VERSION ""

NS_ :

BS_:

BU_: VEH CH Receiver X odin VehicleBus ui

BO_ 965 DIS_alertMatrix3: 8 VEH
 SG_ DIS_a129_epbNotApplied : 0|1@1+ (1,0) [0|0] ""  X
 SG_ DIS_a131_highSpeedWearLimit : 2|1@1+ (1,0) [0|0] ""  X
 SG_ DIS_a133_capacitorOT : 4|1@1+ (1,0) [0|0] ""  X
 SG_ DIS_a134_wheelSpeedIrrational : 5|1@1+ (1,0) [0|0] ""  X
 SG_ DIS_a136_spiError : 7|1@1+ (1,0) [0|0] ""  X
 SG_ DIS_a142_highLashAngle : 13|1@1+ (1,0) [0|0] ""  X
 SG_ DIS_a143_mcuLimitActive : 14|1@1+ (1,0) [0|0] ""  X
 SG_ DIS_a144_configMismatch : 15|1@1+ (1,0) [0|0] ""  X
 SG_ DIS_a147_highTorqueWearLimit : 18|1@1+ (1,0) [0|0] ""  X
 SG_ DIS_a148_overtorqueUsed : 19|1@1+ (1,0) [0|0] ""  X
 SG_ DIS_a149_oilPumpFailure : 20|1@1+ (1,0) [0|0] ""  X
 SG_ DIS_a150_busVD : 21|1@1+ (1,0) [0|0] ""  X
 SG_ DIS_a151_shockTorqueLimiter : 22|1@1+ (1,0) [0|0] ""  X
 SG_ DIS_a152_linError : 23|1@1+ (1,0) [0|0] ""  X
 SG_ DIS_a153_oilPump : 24|1@1+ (1,0) [0|0] ""  X
 SG_ DIS_a154_resolver : 25|1@1+ (1,0) [0|0] ""  X
 SG_ DIS_a155_vcfrontMIA : 26|1@1+ (1,0) [0|0] ""  X
 SG_ DIS_a156_currentObserver : 27|1@1+ (1,0) [0|0] ""  X
 SG_ DIS_a157_rcmMIA : 28|1@1+ (1,0) [0|0] ""  X
 SG_ DIS_a158_ibstMIA : 29|1@1+ (1,0) [0|0] ""  X
 SG_ DIS_a160_busVoltageAnomaly : 31|1@1+ (1,0) [0|0] ""  X
 SG_ DIS_a161_epas3pMIA : 32|1@1+ (1,0) [0|0] ""  X

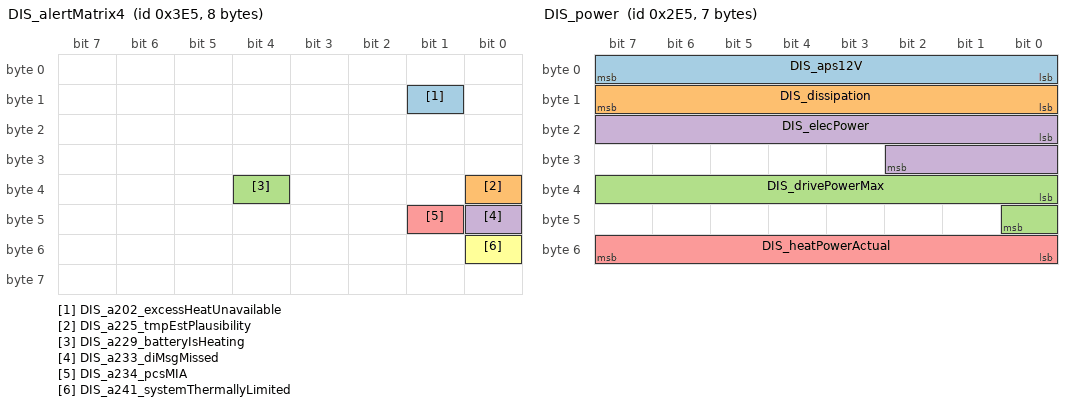
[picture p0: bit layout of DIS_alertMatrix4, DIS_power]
BO_ 997 DIS_alertMatrix4: 8 VEH
 SG_ DIS_a202_excessHeatUnavailable : 9|1@1+ (1,0) [0|0] ""  X
 SG_ DIS_a225_tmpEstPlausibility : 32|1@1+ (1,0) [0|0] ""  X
 SG_ DIS_a229_batteryIsHeating : 36|1@1+ (1,0) [0|0] ""  X
 SG_ DIS_a233_diMsgMissed : 40|1@1+ (1,0) [0|0] ""  X
 SG_ DIS_a234_pcsMIA : 41|1@1+ (1,0) [0|0] ""  X
 SG_ DIS_a241_systemThermallyLimited : 48|1@1+ (1,0) [0|0] ""  X

BO_ 392 DIS_capability2: 2 VEH
 SG_ DIS_heatPowerMax : 8|8@1+ (0.08,0) [0|0] "kW"  X
 SG_ DIS_heatPowerOptimal : 0|8@1+ (0.08,0) [0|0] "kW"  X

BO_ 821 DIS_info: 8 VEH
 SG_ DIS_infoIndex M : 0|8@1+ (1,0) [0|0] ""  X
 SG_ DIS_buildType m10 : 8|3@1+ (1,0) [0|0] ""  X
 SG_ DIS_buildConfigurationId m10 : 16|16@1+ (1,0) [0|0] ""  X
 SG_ DIS_hardwareId m10 : 32|8@1+ (1,0) [0|0] ""  X
 SG_ DIS_componentId m10 : 48|16@1+ (1,0) [0|0] ""  X
 SG_ DIS_pcbaId m11 : 16|8@1+ (1,0) [0|0] ""  X
 SG_ DIS_assemblyId m11 : 24|8@1+ (1,0) [0|0] ""  X
 SG_ DIS_usageId m11 : 32|16@1+ (1,0) [0|0] ""  X
 SG_ DIS_subUsageId m11 : 48|16@1+ (1,0) [0|0] ""  X
 SG_ DIS_applicationSvnRevision m12 : 8|24@1+ (1,0) [0|0] ""  X
 SG_ DIS_applicationSvnUrlHash m12 : 32|32@1+ (1,0) [0|0] ""  X
 SG_ DIS_applicationCrc m13 : 32|32@1+ (1,0) [0|0] ""  X
 SG_ DIS_bootloaderSvnRevision m14 : 8|24@1+ (1,0) [0|0] ""  X
 SG_ DIS_bootloaderSvnUrlHash m14 : 32|32@1+ (1,0) [0|0] ""  X
 SG_ DIS_oilPumpBuildType m16 : 8|3@1+ (1,0) [0|0] ""  X
 SG_ DIS_oilPumpAppCrc m16 : 16|32@1+ (1,0) [0|0] ""  X
 SG_ DIS_appGitHash m17 : 10|54@1+ (4,0) [0|0] ""  X
 SG_ DIS_bootGitHash m18 : 10|54@1+ (4,0) [0|0] ""  X
 SG_ DIS_platformTyp m19 : 8|8@1+ (1,0) [0|0] ""  X
 SG_ DIS_infoBootLdUdsProtocolVersion m20 : 8|8@1+ (1,0) [0|0] ""  X
 SG_ DIS_bootloaderCrc m20 : 32|32@1+ (1,0) [0|0] ""  X
 SG_ DIS_subcomponentGitHash m31 : 10|54@1+ (4,0) [0|0] ""  X

BO_ 741 DIS_power: 7 VEH
 SG_ DIS_aps12V : 0|8@1+ (0.1,0) [0|0] "V"  X
 SG_ DIS_dissipation : 8|8@1+ (125,0) [0|0] "W"  X
 SG_ DIS_drivePowerMax : 32|9@1+ (1,0) [0|0] "kW"  X
 SG_ DIS_elecPower : 16|11@1- (0.5,0) [0|0] "kW"  X
 SG_ DIS_heatPowerActual : 48|8@1+ (0.08,0) [0|0] "kW"  X

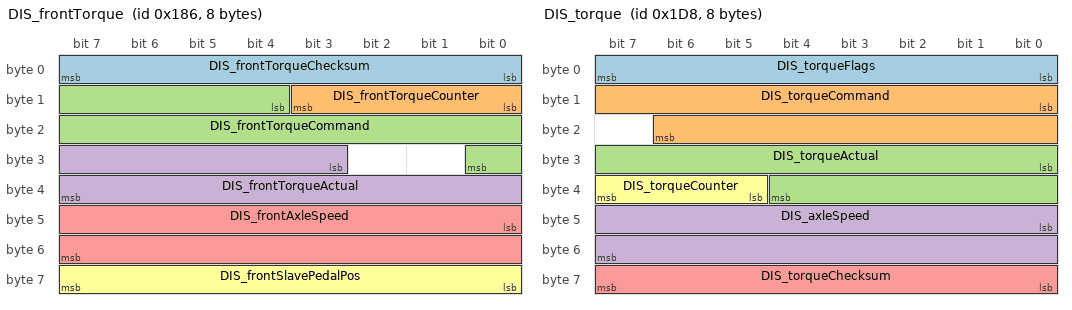
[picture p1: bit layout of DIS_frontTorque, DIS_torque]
BO_ 390 DIS_frontTorque: 8 VEH
 SG_ DIS_frontTorqueChecksum : 0|8@1+ (1,0) [0|0] ""  X
 SG_ DIS_frontTorqueCounter : 8|4@1+ (1,0) [0|0] ""  X
 SG_ DIS_frontTorqueCommand : 12|13@1- (2,0) [0|0] "Nm"  X
 SG_ DIS_frontTorqueActual : 27|13@1- (2,0) [0|0] "Nm"  X
 SG_ DIS_frontAxleSpeed : 40|16@1- (0.1,0) [0|0] "RPM"  X
 SG_ DIS_frontSlavePedalPos : 56|8@1+ (0.4,0) [0|100] "%"  X

BO_ 472 DIS_torque: 8 VEH
 SG_ DIS_torqueFlags : 0|8@1+ (1,0) [0|0] ""  X
 SG_ DIS_torqueCommand : 8|15@1- (0.1,0) [0|0] "Nm"  X
 SG_ DIS_torqueActual : 24|13@1- (2,0) [0|0] "Nm"  X
 SG_ DIS_axleSpeed : 40|16@1- (0.1,0) [0|0] "RPM"  X
 SG_ DIS_torqueChecksum : 56|8@1+ (1,0) [0|0] ""  X
 SG_ DIS_torqueCounter : 37|3@1+ (1,0) [0|0] ""  X

BO_ 854 DI_alertMatrix1: 8 VEH
 SG_ DI_a001_hwPhaseAgateDrive : 0|1@1+ (1,0) [0|0] ""  X
 SG_ DI_a002_hwPhaseBgateDrive : 1|1@1+ (1,0) [0|0] ""  X
 SG_ DI_a003_hwPhaseCgateDrive : 2|1@1+ (1,0) [0|0] ""  X
 SG_ DI_a004_hwPhaseApeak : 3|1@1+ (1,0) [0|0] ""  X
 SG_ DI_a005_hwPhaseBpeak : 4|1@1+ (1,0) [0|0] ""  X
 SG_ DI_a006_hwPhaseCpeak : 5|1@1+ (1,0) [0|0] ""  X
 SG_ DI_a007_hwHvilNotPresent : 6|1@1+ (1,0) [0|0] ""  X
 SG_ DI_a008_hwEncoderA : 7|1@1+ (1,0) [0|0] ""  X
 SG_ DI_a009_hwEncoderB : 8|1@1+ (1,0) [0|0] ""  X
 SG_ DI_a011_swPowerStageNotReady : 10|1@1+ (1,0) [0|0] ""  X
 SG_ DI_a012_accel5VSupply : 11|1@1+ (1,0) [0|0] ""  X
 SG_ DI_a014_activeDamping : 13|1@1+ (1,0) [0|0] ""  X
 SG_ DI_a015_immobilizer : 14|1@1+ (1,0) [0|0] ""  X
 SG_ DI_a016_safeStateApplied : 15|1@1+ (1,0) [0|0] ""  X
 SG_ DI_a017_hwPedalMonitor : 16|1@1+ (1,0) [0|0] ""  X
 SG_ DI_a018_hw12vSupplyUV : 17|1@1+ (1,0) [0|0] ""  X
 SG_ DI_a019_hwAccelPedalPower : 18|1@1+ (1,0) [0|0] ""  X
 SG_ DI_a020_hwMotorEncoder : 19|1@1+ (1,0) [0|0] ""  X
 SG_ DI_a021_hwBusOV : 20|1@1+ (1,0) [0|0] ""  X
 SG_ DI_a022_hw5vSupplyUV : 21|1@1+ (1,0) [0|0] ""  X
 SG_ DI_a023_carNotParked : 22|1@1+ (1,0) [0|0] ""  X
 SG_ DI_a024_selfTest : 23|1@1+ (1,0) [0|0] ""  X
 SG_ DI_a025_phaseApeak : 24|1@1+ (1,0) [0|0] ""  X
 SG_ DI_a026_phaseBpeak : 25|1@1+ (1,0) [0|0] ""  X
 SG_ DI_a027_phaseCpeak : 26|1@1+ (1,0) [0|0] ""  X
 SG_ DI_a028_phaseArms : 27|1@1+ (1,0) [0|0] ""  X
 SG_ DI_a029_phaseBrms : 28|1@1+ (1,0) [0|0] ""  X
 SG_ DI_a030_phaseCrms : 29|1@1+ (1,0) [0|0] ""  X
 SG_ DI_a031_phaseAcurrentOffset : 30|1@1+ (1,0) [0|0] ""  X
 SG_ DI_a032_phaseBcurrentOffset : 31|1@1+ (1,0) [0|0] ""  X
 SG_ DI_a033_phaseAcurrentSensor : 32|1@1+ (1,0) [0|0] ""  X
 SG_ DI_a034_phaseBcurrentSensor : 33|1@1+ (1,0) [0|0] ""  X
 SG_ DI_a035_phaseCurrentBalance : 34|1@1+ (1,0) [0|0] ""  X
 SG_ DI_a036_busOV : 35|1@1+ (1,0) [0|0] ""  X
 SG_ DI_a037_busUV : 36|1@1+ (1,0) [0|0] ""  X
 SG_ DI_a038_busVsensor : 37|1@1+ (1,0) [0|0] ""  X
 SG_ DI_a039_noRegen : 38|1@1+ (1,0) [0|0] ""  X
 SG_ DI_a040_disMIA : 39|1@1+ (1,0) [0|0] ""  X
 SG_ DI_a041_driverBrakeApplyCheck : 40|1@1+ (1,0) [0|0] ""  X
 SG_ DI_a042_inletSensor : 41|1@1+ (1,0) [0|0] ""  X
 SG_ DI_a043_outletOT : 42|1@1+ (1,0) [0|0] ""  X
 SG_ DI_a044_outletUT : 43|1@1+ (1,0) [0|0] ""  X
 SG_ DI_a045_outletSensor : 44|1@1+ (1,0) [0|0] ""  X
 SG_ DI_a046_statorOT : 45|1@1+ (1,0) [0|0] ""  X
 SG_ DI_a047_statorSensor1 : 46|1@1+ (1,0) [0|0] ""  X
 SG_ DI_a050_noStatorSensor : 49|1@1+ (1,0) [0|0] ""  X
 SG_ DI_a051_batteryOvercurrent : 50|1@1+ (1,0) [0|0] ""  X
 SG_ DI_a054_driveInverterOT : 53|1@1+ (1,0) [0|0] ""  X
 SG_ DI_a055_trqCrossCheck : 54|1@1+ (1,0) [0|0] ""  X
 SG_ DI_a056_ambientOT : 55|1@1+ (1,0) [0|0] ""  X
 SG_ DI_a057_ambientUT : 56|1@1+ (1,0) [0|0] ""  X
 SG_ DI_a058_ambientSensor : 57|1@1+ (1,0) [0|0] ""  X
 SG_ DI_a059_heatsinkOT : 58|1@1+ (1,0) [0|0] ""  X
 SG_ DI_a060_heatsinkUT : 59|1@1+ (1,0) [0|0] ""  X
 SG_ DI_a061_heatsinkSensor : 60|1@1+ (1,0) [0|0] ""  X
 SG_ DI_a062_systemLimpMode : 61|1@1+ (1,0) [0|0] ""  X
 SG_ DI_a063_systemGracefulPowerOff : 62|1@1+ (1,0) [0|0] ""  X
 SG_ DI_a064_torqueIntervention : 63|1@1+ (1,0) [0|0] ""  X

BO_ 855 DI_alertMatrix2: 8 VEH
 SG_ DI_a065_canHardwareBusB : 0|1@1+ (1,0) [0|0] ""  X
 SG_ DI_a066_canDataBusB : 1|1@1+ (1,0) [0|0] ""  X
 SG_ DI_a067_canOverrunBusB : 2|1@1+ (1,0) [0|0] ""  X
 SG_ DI_a070_12vSupplySensor : 5|1@1+ (1,0) [0|0] ""  X
 SG_ DI_a071_busDisconnected : 6|1@1+ (1,0) [0|0] ""  X
 SG_ DI_a072_gateDriveFaultCounter : 7|1@1+ (1,0) [0|0] ""  X
 SG_ DI_a073_motorSpeed : 8|1@1+ (1,0) [0|0] ""  X
 SG_ DI_a074_motorEncoder : 9|1@1+ (1,0) [0|0] ""  X
 SG_ DI_a075_motorSpeedMismatch : 10|1@1+ (1,0) [0|0] ""  X
 SG_ DI_a076_12vSupplyOV : 11|1@1+ (1,0) [0|0] ""  X
 SG_ DI_a077_12vSupplyUV : 12|1@1+ (1,0) [0|0] ""  X
 SG_ DI_a078_adcRefLow : 13|1@1+ (1,0) [0|0] ""  X
 SG_ DI_a079_adcRefHigh : 14|1@1+ (1,0) [0|0] ""  X
 SG_ DI_a080_accelSynch : 15|1@1+ (1,0) [0|0] ""  X
 SG_ DI_a081_accelTrack1 : 16|1@1+ (1,0) [0|0] ""  X
 SG_ DI_a082_accelTrack2 : 17|1@1+ (1,0) [0|0] ""  X
 SG_ DI_a083_brakePedalSensor : 18|1@1+ (1,0) [0|0] ""  X
 SG_ DI_a085_proximityInEnable : 20|1@1+ (1,0) [0|0] ""  X
 SG_ DI_a086_hvilNotPresent : 21|1@1+ (1,0) [0|0] ""  X
 SG_ DI_a087_gtwMIA : 22|1@1+ (1,0) [0|0] ""  X
 SG_ DI_a088_uiMIA : 23|1@1+ (1,0) [0|0] ""  X
 SG_ DI_a089_sccmMIA : 24|1@1+ (1,0) [0|0] ""  X
 SG_ DI_a090_pmMIA : 25|1@1+ (1,0) [0|0] ""  X
 SG_ DI_a091_espMIA : 26|1@1+ (1,0) [0|0] ""  X
 SG_ DI_a092_bmsMIA : 27|1@1+ (1,0) [0|0] ""  X
 SG_ DI_a093_canHardwareBusA : 28|1@1+ (1,0) [0|0] ""  X
 SG_ DI_a094_canDataBusA : 29|1@1+ (1,0) [0|0] ""  X
 SG_ DI_a095_canOverrunBusA : 30|1@1+ (1,0) [0|0] ""  X
 SG_ DI_a096_memoryError : 31|1@1+ (1,0) [0|0] ""  X
 SG_ DI_a097_eepromError : 32|1@1+ (1,0) [0|0] ""  X
 SG_ DI_a098_intTimeTooLong : 33|1@1+ (1,0) [0|0] ""  X
 SG_ DI_a099_threadOverrun : 34|1@1+ (1,0) [0|0] ""  X
 SG_ DI_a100_assertion : 35|1@1+ (1,0) [0|0] ""  X
 SG_ DI_a103_lowFlow : 38|1@1+ (1,0) [0|0] ""  X
 SG_ DI_a104_proximityIrrational : 39|1@1+ (1,0) [0|0] ""  X
 SG_ DI_a105_cpMIA : 40|1@1+ (1,0) [0|0] ""  X
 SG_ DI_a106_absMIA : 41|1@1+ (1,0) [0|0] ""  X
 SG_ DI_a108_stateTrans : 43|1@1+ (1,0) [0|0] ""  X
 SG_ DI_a109_cruiseMIA : 44|1@1+ (1,0) [0|0] ""  X
 SG_ DI_a110_brakeMIA : 45|1@1+ (1,0) [0|0] ""  X
 SG_ DI_a112_noPhaseCurrent : 47|1@1+ (1,0) [0|0] ""  X
 SG_ DI_a113_noFuncHeatsinkSensor : 48|1@1+ (1,0) [0|0] ""  X
 SG_ DI_a114_noMotorSpeed : 49|1@1+ (1,0) [0|0] ""  X
 SG_ DI_a115_heatsinkTempImbalance : 50|1@1+ (1,0) [0|0] ""  X
 SG_ DI_a116_powerConvIrrational : 51|1@1+ (1,0) [0|0] ""  X
 SG_ DI_a117_diMIA : 52|1@1+ (1,0) [0|0] ""  X
 SG_ DI_a121_motorControlRegulation : 56|1@1+ (1,0) [0|0] ""  X
 SG_ DI_a122_highStackUsage : 57|1@1+ (1,0) [0|0] ""  X
 SG_ DI_a123_lossMotorControl : 58|1@1+ (1,0) [0|0] ""  X
 SG_ DI_a124_cruiseFault : 59|1@1+ (1,0) [0|0] ""  X
 SG_ DI_a125_noBatteryPower : 60|1@1+ (1,0) [0|0] ""  X
 SG_ DI_a126_limpMode : 61|1@1+ (1,0) [0|0] ""  X
 SG_ DI_a127_gracefulPowerOff : 62|1@1+ (1,0) [0|0] ""  X

BO_ 858 DI_alertMatrix3: 8 VEH
 SG_ DI_a129_epbNotApplied : 0|1@1+ (1,0) [0|0] ""  X
 SG_ DI_a130_aebFault : 1|1@1+ (1,0) [0|0] ""  X
 SG_ DI_a131_highSpeedWearLimit : 2|1@1+ (1,0) [0|0] ""  X
 SG_ DI_a133_capacitorOT : 4|1@1+ (1,0) [0|0] ""  X
 SG_ DI_a134_wheelSpeedIrrational : 5|1@1+ (1,0) [0|0] ""  X
 SG_ DI_a135_vehicleHoldFault : 6|1@1+ (1,0) [0|0] ""  X
 SG_ DI_a136_spiError : 7|1@1+ (1,0) [0|0] ""  X
 SG_ DI_a137_noCapableDriveUnits : 8|1@1+ (1,0) [0|0] ""  X
 SG_ DI_a138_frontUnitDisabled : 9|1@1+ (1,0) [0|0] ""  X
 SG_ DI_a139_rearUnitDisabled : 10|1@1+ (1,0) [0|0] ""  X
 SG_ DI_a141_dasMIA : 12|1@1+ (1,0) [0|0] ""  X
 SG_ DI_a142_highLashAngle : 13|1@1+ (1,0) [0|0] ""  X
 SG_ DI_a143_mcuLimitActive : 14|1@1+ (1,0) [0|0] ""  X
 SG_ DI_a144_configMismatch : 15|1@1+ (1,0) [0|0] ""  X
 SG_ DI_a145_pbrkPanicSkid : 16|1@1+ (1,0) [0|0] ""  X
 SG_ DI_a146_pbrkPanicEpbFault : 17|1@1+ (1,0) [0|0] ""  X
 SG_ DI_a147_highTorqueWearLimit : 18|1@1+ (1,0) [0|0] ""  X
 SG_ DI_a148_overtorqueUsed : 19|1@1+ (1,0) [0|0] ""  X
 SG_ DI_a149_oilPumpFailure : 20|1@1+ (1,0) [0|0] ""  X
 SG_ DI_a150_busVD : 21|1@1+ (1,0) [0|0] ""  X
 SG_ DI_a151_shockTorqueLimiter : 22|1@1+ (1,0) [0|0] ""  X
 SG_ DI_a152_linError : 23|1@1+ (1,0) [0|0] ""  X
 SG_ DI_a153_oilPump : 24|1@1+ (1,0) [0|0] ""  X
 SG_ DI_a154_resolver : 25|1@1+ (1,0) [0|0] ""  X
 SG_ DI_a155_vcfrontMIA : 26|1@1+ (1,0) [0|0] ""  X
 SG_ DI_a156_currentObserver : 27|1@1+ (1,0) [0|0] ""  X
 SG_ DI_a157_rcmMIA : 28|1@1+ (1,0) [0|0] ""  X
 SG_ DI_a158_ibstMIA : 29|1@1+ (1,0) [0|0] ""  X
 SG_ DI_a159_cruiseSelfCheck : 30|1@1+ (1,0) [0|0] ""  X
 SG_ DI_a160_busVoltageAnomaly : 31|1@1+ (1,0) [0|0] ""  X
 SG_ DI_a161_epas3pMIA : 32|1@1+ (1,0) [0|0] ""  X
 SG_ DI_a162_shiftDenied : 33|1@1+ (1,0) [0|0] ""  X
 SG_ DI_a163_unparkReq : 34|1@1+ (1,0) [0|0] ""  X
 SG_ DI_a164_brakeOverride : 35|1@1+ (1,0) [0|0] ""  X
 SG_ DI_a165_cruiseCancelled : 36|1@1+ (1,0) [0|0] ""  X
 SG_ DI_a166_driverLeft : 37|1@1+ (1,0) [0|0] ""  X
 SG_ DI_a167_keyNotAuthenticated : 38|1@1+ (1,0) [0|0] ""  X
 SG_ DI_a168_proximityDriveDenial : 39|1@1+ (1,0) [0|0] ""  X
 SG_ DI_a169_regenOffOverride : 40|1@1+ (1,0) [0|0] ""  X
 SG_ DI_a170_pedalFoul : 41|1@1+ (1,0) [0|0] ""  X
 SG_ DI_a171_driveRailNotRequested : 42|1@1+ (1,0) [0|0] ""  X
 SG_ DI_a172_accelPressedInNP : 43|1@1+ (1,0) [0|0] ""  X
 SG_ DI_a173_bothPedalsPressed : 44|1@1+ (1,0) [0|0] ""  X
 SG_ DI_a174_notOkToStartDrive : 45|1@1+ (1,0) [0|0] ""  X
 SG_ DI_a175_crsNotAvailable : 46|1@1+ (1,0) [0|0] ""  X
 SG_ DI_a176_EBRreleased : 47|1@1+ (1,0) [0|0] ""  X
 SG_ DI_a177_tireFitmentChanged : 48|1@1+ (1,0) [0|0] ""  X
 SG_ DI_a180_crsSeatbeltUnbuckled : 51|1@1+ (1,0) [0|0] ""  X
 SG_ DI_a181_rearMotorMode : 52|1@1+ (1,0) [0|0] ""  X
 SG_ DI_a182_frontMotorMode : 53|1@1+ (1,0) [0|0] ""  X
 SG_ DI_a183_holdReleaseRqrd : 54|1@1+ (1,0) [0|0] ""  X
 SG_ DI_a184_autoparkCanceled : 55|1@1+ (1,0) [0|0] ""  X
 SG_ DI_a185_autoparkAborted : 56|1@1+ (1,0) [0|0] ""  X
 SG_ DI_a186_brakeStand : 57|1@1+ (1,0) [0|0] ""  X
 SG_ DI_a187_pedalMisapplication : 58|1@1+ (1,0) [0|0] ""  X
 SG_ DI_a189_garageShiftWithPedal : 60|1@1+ (1,0) [0|0] ""  X
 SG_ DI_a191_brakeShiftReq : 62|1@1+ (1,0) [0|0] ""  X
 SG_ DI_a192_invalidOdometer : 63|1@1+ (1,0) [0|0] ""  X

BO_ 859 DI_alertMatrix4: 8 VEH
 SG_ DI_a193_vdcEspBrakeTorqueFr : 0|1@1+ (1,0) [0|0] ""  X
 SG_ DI_a194_vdcEspBrakeTorqueRe : 1|1@1+ (1,0) [0|0] ""  X
 SG_ DI_a195_vdcEspSlipFr : 2|1@1+ (1,0) [0|0] ""  X
 SG_ DI_a196_vdcEspSlipRe : 3|1@1+ (1,0) [0|0] ""  X
 SG_ DI_a197_vdcEspWheelSaturations : 4|1@1+ (1,0) [0|0] ""  X
 SG_ DI_a198_vdcEspMCPressAndSteering : 5|1@1+ (1,0) [0|0] ""  X
 SG_ DI_a199_vdcFaulted : 6|1@1+ (1,0) [0|0] ""  X
 SG_ DI_a200_vdcModelBasedPlausibilit : 7|1@1+ (1,0) [0|0] ""  X
 SG_ DI_a201_regenLimited : 8|1@1+ (1,0) [0|0] ""  X
 SG_ DI_a202_excessHeatUnavailable : 9|1@1+ (1,0) [0|0] ""  X
 SG_ DI_a203_TCReducedByADD : 10|1@1+ (1,0) [0|0] ""  X
 SG_ DI_a204_vdcRcmLongitudinal : 11|1@1+ (1,0) [0|0] ""  X
 SG_ DI_a205_vdcRcmLateral : 12|1@1+ (1,0) [0|0] ""  X
 SG_ DI_a206_vdcRcmVertical : 13|1@1+ (1,0) [0|0] ""  X
 SG_ DI_a207_vdcPowertrainTorqueFr : 14|1@1+ (1,0) [0|0] ""  X
 SG_ DI_a208_vdcPowertrainTorqueRe : 15|1@1+ (1,0) [0|0] ""  X
 SG_ DI_a209_vdcVehicleSpeed : 16|1@1+ (1,0) [0|0] ""  X
 SG_ DI_a210_vdcOtherControllerStates : 17|1@1+ (1,0) [0|0] ""  X
 SG_ DI_a211_vdcMotorSpeeds : 18|1@1+ (1,0) [0|0] ""  X
 SG_ DI_a212_velEstWheelSpeedCGFr : 19|1@1+ (1,0) [0|0] ""  X
 SG_ DI_a213_velEstWheelSpeedCGRe : 20|1@1+ (1,0) [0|0] ""  X
 SG_ DI_a214_velEstWheelSpeedNonCGFr : 21|1@1+ (1,0) [0|0] ""  X
 SG_ DI_a215_velEstWheelSpeedNonCGRe : 22|1@1+ (1,0) [0|0] ""  X
 SG_ DI_a216_vdcMBPAlmostTripped : 23|1@1+ (1,0) [0|0] ""  X
 SG_ DI_a217_vdcOutputIrrational : 24|1@1+ (1,0) [0|0] ""  X
 SG_ DI_a218_vdcOSPreControlActive : 25|1@1+ (1,0) [0|0] ""  X
 SG_ DI_a219_vdcOversteerdMzActive : 26|1@1+ (1,0) [0|0] ""  X
 SG_ DI_a220_vdcUndersteerDecelActive : 27|1@1+ (1,0) [0|0] ""  X
 SG_ DI_a221_vdcUndersteerdMzActive : 28|1@1+ (1,0) [0|0] ""  X
 SG_ DI_a222_vdcDisabled : 29|1@1+ (1,0) [0|0] ""  X
 SG_ DI_a223_tractionControlDisabled : 30|1@1+ (1,0) [0|0] ""  X
 SG_ DI_a224_brakeOverTemp : 31|1@1+ (1,0) [0|0] ""  X
 SG_ DI_a225_tmpEstPlausibility : 32|1@1+ (1,0) [0|0] ""  X
 SG_ DI_a226_sysStartConditionNotMet : 33|1@1+ (1,0) [0|0] ""  X
 SG_ DI_a227_contactorsNotClosed : 34|1@1+ (1,0) [0|0] ""  X
 SG_ DI_a228_brakeTempEstUnavailable : 35|1@1+ (1,0) [0|0] ""  X
 SG_ DI_a229_batteryIsHeating : 36|1@1+ (1,0) [0|0] ""  X
 SG_ DI_a230_cmpMIA : 37|1@1+ (1,0) [0|0] ""  X
 SG_ DI_a231_ptcMIA : 38|1@1+ (1,0) [0|0] ""  X
 SG_ DI_a232_velocityEstimatorDegrade : 39|1@1+ (1,0) [0|0] ""  X
 SG_ DI_a233_diMsgMissed : 40|1@1+ (1,0) [0|0] ""  X
 SG_ DI_a234_pcsMIA : 41|1@1+ (1,0) [0|0] ""  X
 SG_ DI_a235_trackModeActive : 42|1@1+ (1,0) [0|0] ""  X
 SG_ DI_a238_brakeOverTempBrembo : 45|1@1+ (1,0) [0|0] ""  X
 SG_ DI_a239_neutralRequestByPM : 46|1@1+ (1,0) [0|0] ""  X
 SG_ DI_a241_systemThermallyLimited : 48|1@1+ (1,0) [0|0] ""  X

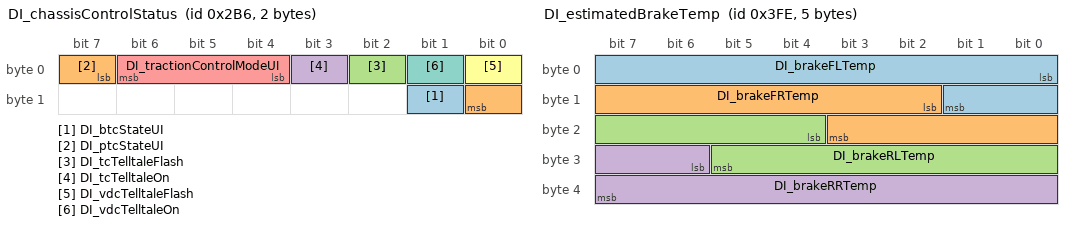
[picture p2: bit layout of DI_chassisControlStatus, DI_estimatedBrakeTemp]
BO_ 694 DI_chassisControlStatus: 2 VEH
 SG_ DI_btcStateUI : 9|1@1+ (1,0) [0|0] ""  X
 SG_ DI_ptcStateUI : 7|2@1+ (1,0) [0|0] ""  X
 SG_ DI_tcTelltaleFlash : 2|1@1+ (1,0) [0|0] ""  X
 SG_ DI_tcTelltaleOn : 3|1@1+ (1,0) [0|0] ""  X
 SG_ DI_tractionControlModeUI : 4|3@1+ (1,0) [0|0] ""  X
 SG_ DI_vdcTelltaleFlash : 0|1@1+ (1,0) [0|0] ""  X
 SG_ DI_vdcTelltaleOn : 1|1@1+ (1,0) [0|0] ""  X

BO_ 2005 DI_debug: 8 VEH
 SG_ DI_debugSelector M : 0|8@1+ (1,0) [0|0] ""  X
 SG_ DI_motorType m128 : 8|5@1+ (1,0) [0|0] ""  X
 SG_ DI_cpu1HzMin m128 : 16|8@1+ (0.4,0) [0|0] "%"  X
 SG_ DI_cpu1HzMax m128 : 24|8@1+ (0.4,0) [0|0] "%"  X
 SG_ DI_cpu1HzAvg m128 : 32|8@1+ (0.4,0) [0|0] "%"  X
 SG_ DI_muSurfHigh m2 : 8|8@1+ (0.005,0) [0|0] "N/N"  X
 SG_ DI_brakeCpScale m2 : 16|9@1- (0.01,0.5) [0|0] "N/N"  X
 SG_ DI_pedalPosFilt m2 : 32|8@1+ (0.4,0) [0|0] "%"  X
 SG_ DI_cpuIDWord0 m131 : 16|16@1+ (1,0) [0|0] ""  X
 SG_ DI_crc m131 : 32|32@1+ (1,0) [0|0] ""  X
 SG_ DI_cpuIDWord1 m132 : 16|16@1+ (1,0) [0|0] ""  X
 SG_ DI_cpuIDWord2 m132 : 32|16@1+ (1,0) [0|0] ""  X
 SG_ DI_cpuIDWord3 m132 : 48|16@1+ (1,0) [0|0] ""  X
 SG_ DI_offsetA m32 : 8|8@1- (0.1,0) [0|0] "A"  X
 SG_ DI_motorIA m32 : 16|16@1+ (0.1,0) [0|0] "A"  X
 SG_ DI_motorIB m32 : 32|16@1+ (0.1,0) [0|0] "A"  X
 SG_ DI_motorIC m32 : 48|16@1+ (0.1,0) [0|0] "A"  X
 SG_ DI_offsetB m33 : 8|8@1- (0.1,0) [0|0] "A"  X
 SG_ DI_statorIDref m33 : 16|16@1- (0.1,0) [0|0] "A"  X
 SG_ DI_statorIDfdb m33 : 32|16@1- (0.1,0) [0|0] "A"  X
 SG_ DI_torquePerAmp m33 : 48|16@1+ (0.0001,0) [0|0] "Nm/A"  X
 SG_ DI_rsScale m34 : 8|8@1+ (0.01,0) [0|0] "scale"  X
 SG_ DI_statorIQref m34 : 16|16@1- (0.1,0) [0|0] "A"  X
 SG_ DI_statorIQfdb m34 : 32|16@1- (0.1,0) [0|0] "A"  X
 SG_ DI_motorV m34 : 48|16@1+ (2E-005,0) [0|0] "mindex"  X
 SG_ DI_tqScaleDifferential m35 : 8|8@1+ (0.4,0) [0|0] "%"  X
 SG_ DI_statorFluxRef m35 : 16|16@1+ (0.0001,0) [0|0] "Wb"  X
 SG_ DI_statorFluxFdb m35 : 32|16@1+ (0.0001,0) [0|0] "Wb"  X
 SG_ DI_systemTorqueCommand m35 : 48|16@1- (0.035,0) [0|0] "Nm"  X
 SG_ DI_lmScale m36 : 8|8@1+ (0.004,0) [0|0] "scale"  X
 SG_ DI_statorVQ m36 : 16|16@1- (4E-005,0) [0|0] "mindex"  X
 SG_ DI_statorVD m36 : 32|16@1- (4E-005,0) [0|0] "mindex"  X
 SG_ DI_peakFlux m36 : 48|16@1+ (0.0001,0) [0|0] "Wb"  X
 SG_ DI_gainScale m37 : 8|8@1+ (0.01,0) [0|0] "scale"  X
 SG_ DI_dcCableCurrentEst m37 : 16|16@1- (0.1,0) [0|0] "A"  X
 SG_ DI_loadAngleMargin m37 : 32|16@1- (0.0003,0) [0|0] "rad"  X
 SG_ DI_internalAngleFilt m37 : 48|16@1+ (0.0003,0) [0|0] "rad"  X
 SG_ DI_ssmState m38 : 8|4@1+ (1,0) [0|0] ""  X
 SG_ DI_usmState m38 : 12|3@1+ (1,0) [0|0] ""  X
 SG_ DI_peakIQref m38 : 16|16@1+ (0.1,0) [0|0] "A"  X
 SG_ DI_motorIAavg m38 : 32|16@1- (0.1,0) [0|0] "A"  X
 SG_ DI_motorIBavg m38 : 48|16@1- (0.1,0) [0|0] "A"  X
 SG_ DI_tqSatThermal m39 : 8|8@1+ (0.4,0) [0|0] "%"  X
 SG_ DI_pwrSatMaxDischargePower m39 : 16|8@1+ (0.4,0) [0|0] "%"  X
 SG_ DI_pwrSatMaxRegenPower m39 : 24|8@1+ (0.4,0) [0|0] "%"  X
 SG_ DI_tqSatMotorVoltage m39 : 32|8@1+ (0.4,0) [0|0] "%"  X
 SG_ DI_tqSatMotorCurrent m39 : 40|8@1+ (0.4,0) [0|0] "%"  X
 SG_ DI_pwrSatMaxBusVoltage m39 : 48|8@1+ (0.4,0) [0|0] "%"  X
 SG_ DI_pwrSatMinBusVoltage m39 : 56|8@1+ (0.4,0) [0|0] "%"  X
 SG_ DI_pwrSatDischargeCurrent m40 : 8|8@1+ (0.4,0) [0|0] "%"  X
 SG_ DI_tcMaxRequest m40 : 16|8@1+ (5,0) [0|0] "Nm"  X
 SG_ DI_tcMinRequest m40 : 24|8@1+ (5,0) [0|0] "Nm"  X
 SG_ DI_tqSatUiDriveTorque m40 : 32|8@1+ (0.4,0) [0|0] "%"  X
 SG_ DI_tqSatUiRegenTorque m40 : 40|8@1+ (0.4,0) [0|0] "%"  X
 SG_ DI_tqScaleMaxMotorSpeed m40 : 48|8@1+ (0.4,0) [0|0] "%"  X
 SG_ DI_tqScaleShift m40 : 56|8@1+ (0.4,0) [0|0] "%"  X
 SG_ DI_veMassInvRaw m41 : 8|12@1+ (1E-007,0.0001) [0|0] "1/kg"  X
 SG_ DI_veResForce m41 : 20|12@1- (0.0005,0) [0|0] "G"  X
 SG_ DI_currentLimit m41 : 32|16@1+ (0.1,0) [0|0] "A"  X
 SG_ DI_wasteCurrentLimit m41 : 48|16@1+ (0.1,0) [0|0] "A"  X
 SG_ DI_pwrSatChargeCurrent m42 : 8|8@1+ (0.4,0) [0|0] "%"  X
 SG_ DI_fluxState m42 : 16|4@1+ (1,0) [0|0] ""  X
 SG_ DI_llsScale m42 : 24|8@1+ (0.004,0) [0|0] "scale"  X
 SG_ DI_llrScale m42 : 32|8@1+ (0.015,0) [0|0] "scale"  X
 SG_ DI_loadAngle m42 : 40|16@1- (0.0003,0) [0|0] "rad"  X
 SG_ DI_brakeSwitchNO m42 : 62|1@1+ (1,0) [0|0] ""  X
 SG_ DI_brakeSwitchNC m42 : 63|1@1+ (1,0) [0|0] ""  X
 SG_ DI_sysPedalMinTorque m44 : 8|14@1+ (0.1,-1638.3) [0|0] "Nm"  X
 SG_ DI_sysPedalMaxTorque m44 : 22|14@1+ (0.1,0) [0|0] "Nm"  X
 SG_ DI_sysPostPedalMinTorque m44 : 36|14@1+ (0.1,-1638.3) [0|0] "Nm"  X
 SG_ DI_sysPostPedalMaxTorque m44 : 50|14@1+ (0.1,0) [0|0] "Nm"  X
 SG_ DI_aebFaultReason m45 : 16|4@1+ (1,0) [0|0] ""  X
 SG_ DI_aebUnavailableReason m45 : 24|4@1+ (1,0) [0|0] ""  X
 SG_ DI_aebCancelReason m45 : 32|8@1+ (1,0) [0|0] ""  X
 SG_ DI_oilPumpPhaseCurrent m46 : 8|8@1+ (0.1,0) [0|0] "A"  X
 SG_ DI_oilPumpPhaseVoltage m46 : 16|8@1+ (0.1,0) [0|0] "V"  X
 SG_ DI_oilPumpPhaseAdvance m46 : 24|8@1+ (0.4,0) [0|0] "%"  X
 SG_ DI_oilPumpPressureEstimate m46 : 32|8@1+ (2,0) [0|0] "kPa"  X
 SG_ DI_rotorFlux m47 : 16|16@1+ (0.0001,0) [0|0] "Wb"  X
 SG_ DI_dcCableHeat m47 : 32|16@1+ (0.001,0) [0|0] "kA2s"  X
 SG_ DI_magnetTempEst m47 : 48|8@1+ (1,-40) [0|0] "DegC"  X
 SG_ DI_magnetTempEst_SFO m47 : 56|8@1+ (1,-40) [0|0] "DegC"  X
 SG_ DI_resolverOffsetCos m48 : 8|8@1+ (0.015,0) [0|0] "V"  X
 SG_ DI_resolverOffsetSin m48 : 16|8@1+ (0.015,0) [0|0] "V"  X
 SG_ DI_resolverPhaseOffset m48 : 24|8@1+ (0.1,7.5) [0|0] "us"  X
 SG_ DI_resolverCommonGain m48 : 32|8@1+ (0.025,0) [0|0] "1"  X
 SG_ DI_resolverReady m48 : 40|1@1+ (1,0) [0|0] ""  X
 SG_ DI_resolverNoCarrier m48 : 41|1@1+ (1,0) [0|0] ""  X
 SG_ DI_resolverNoPhaseLock m48 : 42|1@1+ (1,0) [0|0] ""  X
 SG_ DI_resolverClaMIA m48 : 43|1@1+ (1,0) [0|0] ""  X
 SG_ DI_soptTimeToTrip m49 : 8|8@1+ (0.05,0) [0|0] "ms"  X
 SG_ DI_soptTripDelay m49 : 16|8@1+ (0.05,0) [0|0] "ms"  X
 SG_ DI_soptTimeToOff m49 : 24|11@1+ (0.05,0) [0|0] "ms"  X
 SG_ DI_soptMaxCurrentMagSqrd m49 : 40|16@1+ (100,0) [0|0] "A2"  X
 SG_ DI_gateDriveSupplyState m50 : 8|2@1+ (1,0) [0|0] ""  X
 SG_ DI_gateDriveState m50 : 10|3@1+ (1,0) [0|0] ""  X
 SG_ DI_powerStageSafeState m50 : 13|2@1+ (1,0) [0|0] ""  X
 SG_ DI_sysHeatPowerOptimal m50 : 16|8@1+ (0.08,0) [0|0] "kW"  X
 SG_ DI_brkStState m50 : 24|3@1+ (1,0) [0|0] ""  X
 SG_ DI_torquePedalMin m51 : 16|12@1+ (2,-7500) [0|0] "Nm"  X
 SG_ DI_torquePedalMax m51 : 28|12@1+ (2,0) [0|0] "Nm"  X
 SG_ DI_torquePostPedalMin m51 : 40|12@1+ (2,-7500) [0|0] "Nm"  X
 SG_ DI_torquePostPedalMax m51 : 52|12@1+ (2,0) [0|0] "Nm"  X
 SG_ DI_dcCapTemp m64 : 8|8@1+ (1,-40) [0|0] "DegC"  X
 SG_ DI_busbarTemp m64 : 16|8@1+ (1,-40) [0|0] "DegC"  X
 SG_ DI_pcsTemp m64 : 24|8@1+ (1,-40) [0|0] "DegC"  X
 SG_ DI_statorTemp1 m64 : 32|8@1+ (1,-40) [0|0] "DegC"  X
 SG_ DI_statorTemp2 m64 : 40|8@1+ (1,-40) [0|0] "DegC"  X
 SG_ DI_immobilizerCondition m64 : 63|1@1+ (1,0) [0|0] ""  X
 SG_ DI_velocityEstimatorState m65 : 8|3@1+ (1,0) [0|0] ""  X
 SG_ DI_hvilCurrent m65 : 16|10@1+ (0.025,0) [0|0] "mA"  X
 SG_ DI_hvilCmVoltage m65 : 32|10@1+ (0.02,0) [0|0] "V"  X
 SG_ DI_cpu10HzMin m66 : 8|8@1+ (0.4,0) [0|0] "%"  X
 SG_ DI_cpu10HzMax m66 : 16|8@1+ (0.4,0) [0|0] "%"  X
 SG_ DI_cpu10HzAvg m66 : 24|8@1+ (0.4,0) [0|0] "%"  X
 SG_ DI_cpu100HzMin m66 : 32|8@1+ (0.4,0) [0|0] "%"  X
 SG_ DI_cpu100HzMax m66 : 40|8@1+ (0.4,0) [0|0] "%"  X
 SG_ DI_cpu100HzAvg m66 : 48|8@1+ (0.4,0) [0|0] "%"  X
 SG_ DI_module10HzStack m66 : 56|8@1+ (0.4,0) [0|0] "%"  X
 SG_ DI_cpu1kHzMin m67 : 8|8@1+ (0.4,0) [0|0] "%"  X
 SG_ DI_cpu1kHzMax m67 : 16|8@1+ (0.4,0) [0|0] "%"  X
 SG_ DI_cpu1kHzAvg m67 : 24|8@1+ (0.4,0) [0|0] "%"  X
 SG_ DI_cpu20kHzMin m67 : 32|8@1+ (0.4,0) [0|0] "%"  X
 SG_ DI_cpu20kHzMax m67 : 40|8@1+ (0.4,0) [0|0] "%"  X
 SG_ DI_cpu20kHzAvg m67 : 48|8@1+ (0.4,0) [0|0] "%"  X
 SG_ DI_controlStack m67 : 56|8@1+ (0.4,0) [0|0] "%"  X
 SG_ DI_systemStack m68 : 8|8@1+ (0.4,0) [0|0] "%"  X
 SG_ DI_idleStack m68 : 16|8@1+ (0.4,0) [0|0] "%"  X
 SG_ DI_decodeHardwareStack m68 : 24|8@1+ (0.4,0) [0|0] "%"  X
 SG_ DI_eepromStack m68 : 32|8@1+ (0.4,0) [0|0] "%"  X
 SG_ DI_udsStack m68 : 40|8@1+ (0.4,0) [0|0] "%"  X
 SG_ DI_xcpStack m68 : 48|8@1+ (0.4,0) [0|0] "%"  X
 SG_ DI_immobilizerStack m68 : 56|8@1+ (0.4,0) [0|0] "%"  X
 SG_ DI_hwFaultCounter m69 : 8|4@1+ (1,0) [0|0] ""  X
 SG_ DI_driveUnitOdometer m69 : 32|32@1+ (10,0) [0|0] "rev"  X
 SG_ DI_phaseOutBusbarTemp m70 : 8|8@1+ (1,-40) [0|0] "DegC"  X
 SG_ DI_phaseOutBusbarWeldTemp m70 : 16|8@1+ (1,-40) [0|0] "DegC"  X
 SG_ DI_phaseOutLugTemp m70 : 24|8@1+ (1,-40) [0|0] "DegC"  X
 SG_ DI_dcLinkCapTemp m70 : 32|8@1+ (1,-40) [0|0] "DegC"  X
 SG_ DI_hvDcCableTemp m70 : 40|8@1+ (1,-40) [0|0] "DegC"  X
 SG_ DI_negDcBusbarTemp m70 : 48|8@1+ (1,-40) [0|0] "DegC"  X
 SG_ DI_posDcBusbarTemp m70 : 56|8@1+ (1,-40) [0|0] "DegC"  X
 SG_ DI_statorEndWindingTemp m72 : 8|8@1+ (1,-40) [0|0] "DegC"  X
 SG_ DI_rotorMaxMagnetTemp m72 : 16|8@1+ (1,-40) [0|0] "DegC"  X

BO_ 1879 ID757DIF_debug: 8 VehicleBus
 SG_ DIF_debugSelector M : 0|8@1+ (1,0) [0|255] ""  Receiver
 SG_ DIF_brakeSwitchNC m42 : 63|1@1+ (1,0) [0|1] ""  Receiver
 SG_ DIF_brakeSwitchNO m42 : 62|1@1+ (1,0) [0|1] ""  Receiver
 SG_ DIF_busbarTemp m64 : 16|8@1+ (1,-40) [-40|215] "C"  Receiver
 SG_ DIF_controlStack m67 : 40|8@1+ (0.4,0) [0|100] "%"  Receiver
 SG_ DIF_cpu100HzAvg m66 : 32|8@1+ (0.4,0) [0|102] "%"  Receiver
 SG_ DIF_cpu100HzMin m66 : 24|8@1+ (0.4,0) [0|102] "%"  Receiver
 SG_ DIF_cpu10HzAvg m66 : 16|8@1+ (0.4,0) [0|102] "%"  Receiver
 SG_ DIF_cpu10HzMin m66 : 8|8@1+ (0.4,0) [0|102] "%"  Receiver
 SG_ DIF_cpu10msMin m66 : 40|8@1+ (0.4,0) [0|102] "%"  Receiver
 SG_ DIF_cpu1HzAvg m128 : 24|8@1+ (0.4,0) [0|102] "%"  Receiver
 SG_ DIF_cpu1HzMin m128 : 16|8@1+ (0.4,0) [0|102] "%"  Receiver
 SG_ DIF_cpu1kHzAvg m67 : 16|8@1+ (0.4,0) [0|102] "%"  Receiver
 SG_ DIF_cpu1kHzMin m67 : 8|8@1+ (0.4,0) [0|102] "%"  Receiver
 SG_ DIF_cpu20kHzAvg m67 : 32|8@1+ (0.4,0) [0|102] "%"  Receiver
 SG_ DIF_cpu20kHzMin m67 : 24|8@1+ (0.4,0) [0|102] "%"  Receiver
 SG_ DIF_cpuIDWord0 m131 : 16|16@1+ (1,0) [0|65535] ""  Receiver
 SG_ DIF_cpuIDWord1 m132 : 16|16@1+ (1,0) [0|65535] ""  Receiver
 SG_ DIF_cpuIDWord2 m132 : 32|16@1+ (1,0) [0|65535] ""  Receiver
 SG_ DIF_cpuIDWord3 m132 : 48|16@1+ (1,0) [0|65535] ""  Receiver
 SG_ DIF_crc m131 : 32|32@1+ (1,0) [0|4294970000] ""  Receiver
 SG_ DIF_currentLimit m41 : 32|16@1+ (0.1,0) [0|6553.5] "A"  Receiver
 SG_ DIF_dcCableCurrentEst m37 : 16|16@1- (0.1,0) [-3276.8|3276.7] "A"  Receiver
 SG_ DIF_dcCableHeat m47 : 32|16@1+ (0.001,0) [0|65.535] "kA2s"  Receiver
 SG_ DIF_dcCapTemp m64 : 8|8@1+ (1,-40) [-40|215] "C"  Receiver
 SG_ DIF_dcLinkCapTemp m70 : 32|8@1+ (1,-40) [-40|215] "C"  Receiver
 SG_ DIF_decodeHardwareStack m68 : 24|8@1+ (0.4,0) [0|100] "%"  Receiver
 SG_ DIF_driveUnitOdometer m69 : 32|32@1+ (10,0) [0|42949700000] "rev"  Receiver
 SG_ DIF_eepromStack m68 : 32|8@1+ (0.4,0) [0|100] "%"  Receiver
 SG_ DIF_fluxState m42 : 16|4@1+ (1,0) [0|10] ""  Receiver
 SG_ DIF_gainScale m37 : 8|8@1+ (0.01,0) [0|2.55] "scale"  Receiver
 SG_ DIF_gateDriveState m50 : 10|3@1+ (1,0) [0|4] ""  Receiver
 SG_ DIF_gateDriveSupplyState m50 : 8|2@1+ (1,0) [0|3] ""  Receiver
 SG_ DIF_hvDcCableTemp m70 : 40|8@1+ (1,-40) [-40|215] "C"  Receiver
 SG_ DIF_hwFaultCount m69 : 8|4@1+ (1,0) [0|15] ""  Receiver
 SG_ DIF_idleStack m68 : 16|8@1+ (0.4,0) [0|100] "%"  Receiver
 SG_ DIF_immobilizerStack m68 : 56|8@1+ (0.4,0) [0|100] "%"  Receiver
 SG_ DIF_internalAngleFilt m37 : 48|16@1+ (0.0003,0) [0|8] "rad"  Receiver
 SG_ DIF_llrScale m42 : 32|8@1+ (0.015,0) [0|3.825] "scale"  Receiver
 SG_ DIF_llsScale m42 : 24|8@1+ (0.004,0) [0|1.02] "scale"  Receiver
 SG_ DIF_lmScale m36 : 8|8@1+ (0.004,0) [0|1.02] "scale"  Receiver
 SG_ DIF_loadAngle m42 : 40|16@1- (0.0003,0) [-4|4] "rad"  Receiver
 SG_ DIF_loadAngleMargin m37 : 32|16@1- (0.0003,0) [-4|4] "rad"  Receiver
 SG_ DIF_magnetTempEst m47 : 48|8@1+ (1,-40) [-40|180] "C"  Receiver
 SG_ DIF_module10HzStack m66 : 48|8@1+ (0.4,0) [0|100] "%"  Receiver
 SG_ DIF_motorIA m32 : 16|16@1+ (0.1,0) [0|6553.5] "A"  Receiver
 SG_ DIF_motorIAavg m38 : 32|16@1- (0.1,0) [-3276.8|3276.7] "A"  Receiver
 SG_ DIF_motorIB m32 : 32|16@1+ (0.1,0) [0|6553.5] "A"  Receiver
 SG_ DIF_motorIBavg m38 : 48|16@1- (0.1,0) [-3276.8|3276.7] "A"  Receiver
 SG_ DIF_motorIC m32 : 48|16@1+ (0.1,0) [0|6553.5] "A"  Receiver
 SG_ DIF_motorType m128 : 8|6@1+ (1,0) [0|32] ""  Receiver
 SG_ DIF_motorV m34 : 48|16@1+ (2E-005,0) [0|1.3107] "mindex"  Receiver
 SG_ DIF_negDcBusbarTemp m70 : 48|8@1+ (1,-40) [-40|215] "C"  Receiver
 SG_ DIF_offsetA m32 : 8|8@1- (0.1,0) [-12.8|12.7] "A"  Receiver
 SG_ DIF_offsetB m33 : 8|8@1- (0.1,0) [-12.8|12.7] "A"  Receiver
 SG_ DIF_oilPumpMotorSpeed m46 : 8|8@1+ (40,0) [0|10200] "RPM"  Receiver
 SG_ DIF_oilPumpPhaseVoltage m46 : 16|8@1+ (0.1,0) [0|25.4] "V"  Receiver
 SG_ DIF_oilPumpPressureEstimateMax m46 : 24|8@1+ (2,0) [0|500] "kPa"  Receiver
 SG_ DIF_oilPumpPressureExpectedMin m46 : 32|8@1+ (2,0) [0|500] "kPa"  Receiver
 SG_ DIF_pcsTemp m64 : 24|8@1+ (1,-40) [-40|215] "C"  Receiver
 SG_ DIF_peakFlux m36 : 48|16@1+ (0.0001,0) [0|6.5535] "Wb"  Receiver
 SG_ DIF_peakIQref m38 : 16|16@1+ (0.1,0) [0|6553.5] "A"  Receiver
 SG_ DIF_phaseOutBusbarTemp m70 : 8|8@1+ (1,-40) [-40|215] "C"  Receiver
 SG_ DIF_phaseOutBusbarWeldTemp m70 : 16|8@1+ (1,-40) [-40|215] "C"  Receiver
 SG_ DIF_phaseOutLugTemp m70 : 24|8@1+ (1,-40) [-40|215] "C"  Receiver
 SG_ DIF_posDcBusbarTemp m70 : 56|8@1+ (1,-40) [-40|215] "C"  Receiver
 SG_ DIF_powerStageSafeState m50 : 13|2@1+ (1,0) [0|3] ""  Receiver
 SG_ DIF_pwmState m63 : 48|2@1+ (1,0) [0|3] ""  Receiver
 SG_ DIF_pwrSatChargeCurrent m42 : 8|8@1+ (0.4,0) [0|102] "%"  Receiver
 SG_ DIF_pwrSatDischargeCurrent m40 : 8|8@1+ (0.4,0) [0|102] "%"  Receiver
 SG_ DIF_pwrSatMaxBusVoltage m39 : 48|8@1+ (0.4,0) [0|102] "%"  Receiver
 SG_ DIF_pwrSatMaxDischargePower m39 : 16|8@1+ (0.4,0) [0|102] "%"  Receiver
 SG_ DIF_pwrSatMaxRegenPower m39 : 24|8@1+ (0.4,0) [0|102] "%"  Receiver
 SG_ DIF_pwrSatMinBusVoltage m39 : 56|8@1+ (0.4,0) [0|102] "%"  Receiver
 SG_ DIF_resolverClaMIA m48 : 43|1@1+ (1,0) [0|1] ""  Receiver
 SG_ DIF_resolverCommonGain m48 : 32|8@1+ (0.025,0) [0|5] "1"  Receiver
 SG_ DIF_resolverCosFiltered m52 : 32|8@1- (0.01,0) [-1|1] "1"  Receiver
 SG_ DIF_resolverCosRmsSquared m52 : 16|8@1+ (0.005,0) [0|1] "1"  Receiver
 SG_ DIF_resolverErrorRmsSquared m52 : 48|8@1+ (0.005,0) [0|1] "1"  Receiver
 SG_ DIF_resolverNoCarrier m48 : 41|1@1+ (1,0) [0|1] ""  Receiver
 SG_ DIF_resolverNoPhaseLock m48 : 42|1@1+ (1,0) [0|1] ""  Receiver
 SG_ DIF_resolverOffsetCos m48 : 8|8@1+ (0.015,0) [0|3.3] "V"  Receiver
 SG_ DIF_resolverOffsetSin m48 : 16|8@1+ (0.015,0) [0|3.3] "V"  Receiver
 SG_ DIF_resolverPhaseOffset m48 : 24|8@1+ (0.1,7.5) [7.5|32.5] "us"  Receiver
 SG_ DIF_resolverReady m48 : 40|1@1+ (1,0) [0|1] ""  Receiver
 SG_ DIF_resolverSinFiltered m52 : 40|8@1- (0.01,0) [-1|1] "1"  Receiver
 SG_ DIF_resolverSinRmsSquared m52 : 24|8@1+ (0.005,0) [0|1] "1"  Receiver
 SG_ DIF_rotorFlux m47 : 16|16@1+ (0.0001,0) [0|6.5535] "Wb"  Receiver
 SG_ DIF_rotorMaxMagnetTemp m72 : 16|8@1+ (1,-40) [-40|215] "C"  Receiver
 SG_ DIF_rotorOffsetEst m43 : 8|12@1- (0.01,0) [-20|20] "deg"  Receiver
 SG_ DIF_rotorOffsetLearningState m63 : 8|4@1+ (1,0) [0|9] ""  Receiver
 SG_ DIF_rotorOffsetMean m43 : 20|12@1- (0.01,0) [-20|20] "deg"  Receiver
 SG_ DIF_rsScale m34 : 8|8@1+ (0.01,0) [0|2.55] "scale"  Receiver
 SG_ DIF_soptMaxCurrentMagSqrd m49 : 40|16@1+ (100,0) [0|6553500] "A2"  Receiver
 SG_ DIF_soptTimeToOff m49 : 24|11@1+ (0.05,0) [0|100] "ms"  Receiver
 SG_ DIF_soptTimeToTrip m49 : 8|8@1+ (0.05,0) [0|10] "ms"  Receiver
 SG_ DIF_soptTripDelay m49 : 16|8@1+ (0.05,0) [0|10] "ms"  Receiver
 SG_ DIF_ssmState m38 : 8|4@1+ (1,0) [0|8] ""  Receiver
 SG_ DIF_statorEndWindingTemp m72 : 8|8@1+ (1,-40) [-40|215] "C"  Receiver
 SG_ DIF_statorFluxFdb m35 : 32|16@1+ (0.0001,0) [0|6.5535] "Wb"  Receiver
 SG_ DIF_statorFluxRef m35 : 16|16@1+ (0.0001,0) [0|6.5535] "Wb"  Receiver
 SG_ DIF_statorIDfdb m33 : 32|16@1- (0.1,0) [-3276.8|3276.7] "A"  Receiver
 SG_ DIF_statorIDref m33 : 16|16@1- (0.1,0) [-3276.8|3276.7] "A"  Receiver
 SG_ DIF_statorIQfdb m34 : 32|16@1- (0.1,0) [-3276.8|3276.7] "A"  Receiver
 SG_ DIF_statorIQref m34 : 16|16@1- (0.1,0) [-3276.8|3276.7] "A"  Receiver
 SG_ DIF_statorTemp1 m64 : 32|8@1+ (1,-40) [-40|215] "C"  Receiver
 SG_ DIF_statorTemp2 m64 : 40|8@1+ (1,-40) [-40|215] "C"  Receiver
 SG_ DIF_statorVD m36 : 32|16@1- (4E-005,0) [-1.31072|1.31068] "mindex"  Receiver
 SG_ DIF_statorVDFiltered m63 : 16|16@1- (4E-005,0) [-1.31072|1.31068] "mindex"  Receiver
 SG_ DIF_statorVQ m36 : 16|16@1- (4E-005,0) [-1.31072|1.31068] "mindex"  Receiver
 SG_ DIF_statorVQFiltered m63 : 32|16@1- (4E-005,0) [-1.31072|1.31068] "mindex"  Receiver
 SG_ DIF_sysHeatPowerOptimal m50 : 16|8@1+ (0.08,0) [0|20] "kW"  Receiver
 SG_ DIF_systemStack m68 : 8|8@1+ (0.4,0) [0|100] "%"  Receiver
 SG_ DIF_systemTorqueCommand m35 : 48|16@1- (0.035,0) [-1146.88|1146.85] "Nm"  Receiver
 SG_ DIF_tcMaxRequest m40 : 16|8@1+ (5,0) [0|1275] "Nm"  Receiver
 SG_ DIF_tcMinRequest m40 : 24|8@1+ (5,0) [0|1275] "Nm"  Receiver
 SG_ DIF_torquePerAmp m33 : 48|16@1+ (0.0001,0) [0|6.5535] "Nm/A"  Receiver
 SG_ DIF_tqSatMotorCurrent m39 : 40|8@1+ (0.4,0) [0|102] "%"  Receiver
 SG_ DIF_tqSatMotorVoltage m39 : 32|8@1+ (0.4,0) [0|102] "%"  Receiver
 SG_ DIF_tqSatThermal m39 : 8|8@1+ (0.4,0) [0|102] "%"  Receiver
 SG_ DIF_tqSatUiDriveTorque m40 : 32|8@1+ (0.4,0) [0|102] "%"  Receiver
 SG_ DIF_tqSatUiRegenTorque m40 : 40|8@1+ (0.4,0) [0|102] "%"  Receiver
 SG_ DIF_tqScaleDifferential m35 : 8|8@1+ (0.4,0) [0|102] "%"  Receiver
 SG_ DIF_tqScaleMaxMotorSpeed m40 : 48|8@1+ (0.4,0) [0|102] "%"  Receiver
 SG_ DIF_tqScaleShift m40 : 56|8@1+ (0.4,0) [0|102] "%"  Receiver
 SG_ DIF_udsStack m68 : 40|8@1+ (0.4,0) [0|100] "%"  Receiver
 SG_ DIF_usmState m38 : 12|3@1+ (1,0) [0|7] ""  Receiver
 SG_ DIF_veMassInvRaw m41 : 8|12@1+ (1E-007,0.0001) [0.0001|0.0005] "1/kg"  Receiver
 SG_ DIF_veResForce m41 : 20|12@1- (0.0005,0) [-1.024|1.0235] "G"  Receiver
 SG_ DIF_wasteCurrentLimit m41 : 48|16@1+ (0.1,0) [0|6553.5] "A"  Receiver
 SG_ DIF_xcpStack m68 : 48|8@1+ (0.4,0) [0|100] "%"  Receiver

BO_ 1880 DI_dyno: 8 VEH
 SG_ DI_dynoSelector M : 0|8@1+ (1,0) [0|0] ""  X
 SG_ DI_Isx m0 : 16|16@1+ (1.5259E-005,0) [0|0] "A"  X
 SG_ DI_Isy m0 : 32|16@1+ (1.5259E-005,0) [0|0] "A"  X
 SG_ DI_IsMag m0 : 48|16@1- (0.1,0) [0|0] "A"  X
 SG_ DI_Vsx m1 : 16|16@1- (4E-005,0) [0|0] "mindex"  X
 SG_ DI_Vsy m1 : 32|16@1- (4E-005,0) [0|0] "mindex"  X
 SG_ DI_voltageForFlux m1 : 48|16@1+ (0.00762951,0) [0|0] "V"  X
 SG_ DI_torqueMotor m2 : 16|13@1- (0.25,0) [0|0] "Nm"  X
 SG_ DI_state m2 : 29|3@1+ (1,0) [0|0] ""  X
 SG_ DI_motorRPM m2 : 32|16@1- (1,0) [0|0] "RPM"  X
 SG_ DI_torqueEstimate m2 : 48|13@1- (0.25,0) [0|0] "Nm"  X
 SG_ DI_pedalMinTorque m32 : 8|12@1+ (0.25,-750) [0|0] "Nm"  X
 SG_ DI_pedalMaxTorque m32 : 20|12@1+ (0.25,0) [0|0] "Nm"  X
 SG_ DI_postPedalMinTorque m32 : 32|12@1+ (0.25,-750) [0|0] "Nm"  X
 SG_ DI_postPedalMaxTorque m32 : 44|12@1+ (0.25,0) [0|0] "Nm"  X
 SG_ DI_slipEstimate m33 : 8|10@1- (0.02,0) [0|0] "Hz"  X
 SG_ DI_mechToElcFactor m64 : 8|4@1- (1,0) [0|0] ""  X

BO_ 1022 DI_estimatedBrakeTemp: 5 VEH
 SG_ DI_brakeFLTemp : 0|10@1+ (1,-40) [0|0] "DegC"  X
 SG_ DI_brakeFRTemp : 10|10@1+ (1,-40) [0|0] "DegC"  X
 SG_ DI_brakeRLTemp : 20|10@1+ (1,-40) [0|0] "DegC"  X
 SG_ DI_brakeRRTemp : 30|10@1+ (1,-40) [0|0] "DegC"  X

BO_ 1622 DI_info: 8 VEH
 SG_ DI_infoIndex M : 0|8@1+ (1,0) [0|0] ""  X
 SG_ DI_buildType m10 : 8|3@1+ (1,0) [0|0] ""  X
 SG_ DI_buildConfigurationId m10 : 16|16@1+ (1,0) [0|0] ""  X
 SG_ DI_hardwareId m10 : 32|8@1+ (1,0) [0|0] ""  X
 SG_ DI_componentId m10 : 48|16@1+ (1,0) [0|0] ""  X
 SG_ DI_pcbaId m11 : 16|8@1+ (1,0) [0|0] ""  X
 SG_ DI_assemblyId m11 : 24|8@1+ (1,0) [0|0] ""  X
 SG_ DI_usageId m11 : 32|16@1+ (1,0) [0|0] ""  X
 SG_ DI_subUsageId m11 : 48|16@1+ (1,0) [0|0] ""  X
 SG_ DI_applicationSvnRevision m12 : 8|24@1+ (1,0) [0|0] ""  X
 SG_ DI_applicationSvnUrlHash m12 : 32|32@1+ (1,0) [0|0] ""  X
 SG_ DI_applicationCrc m13 : 32|32@1+ (1,0) [0|0] ""  X
 SG_ DI_bootloaderSvnRevision m14 : 8|24@1+ (1,0) [0|0] ""  X
 SG_ DI_bootloaderSvnUrlHash m14 : 32|32@1+ (1,0) [0|0] ""  X
 SG_ DI_oilPumpBuildType m16 : 8|3@1+ (1,0) [0|0] ""  X
 SG_ DI_oilPumpAppCrc m16 : 16|32@1+ (1,0) [0|0] ""  X
 SG_ DI_appGitHash m17 : 10|54@1+ (4,0) [0|0] ""  X
 SG_ DI_bootGitHash m18 : 10|54@1+ (4,0) [0|0] ""  X
 SG_ DI_platformTyp m19 : 8|8@1+ (1,0) [0|0] ""  X
 SG_ DI_infoBootLdUdsProtocolVersion m20 : 8|8@1+ (1,0) [0|0] ""  X
 SG_ DI_bootloaderCrc m20 : 32|32@1+ (1,0) [0|0] ""  X
 SG_ DI_subcomponentGitHash m31 : 10|54@1+ (4,0) [0|0] ""  X

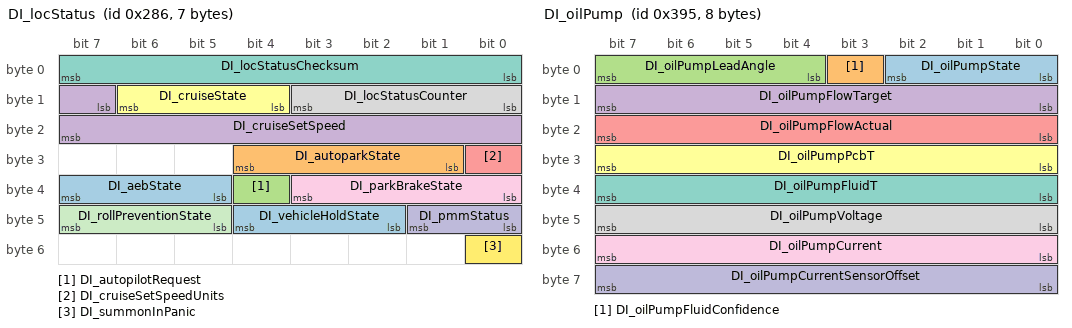
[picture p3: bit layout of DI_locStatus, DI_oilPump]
BO_ 646 DI_locStatus: 7 VEH
 SG_ DI_aebState : 37|3@1+ (1,0) [0|0] ""  X
 SG_ DI_autoparkState : 25|4@1+ (1,0) [0|0] ""  X
 SG_ DI_autopilotRequest : 36|1@1+ (1,0) [0|0] ""  X
 SG_ DI_cruiseSetSpeed : 15|9@1+ (0.5,0) [0|0] "speed"  X
 SG_ DI_cruiseSetSpeedUnits : 24|1@1+ (1,0) [0|0] ""  X
 SG_ DI_cruiseState : 12|3@1+ (1,0) [0|0] ""  X
 SG_ DI_locStatusChecksum : 0|8@1+ (1,0) [0|0] ""  X
 SG_ DI_locStatusCounter : 8|4@1+ (1,0) [0|0] ""  X
 SG_ DI_parkBrakeState : 32|4@1+ (1,0) [0|0] ""  X
 SG_ DI_pmmStatus : 40|2@1+ (1,0) [0|0] ""  X
 SG_ DI_rollPreventionState : 45|3@1+ (1,0) [0|0] ""  X
 SG_ DI_summonInPanic : 48|1@1+ (1,0) [0|0] ""  X
 SG_ DI_vehicleHoldState : 42|3@1+ (1,0) [0|0] ""  X

BO_ 822 DI_maxRatedPower: 3 VEH
 SG_ DI_sysDrivePowerRated : 0|9@1+ (1,0) [0|0] "kW"  X
 SG_ DI_sysRegenPowerRated : 16|8@1+ (1,-100) [0|0] "kW"  X

BO_ 950 DI_odometerStatus: 4 VEH
 SG_ DI_odometer : 0|32@1+ (0.001,0) [0|0] "km"  X

BO_ 917 DI_oilPump: 8 VEH
 SG_ DI_oilPumpState : 0|3@1+ (1,0) [0|0] ""  X
 SG_ DI_oilPumpFluidConfidence : 3|1@1+ (1,0) [0|0] ""  X
 SG_ DI_oilPumpLeadAngle : 4|4@1+ (1.875,0) [0|28.125] "deg"  X
 SG_ DI_oilPumpFlowTarget : 8|8@1+ (0.06,0) [0|0] "LPM"  X
 SG_ DI_oilPumpFlowActual : 16|8@1+ (0.06,0) [0|0] "LPM"  X
 SG_ DI_oilPumpPcbT : 24|8@1+ (1,-40) [0|0] "DegC"  X
 SG_ DI_oilPumpFluidT : 32|8@1+ (1,-40) [0|0] "DegC"  X
 SG_ DI_oilPumpVoltage : 40|8@1+ (0.1,0) [0|0] "V"  X
 SG_ DI_oilPumpCurrent : 48|8@1+ (0.1,0) [0|0] "A"  X
 SG_ DI_oilPumpCurrentSensorOffset : 56|8@1+ (0.005,0) [0|0] "A"  X

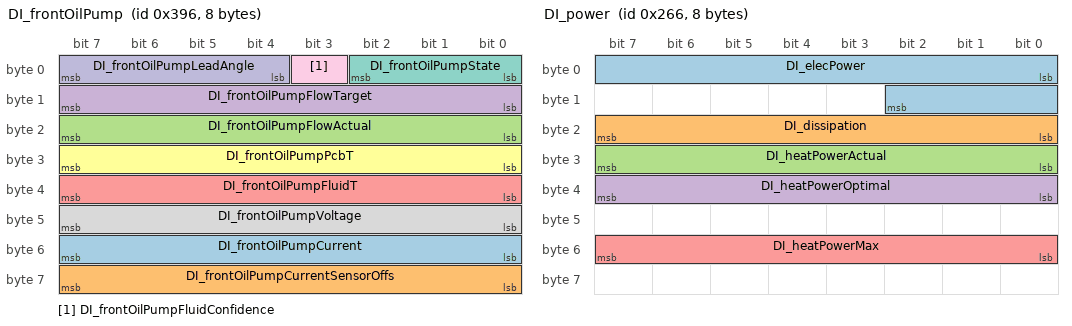
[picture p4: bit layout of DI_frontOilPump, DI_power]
BO_ 918 DI_frontOilPump: 8 VEH
 SG_ DI_frontOilPumpCurrent : 48|8@1+ (0.1,0) [0|0] "A"  X
 SG_ DI_frontOilPumpCurrentSensorOffs : 56|8@1+ (0.005,0) [0|0] "A"  X
 SG_ DI_frontOilPumpFlowActual : 16|8@1+ (0.06,0) [0|0] "LPM"  X
 SG_ DI_frontOilPumpFlowTarget : 8|8@1+ (0.06,0) [0|0] "LPM"  X
 SG_ DI_frontOilPumpFluidT : 32|8@1+ (1,-40) [0|0] "DegC"  X
 SG_ DI_frontOilPumpPcbT : 24|8@1+ (1,-40) [0|0] "DegC"  X
 SG_ DI_frontOilPumpState : 0|3@1+ (1,0) [0|0] ""  X
 SG_ DI_frontOilPumpVoltage : 40|8@1+ (0.1,0) [0|0] "V"  X
 SG_ DI_frontOilPumpFluidConfidence : 3|1@1+ (1,0) [0|0] ""  X
 SG_ DI_frontOilPumpLeadAngle : 4|4@1+ (1.875,0) [0|28.125] "deg"  X

BO_ 614 DI_power: 8 VEH
 SG_ DI_elecPower : 0|11@1- (0.5,0) [0|0] "kW"  X
 SG_ DI_dissipation : 16|8@1+ (125,0) [0|0] "W"  X
 SG_ DI_heatPowerActual : 24|8@1+ (0.08,0) [0|0] "kW"  X
 SG_ DI_heatPowerOptimal : 32|8@1+ (0.08,0) [0|0] "kW"  X
 SG_ DI_heatPowerMax : 48|8@1+ (0.08,0) [0|0] "kW"  X

BO_ 294 DI_hvBusStatus: 3 VEH
 SG_ DI_voltage : 0|10@1+ (0.5,0) [0|500] "V"  X
 SG_ DI_current : 10|11@1+ (1,0) [0|2047] "A"  X

BO_ 421 DI_frontHvBusStatus: 3 VEH
 SG_ DI_frontVoltage : 0|10@1+ (0.5,0) [0|500] "V"  X
 SG_ DI_frontCurrent : 10|11@1+ (1,0) [0|2047] "A"  X

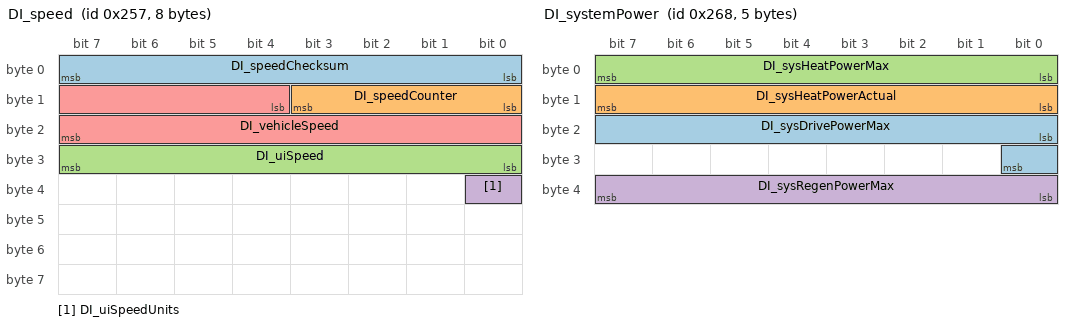
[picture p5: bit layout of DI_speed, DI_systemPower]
BO_ 599 DI_speed: 8 VEH
 SG_ DI_speedChecksum : 0|8@1+ (1,0) [0|0] ""  X
 SG_ DI_speedCounter : 8|4@1+ (1,0) [0|0] ""  X
 SG_ DI_uiSpeed : 24|8@1+ (1,0) [0|0] ""  X
 SG_ DI_uiSpeedUnits : 32|1@1+ (1,0) [0|0] ""  X
 SG_ DI_vehicleSpeed : 12|12@1+ (0.08,-40) [0|0] "kph"  X

BO_ 616 DI_systemPower: 5 VEH
 SG_ DI_sysDrivePowerMax : 16|9@1+ (1,0) [0|0] "kW"  X
 SG_ DI_sysHeatPowerActual : 8|8@1+ (0.08,0) [0|0] "kW"  X
 SG_ DI_sysHeatPowerMax : 0|8@1+ (0.08,0) [0|0] "kW"  X
 SG_ DI_sysRegenPowerMax : 32|8@1+ (1,-100) [0|0] "kW"  X

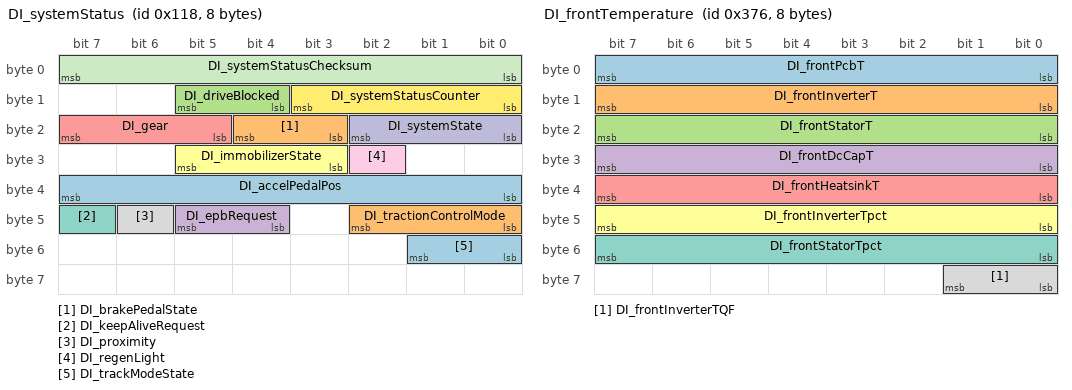
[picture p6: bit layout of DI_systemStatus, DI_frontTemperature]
BO_ 280 DI_systemStatus: 8 VEH
 SG_ DI_accelPedalPos : 32|8@1+ (0.4,0) [0|0] "%"  X
 SG_ DI_brakePedalState : 19|2@1+ (1,0) [0|0] ""  X
 SG_ DI_driveBlocked : 12|2@1+ (1,0) [0|2] ""  X
 SG_ DI_epbRequest : 44|2@1+ (1,0) [0|0] ""  X
 SG_ DI_gear : 21|3@1+ (1,0) [0|0] ""  X
 SG_ DI_immobilizerState : 27|3@1+ (1,0) [0|0] ""  X
 SG_ DI_keepAliveRequest : 47|1@1+ (1,0) [0|0] ""  X
 SG_ DI_proximity : 46|1@1+ (1,0) [0|0] ""  X
 SG_ DI_regenLight : 26|1@1+ (1,0) [0|0] ""  X
 SG_ DI_systemState : 16|3@1+ (1,0) [0|0] ""  X
 SG_ DI_systemStatusChecksum : 0|8@1+ (1,0) [0|0] ""  X
 SG_ DI_systemStatusCounter : 8|4@1+ (1,0) [0|0] ""  X
 SG_ DI_trackModeState : 48|2@1+ (1,0) [0|0] ""  X
 SG_ DI_tractionControlMode : 40|3@1+ (1,0) [0|0] ""  X

BO_ 789 DI_temperature: 8 VEH
 SG_ DI_temperatureIndex M : 0|1@1+ (1,0) [0|1] ""  X
 SG_ DI_inverterT m0 : 8|8@1+ (1,-40) [0|0] "DegC"  X
 SG_ DI_statorT m0 : 16|8@1+ (1,-40) [0|0] "DegC"  X
 SG_ DI_dcCapT m0 : 24|8@1+ (1,-40) [0|0] "DegC"  X
 SG_ DI_heatsinkT m0 : 32|8@1+ (1,-40) [0|0] "DegC"  X
 SG_ DI_inverterTpct m0 : 40|8@1+ (0.4,0) [0|0] "%"  X
 SG_ DI_statorTpct m0 : 48|8@1+ (0.4,0) [0|0] "%"  X
 SG_ DI_inverterTQF m0 : 56|2@1+ (1,0) [0|3] ""  X

BO_ 886 DI_frontTemperature: 8 VEH
 SG_ DI_frontPcbT : 0|8@1+ (1,-40) [0|0] "DegC"  X
 SG_ DI_frontInverterT : 8|8@1+ (1,-40) [0|0] "DegC"  X
 SG_ DI_frontStatorT : 16|8@1+ (1,-40) [0|0] "DegC"  X
 SG_ DI_frontDcCapT : 24|8@1+ (1,-40) [0|0] "DegC"  X
 SG_ DI_frontHeatsinkT : 32|8@1+ (1,-40) [0|0] "DegC"  X
 SG_ DI_frontInverterTpct : 40|8@1+ (0.4,0) [0|0] "%"  X
 SG_ DI_frontStatorTpct : 48|8@1+ (0.4,0) [0|0] "%"  X
 SG_ DI_frontInverterTQF : 56|2@1+ (1,0) [0|0] ""  X

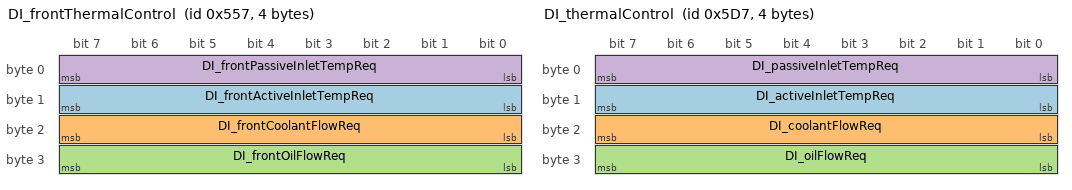
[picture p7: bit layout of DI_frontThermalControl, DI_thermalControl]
BO_ 1367 DI_frontThermalControl: 4 VEH
 SG_ DI_frontActiveInletTempReq : 8|8@1+ (1,-40) [-40|120] "C"  X
 SG_ DI_frontCoolantFlowReq : 16|8@1+ (0.2,0) [0|50] "LPM"  X
 SG_ DI_frontOilFlowReq : 24|8@1+ (0.06,0) [0|15] "LPM"  X
 SG_ DI_frontPassiveInletTempReq : 0|8@1+ (1,-40) [-40|120] "C"  X

BO_ 1495 DI_thermalControl: 4 VEH
 SG_ DI_activeInletTempReq : 8|8@1+ (1,-40) [0|0] "DegC"  X
 SG_ DI_coolantFlowReq : 16|8@1+ (0.2,0) [0|0] "LPM"  X
 SG_ DI_oilFlowReq : 24|8@1+ (0.06,0) [0|15] "LPM"  X
 SG_ DI_passiveInletTempReq : 0|8@1+ (1,-40) [0|0] "DegC"  X

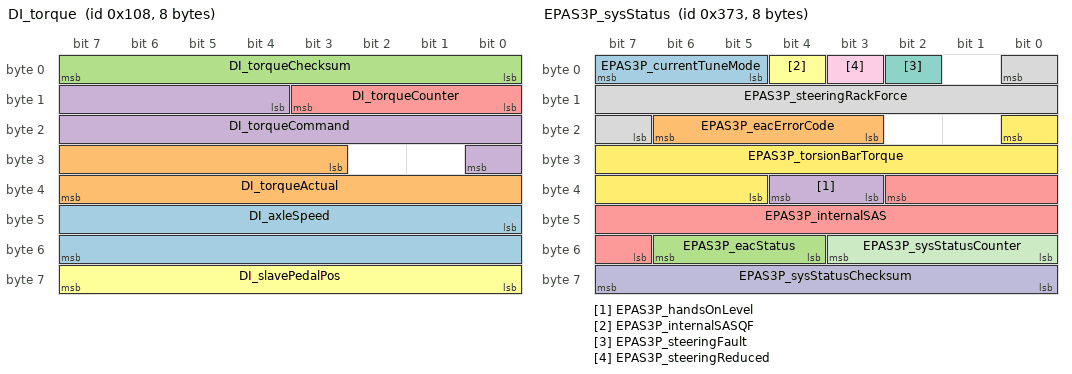
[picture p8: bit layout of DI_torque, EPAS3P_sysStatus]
BO_ 264 DI_torque: 8 VEH
 SG_ DI_axleSpeed : 40|16@1- (0.1,0) [0|0] "RPM"  X
 SG_ DI_torqueActual : 27|13@1- (2,0) [0|0] "Nm"  X
 SG_ DI_torqueChecksum : 0|8@1+ (1,0) [0|0] ""  X
 SG_ DI_torqueCommand : 12|13@1- (2,0) [0|0] "Nm"  X
 SG_ DI_torqueCounter : 8|4@1+ (1,0) [0|0] ""  X
 SG_ DI_slavePedalPos : 56|8@1+ (0.4,0) [0|100] "%"  X

BO_ 914 EPAS3P_alertMatrix: 8 VEH
 SG_ EPAS3P_matrixIndex M : 0|4@1+ (1,0) [0|0] ""  X
 SG_ EPAS3P_a001_sent1Mia m0 : 4|1@1+ (1,0) [0|0] ""  X
 SG_ EPAS3P_a002_sent1Error m0 : 5|1@1+ (1,0) [0|0] ""  X
 SG_ EPAS3P_a003_trqSens1Supply m0 : 6|1@1+ (1,0) [0|0] ""  X
 SG_ EPAS3P_a004_trqSens1Eeprom m0 : 7|1@1+ (1,0) [0|0] ""  X
 SG_ EPAS3P_a005_sent2Mia m0 : 8|1@1+ (1,0) [0|0] ""  X
 SG_ EPAS3P_a006_sent2Error m0 : 9|1@1+ (1,0) [0|0] ""  X
 SG_ EPAS3P_a007_trqSens2Supply m0 : 10|1@1+ (1,0) [0|0] ""  X
 SG_ EPAS3P_a008_trqSens2Eeprom m0 : 11|1@1+ (1,0) [0|0] ""  X
 SG_ EPAS3P_a009_sentDiff m0 : 12|1@1+ (1,0) [0|0] ""  X
 SG_ EPAS3P_a010_trqSensCalError m0 : 13|1@1+ (1,0) [0|0] ""  X
 SG_ EPAS3P_a011_currentSensError m0 : 14|1@1+ (1,0) [0|0] ""  X
 SG_ EPAS3P_a012_currentSensCalError m0 : 15|1@1+ (1,0) [0|0] ""  X
 SG_ EPAS3P_a013_gateDriveError m0 : 16|1@1+ (1,0) [0|0] ""  X
 SG_ EPAS3P_a014_gateDriveTxError m0 : 17|1@1+ (1,0) [0|0] ""  X
 SG_ EPAS3P_a015_gateDriveEeprom m0 : 18|1@1+ (1,0) [0|0] ""  X
 SG_ EPAS3P_a016_phaseUhighUv m0 : 19|1@1+ (1,0) [0|0] ""  X
 SG_ EPAS3P_a017_phaseUlowUv m0 : 20|1@1+ (1,0) [0|0] ""  X
 SG_ EPAS3P_a018_phaseVhighUv m0 : 21|1@1+ (1,0) [0|0] ""  X
 SG_ EPAS3P_a019_phaseVlowUv m0 : 22|1@1+ (1,0) [0|0] ""  X
 SG_ EPAS3P_a020_phaseWhighUv m0 : 23|1@1+ (1,0) [0|0] ""  X
 SG_ EPAS3P_a021_phaseWlowUv m0 : 24|1@1+ (1,0) [0|0] ""  X
 SG_ EPAS3P_a022_phaseUhighOv m0 : 25|1@1+ (1,0) [0|0] ""  X
 SG_ EPAS3P_a023_phaseUlowOv m0 : 26|1@1+ (1,0) [0|0] ""  X
 SG_ EPAS3P_a024_phaseVhighOv m0 : 27|1@1+ (1,0) [0|0] ""  X
 SG_ EPAS3P_a025_phaseVlowOv m0 : 28|1@1+ (1,0) [0|0] ""  X
 SG_ EPAS3P_a026_phaseWhighOv m0 : 29|1@1+ (1,0) [0|0] ""  X
 SG_ EPAS3P_a027_phaseWlowOv m0 : 30|1@1+ (1,0) [0|0] ""  X
 SG_ EPAS3P_a028_phaseUbootUv m0 : 31|1@1+ (1,0) [0|0] ""  X
 SG_ EPAS3P_a029_phaseVbootUv m0 : 32|1@1+ (1,0) [0|0] ""  X
 SG_ EPAS3P_a030_phaseWbootUv m0 : 33|1@1+ (1,0) [0|0] ""  X
 SG_ EPAS3P_a031_phaseFeedbackError m0 : 34|1@1+ (1,0) [0|0] ""  X
 SG_ EPAS3P_a032_vRegOutputUv m0 : 35|1@1+ (1,0) [0|0] ""  X
 SG_ EPAS3P_a033_vRegOutputOv m0 : 36|1@1+ (1,0) [0|0] ""  X
 SG_ EPAS3P_a034_vRegError m0 : 37|1@1+ (1,0) [0|0] ""  X
 SG_ EPAS3P_a035_vbbSupplyUv m0 : 38|1@1+ (1,0) [0|0] ""  X
 SG_ EPAS3P_a036_vbbSupplyOv m0 : 39|1@1+ (1,0) [0|0] ""  X
 SG_ EPAS3P_a037_motPos1ParityError m0 : 40|1@1+ (1,0) [0|0] ""  X
 SG_ EPAS3P_a038_motPos1Uv m0 : 41|1@1+ (1,0) [0|0] ""  X
 SG_ EPAS3P_a039_motPos1MagnetMia m0 : 42|1@1+ (1,0) [0|0] ""  X
 SG_ EPAS3P_a040_motPos1LogicError m0 : 43|1@1+ (1,0) [0|0] ""  X
 SG_ EPAS3P_a041_motPos1tempError m0 : 44|1@1+ (1,0) [0|0] ""  X
 SG_ EPAS3P_a042_motPos2ParityError m0 : 45|1@1+ (1,0) [0|0] ""  X
 SG_ EPAS3P_a043_motPos2Uv m0 : 46|1@1+ (1,0) [0|0] ""  X
 SG_ EPAS3P_a044_motPos2MagnetMia m0 : 47|1@1+ (1,0) [0|0] ""  X
 SG_ EPAS3P_a045_motPos2LogicError m0 : 48|1@1+ (1,0) [0|0] ""  X
 SG_ EPAS3P_a046_motPos2tempError m0 : 49|1@1+ (1,0) [0|0] ""  X
 SG_ EPAS3P_a047_motPosCorrError m0 : 50|1@1+ (1,0) [0|0] ""  X
 SG_ EPAS3P_a048_motPosCalError m0 : 51|1@1+ (1,0) [0|0] ""  X
 SG_ EPAS3P_a049_piCtrlError m0 : 52|1@1+ (1,0) [0|0] ""  X
 SG_ EPAS3P_a050_mcuSmuError m0 : 53|1@1+ (1,0) [0|0] ""  X
 SG_ EPAS3P_a051_mcuSupError m0 : 54|1@1+ (1,0) [0|0] ""  X
 SG_ EPAS3P_a052_intWatchdogError m0 : 55|1@1+ (1,0) [0|0] ""  X
 SG_ EPAS3P_a053_extWatchdogError m0 : 56|1@1+ (1,0) [0|0] ""  X
 SG_ EPAS3P_a054_memoryProtectError m0 : 57|1@1+ (1,0) [0|0] ""  X
 SG_ EPAS3P_a055_floatPointError m0 : 58|1@1+ (1,0) [0|0] ""  X
 SG_ EPAS3P_a056_battUv m0 : 59|1@1+ (1,0) [0|0] ""  X
 SG_ EPAS3P_a057_battUvReduced m0 : 60|1@1+ (1,0) [0|0] ""  X
 SG_ EPAS3P_a058_battOv m0 : 61|1@1+ (1,0) [0|0] ""  X
 SG_ EPAS3P_a059_battOvReduced m0 : 62|1@1+ (1,0) [0|0] ""  X
 SG_ EPAS3P_a060_battBridgeDiff m0 : 63|1@1+ (1,0) [0|0] ""  X
 SG_ EPAS3P_a061_bridgeUv m1 : 4|1@1+ (1,0) [0|0] ""  X
 SG_ EPAS3P_a062_assistCorrError m1 : 5|1@1+ (1,0) [0|0] ""  X
 SG_ EPAS3P_a063_dampCorrError m1 : 6|1@1+ (1,0) [0|0] ""  X
 SG_ EPAS3P_a064_phaseCompCorrError m1 : 7|1@1+ (1,0) [0|0] ""  X
 SG_ EPAS3P_a065_trqTarCorrError m1 : 8|1@1+ (1,0) [0|0] ""  X
 SG_ EPAS3P_a066_returnCorrError m1 : 9|1@1+ (1,0) [0|0] ""  X
 SG_ EPAS3P_a067_yawDampCorrError m1 : 10|1@1+ (1,0) [0|0] ""  X
 SG_ EPAS3P_a068_hystCorrError m1 : 11|1@1+ (1,0) [0|0] ""  X
 SG_ EPAS3P_a069_eacCorrError m1 : 12|1@1+ (1,0) [0|0] ""  X
 SG_ EPAS3P_a070_hodCorrError m1 : 13|1@1+ (1,0) [0|0] ""  X
 SG_ EPAS3P_a071_vehSpdCorrError m1 : 14|1@1+ (1,0) [0|0] ""  X
 SG_ EPAS3P_a072_motFeedFwdError m1 : 15|1@1+ (1,0) [0|0] ""  X
 SG_ EPAS3P_a073_motParEstError m1 : 16|1@1+ (1,0) [0|0] ""  X
 SG_ EPAS3P_a074_overHeatProtect m1 : 17|1@1+ (1,0) [0|0] ""  X
 SG_ EPAS3P_a075_fspPwrCut m1 : 18|1@1+ (1,0) [0|0] ""  X
 SG_ EPAS3P_a076_tempSensOutofRange m1 : 19|1@1+ (1,0) [0|0] ""  X
 SG_ EPAS3P_a077_highSideFetError m1 : 20|1@1+ (1,0) [0|0] ""  X
 SG_ EPAS3P_a078_phaseDisconnectError m1 : 21|1@1+ (1,0) [0|0] ""  X
 SG_ EPAS3P_a079_backupCurrentPlaus m1 : 22|1@1+ (1,0) [0|0] ""  X
 SG_ EPAS3P_a080_ecuInitArbError m1 : 23|1@1+ (1,0) [0|0] ""  X
 SG_ EPAS3P_a081_coggCompError m1 : 24|1@1+ (1,0) [0|0] ""  X
 SG_ EPAS3P_a082_polarityCalError m1 : 25|1@1+ (1,0) [0|0] ""  X
 SG_ EPAS3P_a083_crcMismatch m1 : 26|1@1+ (1,0) [0|0] ""  X
 SG_ EPAS3P_a084_eacCancelled m1 : 27|1@1+ (1,0) [0|0] ""  X
 SG_ EPAS3P_a085_canBusOff m1 : 28|1@1+ (1,0) [0|0] ""  X
 SG_ EPAS3P_a086_dasMia m1 : 29|1@1+ (1,0) [0|0] ""  X
 SG_ EPAS3P_a087_dasCntError m1 : 30|1@1+ (1,0) [0|0] ""  X
 SG_ EPAS3P_a088_dasCsError m1 : 31|1@1+ (1,0) [0|0] ""  X
 SG_ EPAS3P_a089_espWsMia m1 : 32|1@1+ (1,0) [0|0] ""  X
 SG_ EPAS3P_a090_espWsCntError m1 : 33|1@1+ (1,0) [0|0] ""  X
 SG_ EPAS3P_a091_espWsCsError m1 : 34|1@1+ (1,0) [0|0] ""  X
 SG_ EPAS3P_a092_espWrMia m1 : 35|1@1+ (1,0) [0|0] ""  X
 SG_ EPAS3P_a093_espWrCntError m1 : 36|1@1+ (1,0) [0|0] ""  X
 SG_ EPAS3P_a094_espWrCsError m1 : 37|1@1+ (1,0) [0|0] ""  X
 SG_ EPAS3P_a095_espWsStatus m1 : 38|1@1+ (1,0) [0|0] ""  X
 SG_ EPAS3P_a096_rcmMia m1 : 39|1@1+ (1,0) [0|0] ""  X
 SG_ EPAS3P_a097_rcmCntError m1 : 40|1@1+ (1,0) [0|0] ""  X
 SG_ EPAS3P_a098_rcmCsError m1 : 41|1@1+ (1,0) [0|0] ""  X
 SG_ EPAS3P_a099_yawRateStatus m1 : 42|1@1+ (1,0) [0|0] ""  X
 SG_ EPAS3P_a100_diMia m1 : 43|1@1+ (1,0) [0|0] ""  X
 SG_ EPAS3P_a101_diCntError m1 : 44|1@1+ (1,0) [0|0] ""  X
 SG_ EPAS3P_a102_diCsError m1 : 45|1@1+ (1,0) [0|0] ""  X
 SG_ EPAS3P_a103_vcFrontMia m1 : 46|1@1+ (1,0) [0|0] ""  X
 SG_ EPAS3P_a104_vcFrontCntError m1 : 47|1@1+ (1,0) [0|0] ""  X
 SG_ EPAS3P_a105_vcFrontCsError m1 : 48|1@1+ (1,0) [0|0] ""  X
 SG_ EPAS3P_a106_vcFrontTempMia m1 : 49|1@1+ (1,0) [0|0] ""  X
 SG_ EPAS3P_a107_uiTuneReqMia m1 : 50|1@1+ (1,0) [0|0] ""  X
 SG_ EPAS3P_a108_uiTuneReqCntError m1 : 51|1@1+ (1,0) [0|0] ""  X
 SG_ EPAS3P_a109_uiTuneReqCsError m1 : 52|1@1+ (1,0) [0|0] ""  X
 SG_ EPAS3P_a110_sasMia m1 : 53|1@1+ (1,0) [0|0] ""  X
 SG_ EPAS3P_a111_sasCntError m1 : 54|1@1+ (1,0) [0|0] ""  X
 SG_ EPAS3P_a112_sasCsError m1 : 55|1@1+ (1,0) [0|0] ""  X
 SG_ EPAS3P_a113_sasStatusError m1 : 56|1@1+ (1,0) [0|0] ""  X
 SG_ EPAS3P_a114_gtwConfigMia m1 : 57|1@1+ (1,0) [0|0] ""  X
 SG_ EPAS3P_a115_ecuStatMia m1 : 58|1@1+ (1,0) [0|0] ""  X
 SG_ EPAS3P_a116_ecuStatCntError m1 : 59|1@1+ (1,0) [0|0] ""  X
 SG_ EPAS3P_a117_ecuStatCrcError m1 : 60|1@1+ (1,0) [0|0] ""  X
 SG_ EPAS3P_a118_privateBusOff m1 : 61|1@1+ (1,0) [0|0] ""  X
 SG_ EPAS3P_a119_pvtEcuStatMia m1 : 62|1@1+ (1,0) [0|0] ""  X
 SG_ EPAS3P_a120_pvtEcuStatCntError m1 : 63|1@1+ (1,0) [0|0] ""  X
 SG_ EPAS3P_a121_pvtEcuStatCrcError m2 : 4|1@1+ (1,0) [0|0] ""  X
 SG_ EPAS3P_a122_olpActive m2 : 5|1@1+ (1,0) [0|0] ""  X
 SG_ EPAS3P_a123_combEcu2StatFail m2 : 6|1@1+ (1,0) [0|0] ""  X
 SG_ EPAS3P_a124_tempSensStuckInRange m2 : 7|1@1+ (1,0) [0|0] ""  X
 SG_ EPAS3P_a125_trqSensTrimOutRange m2 : 8|1@1+ (1,0) [0|0] ""  X
 SG_ EPAS3P_a126_apsMia m2 : 9|1@1+ (1,0) [0|0] ""  X
 SG_ EPAS3P_a127_apsCntError m2 : 10|1@1+ (1,0) [0|0] ""  X
 SG_ EPAS3P_a128_apsCsError m2 : 11|1@1+ (1,0) [0|0] ""  X
 SG_ EPAS3P_a129_combEcu1StatFail m2 : 12|1@1+ (1,0) [0|0] ""  X
 SG_ EPAS3P_a130_sasOffsetNotCal m2 : 13|1@1+ (1,0) [0|0] ""  X

BO_ 817 EPAS3P_info: 8 VEH
 SG_ EPAS3P_infoIndex M : 0|8@1+ (1,0) [0|0] ""  X
 SG_ EPAS3P_infoBuildType m10 : 8|8@1+ (1,0) [0|0] ""  X
 SG_ EPAS3P_infoComponentID m10 : 48|16@1+ (1,0) [0|0] ""  X
 SG_ EPAS3P_infoPcbaID m11 : 16|8@1+ (1,0) [0|0] ""  X
 SG_ EPAS3P_infoAssemblyID m11 : 24|8@1+ (1,0) [0|0] ""  X
 SG_ EPAS3P_infoUsageID m11 : 32|16@1+ (1,0) [0|0] ""  X
 SG_ EPAS3P_infoBootUdsProtoVersion m20 : 8|8@1+ (1,0) [0|0] ""  X
 SG_ EPAS3P_infoBootloaderCRC m20 : 32|32@1+ (1,0) [0|0] ""  X
 SG_ EPAS3P_infoApplicationCRC m13 : 32|32@1+ (1,0) [0|0] ""  X

BO_ 883 EPAS3P_sysStatus: 8 VEH
 SG_ EPAS3P_currentTuneMode : 5|3@1+ (1,0) [0|0] ""  X
 SG_ EPAS3P_eacErrorCode : 19|4@1+ (1,0) [0|0] ""  X
 SG_ EPAS3P_eacStatus : 52|3@1+ (1,0) [0|0] ""  X
 SG_ EPAS3P_handsOnLevel : 35|2@1+ (1,0) [0|0] ""  X
 SG_ EPAS3P_internalSAS : 34|12@0+ (1,-819.2) [0|0] "deg"  X
 SG_ EPAS3P_internalSASQF : 4|1@1+ (1,0) [0|0] ""  X
 SG_ EPAS3P_steeringFault : 2|1@1+ (1,0) [0|0] ""  X
 SG_ EPAS3P_steeringRackForce : 0|10@0+ (50,-25575) [0|0] "N"  X
 SG_ EPAS3P_steeringReduced : 3|1@1+ (1,0) [0|0] ""  X
 SG_ EPAS3P_sysStatusChecksum : 56|8@1+ (1,0) [0|0] ""  X
 SG_ EPAS3P_sysStatusCounter : 48|4@1+ (1,0) [0|0] ""  X
 SG_ EPAS3P_torsionBarTorque : 16|12@0+ (0.01,-20.5) [0|0] "Nm"  X

BO_ 913 EPAS3S_alertMatrix: 8 CH
 SG_ EPAS3S_matrixIndex M : 0|4@1+ (1,0) [0|0] ""  X
 SG_ EPAS3S_a001_sent1Mia m0 : 4|1@1+ (1,0) [0|0] ""  X
 SG_ EPAS3S_a002_sent1Error m0 : 5|1@1+ (1,0) [0|0] ""  X
 SG_ EPAS3S_a003_trqSens1Supply m0 : 6|1@1+ (1,0) [0|0] ""  X
 SG_ EPAS3S_a004_trqSens1Eeprom m0 : 7|1@1+ (1,0) [0|0] ""  X
 SG_ EPAS3S_a005_sent2Mia m0 : 8|1@1+ (1,0) [0|0] ""  X
 SG_ EPAS3S_a006_sent2Error m0 : 9|1@1+ (1,0) [0|0] ""  X
 SG_ EPAS3S_a007_trqSens2Supply m0 : 10|1@1+ (1,0) [0|0] ""  X
 SG_ EPAS3S_a008_trqSens2Eeprom m0 : 11|1@1+ (1,0) [0|0] ""  X
 SG_ EPAS3S_a009_sentDiff m0 : 12|1@1+ (1,0) [0|0] ""  X
 SG_ EPAS3S_a010_trqSensCalError m0 : 13|1@1+ (1,0) [0|0] ""  X
 SG_ EPAS3S_a011_currentSensError m0 : 14|1@1+ (1,0) [0|0] ""  X
 SG_ EPAS3S_a012_currentSensCalError m0 : 15|1@1+ (1,0) [0|0] ""  X
 SG_ EPAS3S_a013_gateDriveError m0 : 16|1@1+ (1,0) [0|0] ""  X
 SG_ EPAS3S_a014_gateDriveTxError m0 : 17|1@1+ (1,0) [0|0] ""  X
 SG_ EPAS3S_a015_gateDriveEeprom m0 : 18|1@1+ (1,0) [0|0] ""  X
 SG_ EPAS3S_a016_phaseUhighUv m0 : 19|1@1+ (1,0) [0|0] ""  X
 SG_ EPAS3S_a017_phaseUlowUv m0 : 20|1@1+ (1,0) [0|0] ""  X
 SG_ EPAS3S_a018_phaseVhighUv m0 : 21|1@1+ (1,0) [0|0] ""  X
 SG_ EPAS3S_a019_phaseVlowUv m0 : 22|1@1+ (1,0) [0|0] ""  X
 SG_ EPAS3S_a020_phaseWhighUv m0 : 23|1@1+ (1,0) [0|0] ""  X
 SG_ EPAS3S_a021_phaseWlowUv m0 : 24|1@1+ (1,0) [0|0] ""  X
 SG_ EPAS3S_a022_phaseUhighOv m0 : 25|1@1+ (1,0) [0|0] ""  X
 SG_ EPAS3S_a023_phaseUlowOv m0 : 26|1@1+ (1,0) [0|0] ""  X
 SG_ EPAS3S_a024_phaseVhighOv m0 : 27|1@1+ (1,0) [0|0] ""  X
 SG_ EPAS3S_a025_phaseVlowOv m0 : 28|1@1+ (1,0) [0|0] ""  X
 SG_ EPAS3S_a026_phaseWhighOv m0 : 29|1@1+ (1,0) [0|0] ""  X
 SG_ EPAS3S_a027_phaseWlowOv m0 : 30|1@1+ (1,0) [0|0] ""  X
 SG_ EPAS3S_a028_phaseUbootUv m0 : 31|1@1+ (1,0) [0|0] ""  X
 SG_ EPAS3S_a029_phaseVbootUv m0 : 32|1@1+ (1,0) [0|0] ""  X
 SG_ EPAS3S_a030_phaseWbootUv m0 : 33|1@1+ (1,0) [0|0] ""  X
 SG_ EPAS3S_a031_phaseFeedbackError m0 : 34|1@1+ (1,0) [0|0] ""  X
 SG_ EPAS3S_a032_vRegOutputUv m0 : 35|1@1+ (1,0) [0|0] ""  X
 SG_ EPAS3S_a033_vRegOutputOv m0 : 36|1@1+ (1,0) [0|0] ""  X
 SG_ EPAS3S_a034_vRegError m0 : 37|1@1+ (1,0) [0|0] ""  X
 SG_ EPAS3S_a035_vbbSupplyUv m0 : 38|1@1+ (1,0) [0|0] ""  X
 SG_ EPAS3S_a036_vbbSupplyOv m0 : 39|1@1+ (1,0) [0|0] ""  X
 SG_ EPAS3S_a037_motPos1ParityError m0 : 40|1@1+ (1,0) [0|0] ""  X
 SG_ EPAS3S_a038_motPos1Uv m0 : 41|1@1+ (1,0) [0|0] ""  X
 SG_ EPAS3S_a039_motPos1MagnetMia m0 : 42|1@1+ (1,0) [0|0] ""  X
 SG_ EPAS3S_a040_motPos1LogicError m0 : 43|1@1+ (1,0) [0|0] ""  X
 SG_ EPAS3S_a041_motPos1tempError m0 : 44|1@1+ (1,0) [0|0] ""  X
 SG_ EPAS3S_a042_motPos2ParityError m0 : 45|1@1+ (1,0) [0|0] ""  X
 SG_ EPAS3S_a043_motPos2Uv m0 : 46|1@1+ (1,0) [0|0] ""  X
 SG_ EPAS3S_a044_motPos2MagnetMia m0 : 47|1@1+ (1,0) [0|0] ""  X
 SG_ EPAS3S_a045_motPos2LogicError m0 : 48|1@1+ (1,0) [0|0] ""  X
 SG_ EPAS3S_a046_motPos2tempError m0 : 49|1@1+ (1,0) [0|0] ""  X
 SG_ EPAS3S_a047_motPosCorrError m0 : 50|1@1+ (1,0) [0|0] ""  X
 SG_ EPAS3S_a048_motPosCalError m0 : 51|1@1+ (1,0) [0|0] ""  X
 SG_ EPAS3S_a049_piCtrlError m0 : 52|1@1+ (1,0) [0|0] ""  X
 SG_ EPAS3S_a050_mcuSmuError m0 : 53|1@1+ (1,0) [0|0] ""  X
 SG_ EPAS3S_a051_mcuSupError m0 : 54|1@1+ (1,0) [0|0] ""  X
 SG_ EPAS3S_a052_intWatchdogError m0 : 55|1@1+ (1,0) [0|0] ""  X
 SG_ EPAS3S_a053_extWatchdogError m0 : 56|1@1+ (1,0) [0|0] ""  X
 SG_ EPAS3S_a054_memoryProtectError m0 : 57|1@1+ (1,0) [0|0] ""  X
 SG_ EPAS3S_a055_floatPointError m0 : 58|1@1+ (1,0) [0|0] ""  X
 SG_ EPAS3S_a056_battUv m0 : 59|1@1+ (1,0) [0|0] ""  X
 SG_ EPAS3S_a057_battUvReduced m0 : 60|1@1+ (1,0) [0|0] ""  X
 SG_ EPAS3S_a058_battOv m0 : 61|1@1+ (1,0) [0|0] ""  X
 SG_ EPAS3S_a059_battOvReduced m0 : 62|1@1+ (1,0) [0|0] ""  X
 SG_ EPAS3S_a060_battBridgeDiff m0 : 63|1@1+ (1,0) [0|0] ""  X
 SG_ EPAS3S_a061_bridgeUv m1 : 4|1@1+ (1,0) [0|0] ""  X
 SG_ EPAS3S_a062_assistCorrError m1 : 5|1@1+ (1,0) [0|0] ""  X
 SG_ EPAS3S_a063_dampCorrError m1 : 6|1@1+ (1,0) [0|0] ""  X
 SG_ EPAS3S_a064_phaseCompCorrError m1 : 7|1@1+ (1,0) [0|0] ""  X
 SG_ EPAS3S_a065_trqTarCorrError m1 : 8|1@1+ (1,0) [0|0] ""  X
 SG_ EPAS3S_a066_returnCorrError m1 : 9|1@1+ (1,0) [0|0] ""  X
 SG_ EPAS3S_a067_yawDampCorrError m1 : 10|1@1+ (1,0) [0|0] ""  X
 SG_ EPAS3S_a068_hystCorrError m1 : 11|1@1+ (1,0) [0|0] ""  X
 SG_ EPAS3S_a069_eacCorrError m1 : 12|1@1+ (1,0) [0|0] ""  X
 SG_ EPAS3S_a070_hodCorrError m1 : 13|1@1+ (1,0) [0|0] ""  X
 SG_ EPAS3S_a071_vehSpdCorrError m1 : 14|1@1+ (1,0) [0|0] ""  X
 SG_ EPAS3S_a072_motFeedFwdError m1 : 15|1@1+ (1,0) [0|0] ""  X
 SG_ EPAS3S_a073_motParEstError m1 : 16|1@1+ (1,0) [0|0] ""  X
 SG_ EPAS3S_a074_overHeatProtect m1 : 17|1@1+ (1,0) [0|0] ""  X
 SG_ EPAS3S_a075_fspPwrCut m1 : 18|1@1+ (1,0) [0|0] ""  X
 SG_ EPAS3S_a076_tempSensOutofRange m1 : 19|1@1+ (1,0) [0|0] ""  X
 SG_ EPAS3S_a077_highSideFetError m1 : 20|1@1+ (1,0) [0|0] ""  X
 SG_ EPAS3S_a078_phaseDisconnectError m1 : 21|1@1+ (1,0) [0|0] ""  X
 SG_ EPAS3S_a079_backupCurrentPlaus m1 : 22|1@1+ (1,0) [0|0] ""  X
 SG_ EPAS3S_a080_ecuInitArbError m1 : 23|1@1+ (1,0) [0|0] ""  X
 SG_ EPAS3S_a081_coggCompError m1 : 24|1@1+ (1,0) [0|0] ""  X
 SG_ EPAS3S_a082_polarityCalError m1 : 25|1@1+ (1,0) [0|0] ""  X
 SG_ EPAS3S_a083_crcMismatch m1 : 26|1@1+ (1,0) [0|0] ""  X
 SG_ EPAS3S_a084_eacCancelled m1 : 27|1@1+ (1,0) [0|0] ""  X
 SG_ EPAS3S_a085_canBusOff m1 : 28|1@1+ (1,0) [0|0] ""  X
 SG_ EPAS3S_a086_dasMia m1 : 29|1@1+ (1,0) [0|0] ""  X
 SG_ EPAS3S_a087_dasCntError m1 : 30|1@1+ (1,0) [0|0] ""  X
 SG_ EPAS3S_a088_dasCsError m1 : 31|1@1+ (1,0) [0|0] ""  X
 SG_ EPAS3S_a089_espWsMia m1 : 32|1@1+ (1,0) [0|0] ""  X
 SG_ EPAS3S_a090_espWsCntError m1 : 33|1@1+ (1,0) [0|0] ""  X
 SG_ EPAS3S_a091_espWsCsError m1 : 34|1@1+ (1,0) [0|0] ""  X
 SG_ EPAS3S_a092_espWrMia m1 : 35|1@1+ (1,0) [0|0] ""  X
 SG_ EPAS3S_a093_espWrCntError m1 : 36|1@1+ (1,0) [0|0] ""  X
 SG_ EPAS3S_a094_espWrCsError m1 : 37|1@1+ (1,0) [0|0] ""  X
 SG_ EPAS3S_a095_espWsStatus m1 : 38|1@1+ (1,0) [0|0] ""  X
 SG_ EPAS3S_a096_rcmMia m1 : 39|1@1+ (1,0) [0|0] ""  X
 SG_ EPAS3S_a097_rcmCntError m1 : 40|1@1+ (1,0) [0|0] ""  X
 SG_ EPAS3S_a098_rcmCsError m1 : 41|1@1+ (1,0) [0|0] ""  X
 SG_ EPAS3S_a099_yawRateStatus m1 : 42|1@1+ (1,0) [0|0] ""  X
 SG_ EPAS3S_a100_diMia m1 : 43|1@1+ (1,0) [0|0] ""  X
 SG_ EPAS3S_a101_diCntError m1 : 44|1@1+ (1,0) [0|0] ""  X
 SG_ EPAS3S_a102_diCsError m1 : 45|1@1+ (1,0) [0|0] ""  X
 SG_ EPAS3S_a103_vcFrontMia m1 : 46|1@1+ (1,0) [0|0] ""  X
 SG_ EPAS3S_a104_vcFrontCntError m1 : 47|1@1+ (1,0) [0|0] ""  X
 SG_ EPAS3S_a105_vcFrontCsError m1 : 48|1@1+ (1,0) [0|0] ""  X
 SG_ EPAS3S_a106_vcFrontTempMia m1 : 49|1@1+ (1,0) [0|0] ""  X
 SG_ EPAS3S_a107_uiTuneReqMia m1 : 50|1@1+ (1,0) [0|0] ""  X
 SG_ EPAS3S_a108_uiTuneReqCntError m1 : 51|1@1+ (1,0) [0|0] ""  X
 SG_ EPAS3S_a109_uiTuneReqCsError m1 : 52|1@1+ (1,0) [0|0] ""  X
 SG_ EPAS3S_a110_sasMia m1 : 53|1@1+ (1,0) [0|0] ""  X
 SG_ EPAS3S_a111_sasCntError m1 : 54|1@1+ (1,0) [0|0] ""  X
 SG_ EPAS3S_a112_sasCsError m1 : 55|1@1+ (1,0) [0|0] ""  X
 SG_ EPAS3S_a113_sasStatusError m1 : 56|1@1+ (1,0) [0|0] ""  X
 SG_ EPAS3S_a114_gtwConfigMia m1 : 57|1@1+ (1,0) [0|0] ""  X
 SG_ EPAS3S_a115_ecuStatMia m1 : 58|1@1+ (1,0) [0|0] ""  X
 SG_ EPAS3S_a116_ecuStatCntError m1 : 59|1@1+ (1,0) [0|0] ""  X
 SG_ EPAS3S_a117_ecuStatCrcError m1 : 60|1@1+ (1,0) [0|0] ""  X
 SG_ EPAS3S_a118_privateBusOff m1 : 61|1@1+ (1,0) [0|0] ""  X
 SG_ EPAS3S_a119_pvtEcuStatMia m1 : 62|1@1+ (1,0) [0|0] ""  X
 SG_ EPAS3S_a120_pvtEcuStatCntError m1 : 63|1@1+ (1,0) [0|0] ""  X
 SG_ EPAS3S_a121_pvtEcuStatCrcError m2 : 4|1@1+ (1,0) [0|0] ""  X
 SG_ EPAS3S_a122_olpActive m2 : 5|1@1+ (1,0) [0|0] ""  X
 SG_ EPAS3S_a123_combEcu2StatFail m2 : 6|1@1+ (1,0) [0|0] ""  X
 SG_ EPAS3S_a124_tempSensStuckInRange m2 : 7|1@1+ (1,0) [0|0] ""  X
 SG_ EPAS3S_a125_trqSensTrimOutRange m2 : 8|1@1+ (1,0) [0|0] ""  X
 SG_ EPAS3S_a126_apsMia m2 : 9|1@1+ (1,0) [0|0] ""  X
 SG_ EPAS3S_a127_apsCntError m2 : 10|1@1+ (1,0) [0|0] ""  X
 SG_ EPAS3S_a128_apsCsError m2 : 11|1@1+ (1,0) [0|0] ""  X
 SG_ EPAS3S_a129_combEcu1StatFail m2 : 12|1@1+ (1,0) [0|0] ""  X
 SG_ EPAS3S_a130_sasOffsetNotCal m2 : 13|1@1+ (1,0) [0|0] ""  X

BO_ 785 EPAS3S_info: 8 CH
 SG_ EPAS3S_infoIndex M : 0|8@1+ (1,0) [0|0] ""  X
 SG_ EPAS3S_infoBuildType m10 : 8|8@1+ (1,0) [0|0] ""  X
 SG_ EPAS3S_infoComponentID m10 : 48|16@1+ (1,0) [0|0] ""  X
 SG_ EPAS3S_infoPcbaID m11 : 16|8@1+ (1,0) [0|0] ""  X
 SG_ EPAS3S_infoAssemblyID m11 : 24|8@1+ (1,0) [0|0] ""  X
 SG_ EPAS3S_infoUsageID m11 : 32|16@1+ (1,0) [0|0] ""  X
 SG_ EPAS3S_infoBootUdsProtoVersion m20 : 8|8@1+ (1,0) [0|0] ""  X
 SG_ EPAS3S_infoBootloaderCRC m20 : 32|32@1+ (1,0) [0|0] ""  X
 SG_ EPAS3S_infoApplicationCRC m13 : 32|32@1+ (1,0) [0|0] ""  X

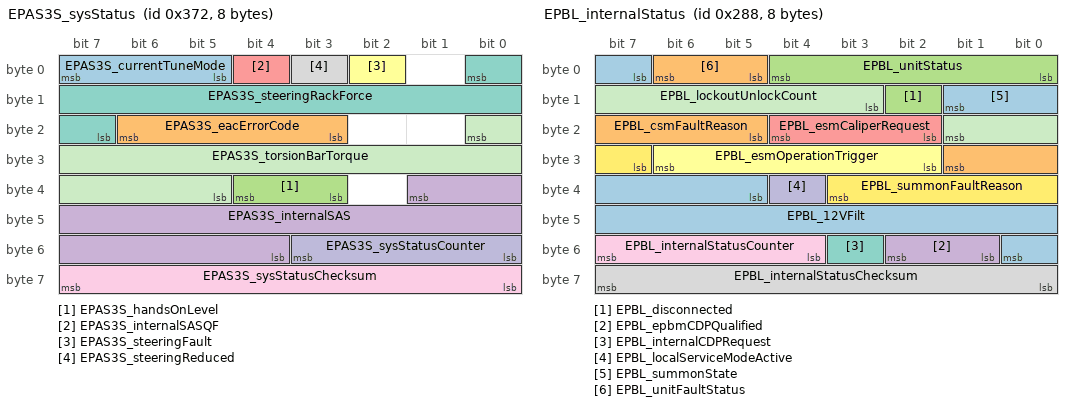
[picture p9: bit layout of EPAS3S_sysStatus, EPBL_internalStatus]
BO_ 882 EPAS3S_sysStatus: 8 VEH
 SG_ EPAS3S_currentTuneMode : 5|3@1+ (1,0) [0|0] ""  X
 SG_ EPAS3S_eacErrorCode : 19|4@1+ (1,0) [0|0] ""  X
 SG_ EPAS3S_handsOnLevel : 35|2@1+ (1,0) [0|0] ""  X
 SG_ EPAS3S_internalSAS : 33|14@0+ (0.1,-819.2) [0|0] "deg"  X
 SG_ EPAS3S_internalSASQF : 4|1@1+ (1,0) [0|0] ""  X
 SG_ EPAS3S_steeringFault : 2|1@1+ (1,0) [0|0] ""  X
 SG_ EPAS3S_steeringRackForce : 0|10@0+ (50,-25575) [0|0] "N"  X
 SG_ EPAS3S_steeringReduced : 3|1@1+ (1,0) [0|0] ""  X
 SG_ EPAS3S_sysStatusChecksum : 56|8@1+ (1,0) [0|0] ""  X
 SG_ EPAS3S_sysStatusCounter : 48|4@1+ (1,0) [0|0] ""  X
 SG_ EPAS3S_torsionBarTorque : 16|12@0+ (0.01,-20.5) [0|0] "Nm"  X

BO_ 968 EPBL_alertMatrix: 8 VEH
 SG_ EPBL_matrixIndex M : 0|4@1+ (1,0) [0|0] ""  X
 SG_ EPBL_a001_WatchdogReset m0 : 4|1@1+ (1,0) [0|0] ""  X
 SG_ EPBL_a002_PowerLossReset m0 : 5|1@1+ (1,0) [0|0] ""  X
 SG_ EPBL_a003_SWAssertion m0 : 6|1@1+ (1,0) [0|0] ""  X
 SG_ EPBL_a010_ExtSupplyVoltError m0 : 13|1@1+ (1,0) [0|0] ""  X
 SG_ EPBL_a012_CPUReset m0 : 15|1@1+ (1,0) [0|0] ""  X
 SG_ EPBL_a013_AlertManagerFault m0 : 16|1@1+ (1,0) [0|0] ""  X
 SG_ EPBL_a015_NVMMAlert m0 : 18|1@1+ (1,0) [0|0] ""  X
 SG_ EPBL_a021_TaskSchedulerError m0 : 24|1@1+ (1,0) [0|0] ""  X
 SG_ EPBL_a022_TaskInitError m0 : 25|1@1+ (1,0) [0|0] ""  X
 SG_ EPBL_a031_UDSActive m0 : 34|1@1+ (1,0) [0|0] ""  X
 SG_ EPBL_a041_HighCPULoad m0 : 44|1@1+ (1,0) [0|0] ""  X
 SG_ EPBL_a042_HighStackUsage m0 : 45|1@1+ (1,0) [0|0] ""  X
 SG_ EPBL_a043_Task1msError m0 : 46|1@1+ (1,0) [0|0] ""  X
 SG_ EPBL_a044_Task10msError m0 : 47|1@1+ (1,0) [0|0] ""  X
 SG_ EPBL_a045_Task100msError m0 : 48|1@1+ (1,0) [0|0] ""  X
 SG_ EPBL_a046_Task1000msError m0 : 49|1@1+ (1,0) [0|0] ""  X
 SG_ EPBL_a059_inputResistanceHigh m0 : 62|1@1+ (1,0) [0|0] ""  X
 SG_ EPBL_a060_engineeringBuild m0 : 63|1@1+ (1,0) [0|0] ""  X
 SG_ EPBL_a061_XCPConnected m1 : 4|1@1+ (1,0) [0|0] ""  X
 SG_ EPBL_a062_XCPWasConnected m1 : 5|1@1+ (1,0) [0|0] ""  X
 SG_ EPBL_a063_SwitchFault m1 : 6|1@1+ (1,0) [0|0] ""  X
 SG_ EPBL_a064_busSleepReqTimeout m1 : 7|1@1+ (1,0) [0|0] ""  X
 SG_ EPBL_a097_CMP_MIA m1 : 40|1@1+ (1,0) [0|0] ""  X
 SG_ EPBL_a098_DI_THERMAL_MIA m1 : 41|1@1+ (1,0) [0|0] ""  X
 SG_ EPBL_a099_PARK_MIA m1 : 42|1@1+ (1,0) [0|0] ""  X
 SG_ EPBL_a100_CANbus_MIA m1 : 43|1@1+ (1,0) [0|0] ""  X
 SG_ EPBL_a101_PM_MIA m1 : 44|1@1+ (1,0) [0|0] ""  X
 SG_ EPBL_a102_PTC_MIA m1 : 45|1@1+ (1,0) [0|0] ""  X
 SG_ EPBL_a103_CP_MIA m1 : 46|1@1+ (1,0) [0|0] ""  X
 SG_ EPBL_a104_DAS_MIA m1 : 47|1@1+ (1,0) [0|0] ""  X
 SG_ EPBL_a105_TAS_MIA m1 : 48|1@1+ (1,0) [0|0] ""  X
 SG_ EPBL_a106_PCS_MIA m1 : 49|1@1+ (1,0) [0|0] ""  X
 SG_ EPBL_a107_BMS_MIA m1 : 50|1@1+ (1,0) [0|0] ""  X
 SG_ EPBL_a108_DIS_MIA m1 : 51|1@1+ (1,0) [0|0] ""  X
 SG_ EPBL_a109_RCM_MIA m1 : 52|1@1+ (1,0) [0|0] ""  X
 SG_ EPBL_a110_GTW_MIA m1 : 53|1@1+ (1,0) [0|0] ""  X
 SG_ EPBL_a111_EPBR_MIA m1 : 54|1@1+ (1,0) [0|0] ""  X
 SG_ EPBL_a112_EPBL_MIA m1 : 55|1@1+ (1,0) [0|0] ""  X
 SG_ EPBL_a113_UI_MIA m1 : 56|1@1+ (1,0) [0|0] ""  X
 SG_ EPBL_a114_ESP_MIA m1 : 57|1@1+ (1,0) [0|0] ""  X
 SG_ EPBL_a115_VCSEC_MIA m1 : 58|1@1+ (1,0) [0|0] ""  X
 SG_ EPBL_a116_VCRIGHT_MIA m1 : 59|1@1+ (1,0) [0|0] ""  X
 SG_ EPBL_a117_VCLEFT_MIA m1 : 60|1@1+ (1,0) [0|0] ""  X
 SG_ EPBL_a118_VCFRONT_MIA m1 : 61|1@1+ (1,0) [0|0] ""  X
 SG_ EPBL_a119_SCCM_MIA m1 : 62|1@1+ (1,0) [0|0] ""  X
 SG_ EPBL_a120_DI_DRIVE_MIA m1 : 63|1@1+ (1,0) [0|0] ""  X
 SG_ EPBL_a121_nDriveFault m2 : 4|1@1+ (1,0) [0|0] ""  X
 SG_ EPBL_a122_Oc m2 : 5|1@1+ (1,0) [0|0] ""  X
 SG_ EPBL_a123_Uc m2 : 6|1@1+ (1,0) [0|0] ""  X
 SG_ EPBL_a124_calOutOfBounds m2 : 7|1@1+ (1,0) [0|0] ""  X
 SG_ EPBL_a125_IdleVMismatch m2 : 8|1@1+ (1,0) [0|0] ""  X
 SG_ EPBL_a126_MotorNVoltLow m2 : 9|1@1+ (1,0) [0|0] ""  X
 SG_ EPBL_a127_MotorNVoltHigh m2 : 10|1@1+ (1,0) [0|0] ""  X
 SG_ EPBL_a128_MotorPVoltHigh m2 : 11|1@1+ (1,0) [0|0] ""  X
 SG_ EPBL_a134_NvOv m2 : 17|1@1+ (1,0) [0|0] ""  X
 SG_ EPBL_a135_NvUv m2 : 18|1@1+ (1,0) [0|0] ""  X
 SG_ EPBL_a136_PvOv m2 : 19|1@1+ (1,0) [0|0] ""  X
 SG_ EPBL_a137_PvUv m2 : 20|1@1+ (1,0) [0|0] ""  X
 SG_ EPBL_a138_NVMWriteTime m2 : 21|1@1+ (1,0) [0|0] ""  X
 SG_ EPBL_a141_invalidState m2 : 24|1@1+ (1,0) [0|0] ""  X
 SG_ EPBL_a170_12vOv m2 : 53|1@1+ (1,0) [0|0] ""  X
 SG_ EPBL_a171_12vUv m2 : 54|1@1+ (1,0) [0|0] ""  X
 SG_ EPBL_a172_SPI_MIA m2 : 55|1@1+ (1,0) [0|0] ""  X
 SG_ EPBL_a173_hiCurrentMissing m2 : 56|1@1+ (1,0) [0|0] ""  X
 SG_ EPBL_a174_csmReleaseFailed m2 : 57|1@1+ (1,0) [0|0] ""  X
 SG_ EPBL_a175_csmReleaseRetry m2 : 58|1@1+ (1,0) [0|0] ""  X
 SG_ EPBL_a176_csmApplyFailed m2 : 59|1@1+ (1,0) [0|0] ""  X
 SG_ EPBL_a177_csmApplyRetry m2 : 60|1@1+ (1,0) [0|0] ""  X
 SG_ EPBL_a178_caliperStateUnknown m2 : 61|1@1+ (1,0) [0|0] ""  X
 SG_ EPBL_a179_epbProblem m2 : 62|1@1+ (1,0) [0|0] ""  X
 SG_ EPBL_a180_dynamicActive m2 : 63|1@1+ (1,0) [0|0] ""  X
 SG_ EPBL_a181_TooSteepGradeToPark m3 : 4|1@1+ (1,0) [0|0] ""  X
 SG_ EPBL_a182_OneEPBAppliedUnsecEnv m3 : 5|1@1+ (1,0) [0|0] ""  X
 SG_ EPBL_a183_cdpNotAvailable m3 : 6|1@1+ (1,0) [0|0] ""  X
 SG_ EPBL_a184_dynamicParkAbort m3 : 7|1@1+ (1,0) [0|0] ""  X
 SG_ EPBL_a185_summonAborted m3 : 8|1@1+ (1,0) [0|0] ""  X
 SG_ EPBL_a186_externalParkAbort m3 : 9|1@1+ (1,0) [0|0] ""  X
 SG_ EPBL_a187_cdpDynamic m3 : 10|1@1+ (1,0) [0|0] ""  X
 SG_ EPBL_a188_epbDynamic m3 : 11|1@1+ (1,0) [0|0] ""  X
 SG_ EPBL_a189_epbDynamicParkCanceled m3 : 12|1@1+ (1,0) [0|0] ""  X
 SG_ EPBL_a190_csmApplyDegraded m3 : 13|1@1+ (1,0) [0|0] ""  X
 SG_ EPBL_a191_csmReleaseDegraded m3 : 14|1@1+ (1,0) [0|0] ""  X
 SG_ EPBL_a195_parkForDriverIsLeaving m3 : 18|1@1+ (1,0) [0|0] ""  X
 SG_ EPBL_a200_PmUnparkNotAllowed m3 : 23|1@1+ (1,0) [0|0] ""  X
 SG_ EPBL_a201_hwBrakeTypeMismatch m3 : 24|1@1+ (1,0) [0|0] ""  X
 SG_ EPBL_a216_SPI_MIA_debugData1 m3 : 39|1@1+ (1,0) [0|0] ""  X
 SG_ EPBL_a217_SPI_MIA_debugData2 m3 : 40|1@1+ (1,0) [0|0] ""  X
 SG_ EPBL_a241_diOutputLocked m4 : 4|1@1+ (1,0) [0|0] ""  X
 SG_ EPBL_a242_hvOutputLocked m4 : 5|1@1+ (1,0) [0|0] ""  X
 SG_ EPBL_a243_bdwUnavailable m4 : 6|1@1+ (1,0) [0|0] ""  X
 SG_ EPBL_a244_WinchModeActive m4 : 7|1@1+ (1,0) [0|0] ""  X
 SG_ EPBL_a245_serviceModeActive m4 : 8|1@1+ (1,0) [0|0] ""  X
 SG_ EPBL_a246_idleFaultApply m4 : 9|1@1+ (1,0) [0|0] ""  X
 SG_ EPBL_a247_csmDynamicApplyRetry m4 : 10|1@1+ (1,0) [0|0] ""  X
 SG_ EPBL_a248_csmDynamicApplyFailed m4 : 11|1@1+ (1,0) [0|0] ""  X
 SG_ EPBL_a249_idleFaultRelease m4 : 12|1@1+ (1,0) [0|0] ""  X
 SG_ EPBL_a250_WinchModeCanceled m4 : 13|1@1+ (1,0) [0|0] ""  X
 SG_ EPBL_a251_currentVarianceHigh m4 : 14|1@1+ (1,0) [0|0] ""  X

BO_ 1992 EPBL_info: 8 VEH
 SG_ EPBL_infoIndex M : 0|8@1+ (1,0) [0|0] ""  X
 SG_ EPBL_infoBuildType m10 : 8|3@1+ (1,0) [0|0] ""  X
 SG_ EPBL_infoBuildConfigId m10 : 16|16@1+ (1,0) [0|0] ""  X
 SG_ EPBL_infoHardwareId m10 : 32|16@1+ (1,0) [0|0] ""  X
 SG_ EPBL_infoComponentId m10 : 48|16@1+ (1,0) [0|0] ""  X
 SG_ EPBL_infoPcbaId m11 : 8|8@1+ (1,0) [0|0] ""  X
 SG_ EPBL_infoAssemblyId m11 : 16|8@1+ (1,0) [0|0] ""  X
 SG_ EPBL_infoUsageId m11 : 24|16@1+ (1,0) [0|0] ""  X
 SG_ EPBL_infoSubUsageId m11 : 40|16@1+ (1,0) [0|0] ""  X
 SG_ EPBL_infoAppCrc m13 : 8|32@1+ (1,0) [0|0] ""  X
 SG_ EPBL_infoAppGitHash m17 : 10|54@1+ (4,0) [0|0] ""  X
 SG_ EPBL_infoBootGitHash m18 : 10|54@1+ (4,0) [0|0] ""  X
 SG_ EPBL_infoPlatformType m19 : 8|8@1+ (1,0) [0|0] ""  X
 SG_ EPBL_infoBootUdsProtoVersion m20 : 8|16@1+ (1,0) [0|0] ""  X
 SG_ EPBL_infoBootCrc m20 : 24|32@1+ (1,0) [0|0] ""  X

BO_ 648 EPBL_internalStatus: 8 VEH
 SG_ EPBL_12VFilt : 37|12@1+ (0.00544368,0) [0|0] "V"  X
 SG_ EPBL_csmFaultReason : 21|5@1+ (1,0) [0|0] ""  X
 SG_ EPBL_disconnected : 10|1@1+ (1,0) [0|0] ""  X
 SG_ EPBL_epbmCDPQualified : 49|2@1+ (1,0) [0|0] ""  X
 SG_ EPBL_esmCaliperRequest : 18|3@1+ (1,0) [0|0] ""  X
 SG_ EPBL_esmOperationTrigger : 26|5@1+ (1,0) [0|0] ""  X
 SG_ EPBL_internalCDPRequest : 51|1@1+ (1,0) [0|0] ""  X
 SG_ EPBL_internalStatusChecksum : 56|8@1+ (1,0) [0|0] ""  X
 SG_ EPBL_internalStatusCounter : 52|4@1+ (1,0) [0|0] ""  X
 SG_ EPBL_localServiceModeActive : 36|1@1+ (1,0) [0|0] ""  X
 SG_ EPBL_lockoutUnlockCount : 11|7@1+ (1,0) [0|0] ""  X
 SG_ EPBL_summonFaultReason : 31|5@1+ (1,0) [0|0] ""  X
 SG_ EPBL_summonState : 7|3@1+ (1,0) [0|0] ""  X
 SG_ EPBL_unitFaultStatus : 5|2@1+ (1,0) [0|0] ""  X
 SG_ EPBL_unitStatus : 0|5@1+ (1,0) [0|0] ""  X

BO_ 681 EPBL_status: 8 VEH
 SG_ EPBL_blockDrive : 51|1@1+ (1,0) [0|0] ""  X
 SG_ EPBL_bothDisconnected : 50|1@1+ (1,0) [0|0] ""  X
 SG_ EPBL_brakeDiscWipeRequest : 30|2@1+ (1,0) [0|0] ""  X
 SG_ EPBL_brakeHWConfigMismatch : 19|1@1+ (1,0) [0|0] ""  X
 SG_ EPBL_brakeLight : 18|1@1+ (1,0) [0|0] ""  X
 SG_ EPBL_cdpRequest : 27|1@1+ (1,0) [0|0] ""  X
 SG_ EPBL_espPowerRequest : 46|1@1+ (1,0) [0|0] ""  X
 SG_ EPBL_hornRequest : 48|1@1+ (1,0) [0|0] ""  X
 SG_ EPBL_okToPark : 47|1@1+ (1,0) [0|0] ""  X
 SG_ EPBL_requestUserConfirmation : 21|1@1+ (1,0) [0|0] ""  X
 SG_ EPBL_statusChecksum : 56|8@1+ (1,0) [0|0] ""  X
 SG_ EPBL_statusCounter : 52|4@1+ (1,0) [0|0] ""  X
 SG_ EPBL_summonEnabled : 17|1@1+ (1,0) [0|0] ""  X
 SG_ EPBL_systemStatus : 0|4@1+ (1,0) [0|0] ""  X
 SG_ EPBL_telltale : 16|1@1+ (1,0) [0|0] ""  X
 SG_ EPBL_uiButtonAvailable : 20|1@1+ (1,0) [0|0] ""  X
 SG_ EPBL_updateMode : 24|1@1+ (1,0) [0|0] ""  X
 SG_ EPBL_winchModeActive : 23|1@1+ (1,0) [0|0] ""  X
 SG_ EPBL_winchModeAvailable : 49|1@1+ (1,0) [0|0] ""  X
 SG_ EPBL_winchModeTimer : 32|12@1+ (1,0) [0|0] ""  X

BO_ 1000 EPBR_alertMatrix: 8 VEH
 SG_ EPBR_matrixIndex M : 0|4@1+ (1,0) [0|0] ""  X
 SG_ EPBR_a001_WatchdogReset m0 : 4|1@1+ (1,0) [0|0] ""  X
 SG_ EPBR_a002_PowerLossReset m0 : 5|1@1+ (1,0) [0|0] ""  X
 SG_ EPBR_a003_SWAssertion m0 : 6|1@1+ (1,0) [0|0] ""  X
 SG_ EPBR_a010_ExtSupplyVoltError m0 : 13|1@1+ (1,0) [0|0] ""  X
 SG_ EPBR_a012_CPUReset m0 : 15|1@1+ (1,0) [0|0] ""  X
 SG_ EPBR_a013_AlertManagerFault m0 : 16|1@1+ (1,0) [0|0] ""  X
 SG_ EPBR_a015_NVMMAlert m0 : 18|1@1+ (1,0) [0|0] ""  X
 SG_ EPBR_a021_TaskSchedulerError m0 : 24|1@1+ (1,0) [0|0] ""  X
 SG_ EPBR_a022_TaskInitError m0 : 25|1@1+ (1,0) [0|0] ""  X
 SG_ EPBR_a031_UDSActive m0 : 34|1@1+ (1,0) [0|0] ""  X
 SG_ EPBR_a041_HighCPULoad m0 : 44|1@1+ (1,0) [0|0] ""  X
 SG_ EPBR_a042_HighStackUsage m0 : 45|1@1+ (1,0) [0|0] ""  X
 SG_ EPBR_a043_Task1msError m0 : 46|1@1+ (1,0) [0|0] ""  X
 SG_ EPBR_a044_Task10msError m0 : 47|1@1+ (1,0) [0|0] ""  X
 SG_ EPBR_a045_Task100msError m0 : 48|1@1+ (1,0) [0|0] ""  X
 SG_ EPBR_a046_Task1000msError m0 : 49|1@1+ (1,0) [0|0] ""  X
 SG_ EPBR_a059_inputResistanceHigh m0 : 62|1@1+ (1,0) [0|0] ""  X
 SG_ EPBR_a060_engineeringBuild m0 : 63|1@1+ (1,0) [0|0] ""  X
 SG_ EPBR_a061_XCPConnected m1 : 4|1@1+ (1,0) [0|0] ""  X
 SG_ EPBR_a062_XCPWasConnected m1 : 5|1@1+ (1,0) [0|0] ""  X
 SG_ EPBR_a063_SwitchFault m1 : 6|1@1+ (1,0) [0|0] ""  X
 SG_ EPBR_a064_busSleepReqTimeout m1 : 7|1@1+ (1,0) [0|0] ""  X
 SG_ EPBR_a097_CMP_MIA m1 : 40|1@1+ (1,0) [0|0] ""  X
 SG_ EPBR_a098_DI_THERMAL_MIA m1 : 41|1@1+ (1,0) [0|0] ""  X
 SG_ EPBR_a099_PARK_MIA m1 : 42|1@1+ (1,0) [0|0] ""  X
 SG_ EPBR_a100_CANbus_MIA m1 : 43|1@1+ (1,0) [0|0] ""  X
 SG_ EPBR_a101_PM_MIA m1 : 44|1@1+ (1,0) [0|0] ""  X
 SG_ EPBR_a102_PTC_MIA m1 : 45|1@1+ (1,0) [0|0] ""  X
 SG_ EPBR_a103_CP_MIA m1 : 46|1@1+ (1,0) [0|0] ""  X
 SG_ EPBR_a104_DAS_MIA m1 : 47|1@1+ (1,0) [0|0] ""  X
 SG_ EPBR_a105_TAS_MIA m1 : 48|1@1+ (1,0) [0|0] ""  X
 SG_ EPBR_a106_PCS_MIA m1 : 49|1@1+ (1,0) [0|0] ""  X
 SG_ EPBR_a107_BMS_MIA m1 : 50|1@1+ (1,0) [0|0] ""  X
 SG_ EPBR_a108_DIS_MIA m1 : 51|1@1+ (1,0) [0|0] ""  X
 SG_ EPBR_a109_RCM_MIA m1 : 52|1@1+ (1,0) [0|0] ""  X
 SG_ EPBR_a110_GTW_MIA m1 : 53|1@1+ (1,0) [0|0] ""  X
 SG_ EPBR_a111_EPBR_MIA m1 : 54|1@1+ (1,0) [0|0] ""  X
 SG_ EPBR_a112_EPBL_MIA m1 : 55|1@1+ (1,0) [0|0] ""  X
 SG_ EPBR_a113_UI_MIA m1 : 56|1@1+ (1,0) [0|0] ""  X
 SG_ EPBR_a114_ESP_MIA m1 : 57|1@1+ (1,0) [0|0] ""  X
 SG_ EPBR_a115_VCSEC_MIA m1 : 58|1@1+ (1,0) [0|0] ""  X
 SG_ EPBR_a116_VCRIGHT_MIA m1 : 59|1@1+ (1,0) [0|0] ""  X
 SG_ EPBR_a117_VCLEFT_MIA m1 : 60|1@1+ (1,0) [0|0] ""  X
 SG_ EPBR_a118_VCFRONT_MIA m1 : 61|1@1+ (1,0) [0|0] ""  X
 SG_ EPBR_a119_SCCM_MIA m1 : 62|1@1+ (1,0) [0|0] ""  X
 SG_ EPBR_a120_DI_DRIVE_MIA m1 : 63|1@1+ (1,0) [0|0] ""  X
 SG_ EPBR_a121_nDriveFault m2 : 4|1@1+ (1,0) [0|0] ""  X
 SG_ EPBR_a122_Oc m2 : 5|1@1+ (1,0) [0|0] ""  X
 SG_ EPBR_a123_Uc m2 : 6|1@1+ (1,0) [0|0] ""  X
 SG_ EPBR_a124_calOutOfBounds m2 : 7|1@1+ (1,0) [0|0] ""  X
 SG_ EPBR_a125_IdleVMismatch m2 : 8|1@1+ (1,0) [0|0] ""  X
 SG_ EPBR_a126_MotorNVoltLow m2 : 9|1@1+ (1,0) [0|0] ""  X
 SG_ EPBR_a127_MotorNVoltHigh m2 : 10|1@1+ (1,0) [0|0] ""  X
 SG_ EPBR_a128_MotorPVoltHigh m2 : 11|1@1+ (1,0) [0|0] ""  X
 SG_ EPBR_a134_NvOv m2 : 17|1@1+ (1,0) [0|0] ""  X
 SG_ EPBR_a135_NvUv m2 : 18|1@1+ (1,0) [0|0] ""  X
 SG_ EPBR_a136_PvOv m2 : 19|1@1+ (1,0) [0|0] ""  X
 SG_ EPBR_a137_PvUv m2 : 20|1@1+ (1,0) [0|0] ""  X
 SG_ EPBR_a138_NVMWriteTime m2 : 21|1@1+ (1,0) [0|0] ""  X
 SG_ EPBR_a141_invalidState m2 : 24|1@1+ (1,0) [0|0] ""  X
 SG_ EPBR_a170_12vOv m2 : 53|1@1+ (1,0) [0|0] ""  X
 SG_ EPBR_a171_12vUv m2 : 54|1@1+ (1,0) [0|0] ""  X
 SG_ EPBR_a172_SPI_MIA m2 : 55|1@1+ (1,0) [0|0] ""  X
 SG_ EPBR_a173_hiCurrentMissing m2 : 56|1@1+ (1,0) [0|0] ""  X
 SG_ EPBR_a174_csmReleaseFailed m2 : 57|1@1+ (1,0) [0|0] ""  X
 SG_ EPBR_a175_csmReleaseRetry m2 : 58|1@1+ (1,0) [0|0] ""  X
 SG_ EPBR_a176_csmApplyFailed m2 : 59|1@1+ (1,0) [0|0] ""  X
 SG_ EPBR_a177_csmApplyRetry m2 : 60|1@1+ (1,0) [0|0] ""  X
 SG_ EPBR_a178_caliperStateUnknown m2 : 61|1@1+ (1,0) [0|0] ""  X
 SG_ EPBR_a179_epbProblem m2 : 62|1@1+ (1,0) [0|0] ""  X
 SG_ EPBR_a180_dynamicActive m2 : 63|1@1+ (1,0) [0|0] ""  X
 SG_ EPBR_a181_TooSteepGradeToPark m3 : 4|1@1+ (1,0) [0|0] ""  X
 SG_ EPBR_a182_OneEPBAppliedUnsecEnv m3 : 5|1@1+ (1,0) [0|0] ""  X
 SG_ EPBR_a183_cdpNotAvailable m3 : 6|1@1+ (1,0) [0|0] ""  X
 SG_ EPBR_a184_dynamicParkAbort m3 : 7|1@1+ (1,0) [0|0] ""  X
 SG_ EPBR_a185_summonAborted m3 : 8|1@1+ (1,0) [0|0] ""  X
 SG_ EPBR_a186_externalParkAbort m3 : 9|1@1+ (1,0) [0|0] ""  X
 SG_ EPBR_a187_cdpDynamic m3 : 10|1@1+ (1,0) [0|0] ""  X
 SG_ EPBR_a188_epbDynamic m3 : 11|1@1+ (1,0) [0|0] ""  X
 SG_ EPBR_a189_epbDynamicParkCanceled m3 : 12|1@1+ (1,0) [0|0] ""  X
 SG_ EPBR_a190_csmApplyDegraded m3 : 13|1@1+ (1,0) [0|0] ""  X
 SG_ EPBR_a191_csmReleaseDegraded m3 : 14|1@1+ (1,0) [0|0] ""  X
 SG_ EPBR_a195_parkForDriverIsLeaving m3 : 18|1@1+ (1,0) [0|0] ""  X
 SG_ EPBR_a200_PmUnparkNotAllowed m3 : 23|1@1+ (1,0) [0|0] ""  X
 SG_ EPBR_a201_hwBrakeTypeMismatch m3 : 24|1@1+ (1,0) [0|0] ""  X
 SG_ EPBR_a216_SPI_MIA_debugData1 m3 : 39|1@1+ (1,0) [0|0] ""  X
 SG_ EPBR_a217_SPI_MIA_debugData2 m3 : 40|1@1+ (1,0) [0|0] ""  X
 SG_ EPBR_a241_diOutputLocked m4 : 4|1@1+ (1,0) [0|0] ""  X
 SG_ EPBR_a242_hvOutputLocked m4 : 5|1@1+ (1,0) [0|0] ""  X
 SG_ EPBR_a243_bdwUnavailable m4 : 6|1@1+ (1,0) [0|0] ""  X
 SG_ EPBR_a244_WinchModeActive m4 : 7|1@1+ (1,0) [0|0] ""  X
 SG_ EPBR_a245_serviceModeActive m4 : 8|1@1+ (1,0) [0|0] ""  X
 SG_ EPBR_a246_idleFaultApply m4 : 9|1@1+ (1,0) [0|0] ""  X
 SG_ EPBR_a247_csmDynamicApplyRetry m4 : 10|1@1+ (1,0) [0|0] ""  X
 SG_ EPBR_a248_csmDynamicApplyFailed m4 : 11|1@1+ (1,0) [0|0] ""  X
 SG_ EPBR_a249_idleFaultRelease m4 : 12|1@1+ (1,0) [0|0] ""  X
 SG_ EPBR_a250_WinchModeCanceled m4 : 13|1@1+ (1,0) [0|0] ""  X
 SG_ EPBR_a251_currentVarianceHigh m4 : 14|1@1+ (1,0) [0|0] ""  X

BO_ 2024 EPBR_info: 8 VEH
 SG_ EPBR_infoIndex M : 0|8@1+ (1,0) [0|0] ""  X
 SG_ EPBR_infoBuildType m10 : 8|3@1+ (1,0) [0|0] ""  X
 SG_ EPBR_infoBuildConfigId m10 : 16|16@1+ (1,0) [0|0] ""  X
 SG_ EPBR_infoHardwareId m10 : 32|16@1+ (1,0) [0|0] ""  X
 SG_ EPBR_infoComponentId m10 : 48|16@1+ (1,0) [0|0] ""  X
 SG_ EPBR_infoPcbaId m11 : 8|8@1+ (1,0) [0|0] ""  X
 SG_ EPBR_infoAssemblyId m11 : 16|8@1+ (1,0) [0|0] ""  X
 SG_ EPBR_infoUsageId m11 : 24|16@1+ (1,0) [0|0] ""  X
 SG_ EPBR_infoSubUsageId m11 : 40|16@1+ (1,0) [0|0] ""  X
 SG_ EPBR_infoAppCrc m13 : 8|32@1+ (1,0) [0|0] ""  X
 SG_ EPBR_infoAppGitHash m17 : 10|54@1+ (4,0) [0|0] ""  X
 SG_ EPBR_infoBootGitHash m18 : 10|54@1+ (4,0) [0|0] ""  X
 SG_ EPBR_infoPlatformType m19 : 8|8@1+ (1,0) [0|0] ""  X
 SG_ EPBR_infoBootUdsProtoVersion m20 : 8|16@1+ (1,0) [0|0] ""  X
 SG_ EPBR_infoBootCrc m20 : 24|32@1+ (1,0) [0|0] ""  X

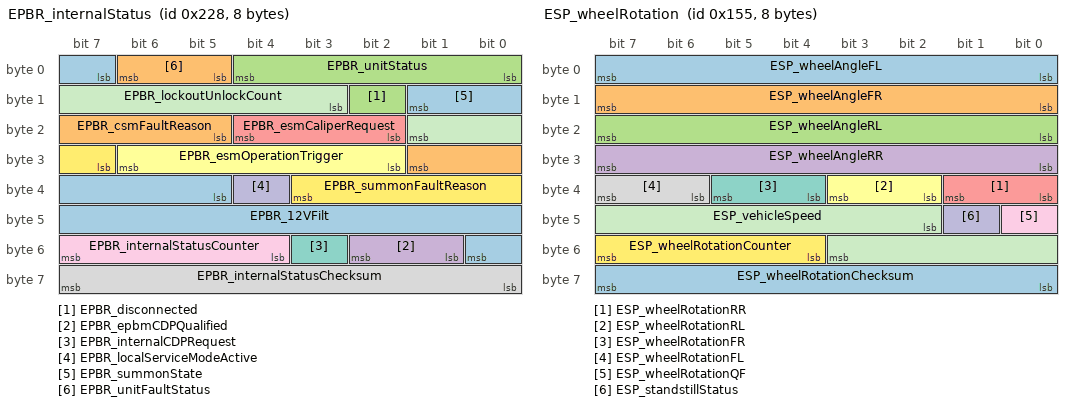
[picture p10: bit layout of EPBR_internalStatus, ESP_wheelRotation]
BO_ 552 EPBR_internalStatus: 8 VEH
 SG_ EPBR_12VFilt : 37|12@1+ (0.00544368,0) [0|0] "V"  X
 SG_ EPBR_csmFaultReason : 21|5@1+ (1,0) [0|0] ""  X
 SG_ EPBR_disconnected : 10|1@1+ (1,0) [0|0] ""  X
 SG_ EPBR_epbmCDPQualified : 49|2@1+ (1,0) [0|0] ""  X
 SG_ EPBR_esmCaliperRequest : 18|3@1+ (1,0) [0|0] ""  X
 SG_ EPBR_esmOperationTrigger : 26|5@1+ (1,0) [0|0] ""  X
 SG_ EPBR_internalCDPRequest : 51|1@1+ (1,0) [0|0] ""  X
 SG_ EPBR_internalStatusChecksum : 56|8@1+ (1,0) [0|0] ""  X
 SG_ EPBR_internalStatusCounter : 52|4@1+ (1,0) [0|0] ""  X
 SG_ EPBR_localServiceModeActive : 36|1@1+ (1,0) [0|0] ""  X
 SG_ EPBR_lockoutUnlockCount : 11|7@1+ (1,0) [0|0] ""  X
 SG_ EPBR_summonFaultReason : 31|5@1+ (1,0) [0|0] ""  X
 SG_ EPBR_summonState : 7|3@1+ (1,0) [0|0] ""  X
 SG_ EPBR_unitFaultStatus : 5|2@1+ (1,0) [0|0] ""  X
 SG_ EPBR_unitStatus : 0|5@1+ (1,0) [0|0] ""  X

BO_ 744 EPBR_status: 8 VEH
 SG_ EPBR_blockDrive : 51|1@1+ (1,0) [0|0] ""  X
 SG_ EPBR_bothDisconnected : 50|1@1+ (1,0) [0|0] ""  X
 SG_ EPBR_brakeDiscWipeRequest : 30|2@1+ (1,0) [0|0] ""  X
 SG_ EPBR_brakeHWConfigMismatch : 19|1@1+ (1,0) [0|0] ""  X
 SG_ EPBR_brakeLight : 18|1@1+ (1,0) [0|0] ""  X
 SG_ EPBR_cdpRequest : 27|1@1+ (1,0) [0|0] ""  X
 SG_ EPBR_espPowerRequest : 46|1@1+ (1,0) [0|0] ""  X
 SG_ EPBR_hornRequest : 48|1@1+ (1,0) [0|0] ""  X
 SG_ EPBR_okToPark : 47|1@1+ (1,0) [0|0] ""  X
 SG_ EPBR_requestUserConfirmation : 21|1@1+ (1,0) [0|0] ""  X
 SG_ EPBR_statusChecksum : 56|8@1+ (1,0) [0|0] ""  X
 SG_ EPBR_statusCounter : 52|4@1+ (1,0) [0|0] ""  X
 SG_ EPBR_summonEnabled : 17|1@1+ (1,0) [0|0] ""  X
 SG_ EPBR_systemStatus : 0|4@1+ (1,0) [0|0] ""  X
 SG_ EPBR_telltale : 16|1@1+ (1,0) [0|0] ""  X
 SG_ EPBR_uiButtonAvailable : 20|1@1+ (1,0) [0|0] ""  X
 SG_ EPBR_updateMode : 24|1@1+ (1,0) [0|0] ""  X
 SG_ EPBR_winchModeActive : 23|1@1+ (1,0) [0|0] ""  X
 SG_ EPBR_winchModeAvailable : 49|1@1+ (1,0) [0|0] ""  X
 SG_ EPBR_winchModeTimer : 32|12@1+ (1,0) [0|0] ""  X

BO_ 981 ESP_alertMatrix: 8 CH
 SG_ ESP_matrixIndex M : 0|4@1+ (1,0) [0|0] ""  X
 SG_ ESP_a001_ecuGenericFault m0 : 4|1@1+ (1,0) [0|0] ""  X
 SG_ ESP_a002_valvesGenericFault m0 : 5|1@1+ (1,0) [0|0] ""  X
 SG_ ESP_a003_outletValvesFault m0 : 6|1@1+ (1,0) [0|0] ""  X
 SG_ ESP_a004_inletValvesFault m0 : 7|1@1+ (1,0) [0|0] ""  X
 SG_ ESP_a005_HSVValvesFault m0 : 8|1@1+ (1,0) [0|0] ""  X
 SG_ ESP_a006_USVValvesFault m0 : 9|1@1+ (1,0) [0|0] ""  X
 SG_ ESP_a007_pumpMotorFault m0 : 10|1@1+ (1,0) [0|0] ""  X
 SG_ ESP_a008_pumpMotor12VsupplyLow m0 : 11|1@1+ (1,0) [0|0] ""  X
 SG_ ESP_a009_12VHardUndervoltage m0 : 12|1@1+ (1,0) [0|0] ""  X
 SG_ ESP_a010_12VUndervoltage m0 : 13|1@1+ (1,0) [0|0] ""  X
 SG_ ESP_a011_12VSystemUndervoltage m0 : 14|1@1+ (1,0) [0|0] ""  X
 SG_ ESP_a012_netUndervoltage m0 : 15|1@1+ (1,0) [0|0] ""  X
 SG_ ESP_a013_valveRelayUndervoltage m0 : 16|1@1+ (1,0) [0|0] ""  X
 SG_ ESP_a014_WSSSupplyUndervoltage m0 : 17|1@1+ (1,0) [0|0] ""  X
 SG_ ESP_a015_12VSupplyOvervoltage m0 : 18|1@1+ (1,0) [0|0] ""  X
 SG_ ESP_a016_12VSystemOvervoltage m0 : 19|1@1+ (1,0) [0|0] ""  X
 SG_ ESP_a017_netOvervoltage m0 : 20|1@1+ (1,0) [0|0] ""  X
 SG_ ESP_a018_WSSSignFrontAxle m0 : 21|1@1+ (1,0) [0|0] ""  X
 SG_ ESP_a019_WSSSignRearAxle m0 : 22|1@1+ (1,0) [0|0] ""  X
 SG_ ESP_a020_WSSGenericTempFault m0 : 23|1@1+ (1,0) [0|0] ""  X
 SG_ ESP_a021_WSSGeneralVDiffFault m0 : 24|1@1+ (1,0) [0|0] ""  X
 SG_ ESP_a022_WSSDirectionFault m0 : 25|1@1+ (1,0) [0|0] ""  X
 SG_ ESP_a023_WSSSeveralSuspected m0 : 26|1@1+ (1,0) [0|0] ""  X
 SG_ ESP_a024_WSSReverseCurrent m0 : 27|1@1+ (1,0) [0|0] ""  X
 SG_ ESP_a025_FrLWSSOpenOrShortToGnd m0 : 28|1@1+ (1,0) [0|0] ""  X
 SG_ ESP_a026_FrLWSSShortTo12V m0 : 29|1@1+ (1,0) [0|0] ""  X
 SG_ ESP_a027_FrLWSSLineInterruption m0 : 30|1@1+ (1,0) [0|0] ""  X
 SG_ ESP_a028_FrLWSSMaxSpeedExceeded m0 : 31|1@1+ (1,0) [0|0] ""  X
 SG_ ESP_a029_FrLWSSTooManyPulses m0 : 32|1@1+ (1,0) [0|0] ""  X
 SG_ ESP_a030_FrLWSSLostSignal m0 : 33|1@1+ (1,0) [0|0] ""  X
 SG_ ESP_a031_FrLWSSNoPulsesDetected m0 : 34|1@1+ (1,0) [0|0] ""  X
 SG_ ESP_a032_FrLWSSWrongSensorType m0 : 35|1@1+ (1,0) [0|0] ""  X
 SG_ ESP_a033_FrLWSSSignalNoise m0 : 36|1@1+ (1,0) [0|0] ""  X
 SG_ ESP_a034_FrLWSSVDiffFault m0 : 37|1@1+ (1,0) [0|0] ""  X
 SG_ ESP_a035_FrLWSSDirectionFault m0 : 38|1@1+ (1,0) [0|0] ""  X
 SG_ ESP_a036_FrLWSSLargeAirGap m0 : 39|1@1+ (1,0) [0|0] ""  X
 SG_ ESP_a037_FrLWSSSupplyShortToGnd m0 : 40|1@1+ (1,0) [0|0] ""  X
 SG_ ESP_a038_FrLWSSGeneralFault m0 : 41|1@1+ (1,0) [0|0] ""  X
 SG_ ESP_a039_FrRWSSOpenOrShortToGnd m0 : 42|1@1+ (1,0) [0|0] ""  X
 SG_ ESP_a040_FrRWSSShortTo12V m0 : 43|1@1+ (1,0) [0|0] ""  X
 SG_ ESP_a041_FrRWSSLineInterruption m0 : 44|1@1+ (1,0) [0|0] ""  X
 SG_ ESP_a042_FrRWSSMaxSpeedExceeded m0 : 45|1@1+ (1,0) [0|0] ""  X
 SG_ ESP_a043_FrRWSSTooManyPulses m0 : 46|1@1+ (1,0) [0|0] ""  X
 SG_ ESP_a044_FrRWSSLostSignal m0 : 47|1@1+ (1,0) [0|0] ""  X
 SG_ ESP_a045_FrRWSSNoPulsesDetected m0 : 48|1@1+ (1,0) [0|0] ""  X
 SG_ ESP_a046_FrRWSSWrongSensorType m0 : 49|1@1+ (1,0) [0|0] ""  X
 SG_ ESP_a047_FrRWSSSignalNoise m0 : 50|1@1+ (1,0) [0|0] ""  X
 SG_ ESP_a048_FrRWSSVDiffFault m0 : 51|1@1+ (1,0) [0|0] ""  X
 SG_ ESP_a049_FrRWSSDirectionFault m0 : 52|1@1+ (1,0) [0|0] ""  X
 SG_ ESP_a050_FrRWSSLargeAirGap m0 : 53|1@1+ (1,0) [0|0] ""  X
 SG_ ESP_a051_FrRWSSSupplyShortToGnd m0 : 54|1@1+ (1,0) [0|0] ""  X
 SG_ ESP_a052_FrRWSSGeneralFault m0 : 55|1@1+ (1,0) [0|0] ""  X
 SG_ ESP_a053_ReLWSSOpenOrShortToGnd m0 : 56|1@1+ (1,0) [0|0] ""  X
 SG_ ESP_a054_ReLWSSShortTo12V m0 : 57|1@1+ (1,0) [0|0] ""  X
 SG_ ESP_a055_ReLWSSLineInterruption m0 : 58|1@1+ (1,0) [0|0] ""  X
 SG_ ESP_a056_ReLWSSMaxSpeedExceeded m0 : 59|1@1+ (1,0) [0|0] ""  X
 SG_ ESP_a057_ReLWSSTooManyPulses m0 : 60|1@1+ (1,0) [0|0] ""  X
 SG_ ESP_a058_ReLWSSLostSignal m0 : 61|1@1+ (1,0) [0|0] ""  X
 SG_ ESP_a059_ReLWSSNoPulsesDetected m0 : 62|1@1+ (1,0) [0|0] ""  X
 SG_ ESP_a060_ReLWSSWrongSensorType m0 : 63|1@1+ (1,0) [0|0] ""  X
 SG_ ESP_a061_ReLWSSSignalNoise m1 : 4|1@1+ (1,0) [0|0] ""  X
 SG_ ESP_a062_ReLWSSVDiffFault m1 : 5|1@1+ (1,0) [0|0] ""  X
 SG_ ESP_a063_ReLWSSDirectionFault m1 : 6|1@1+ (1,0) [0|0] ""  X
 SG_ ESP_a064_ReLWSSLargeAirGap m1 : 7|1@1+ (1,0) [0|0] ""  X
 SG_ ESP_a065_ReLWSSSupplyShortToGnd m1 : 8|1@1+ (1,0) [0|0] ""  X
 SG_ ESP_a066_ReLWSSGeneralFault m1 : 9|1@1+ (1,0) [0|0] ""  X
 SG_ ESP_a067_ReRWSSOpenOrShortToGnd m1 : 10|1@1+ (1,0) [0|0] ""  X
 SG_ ESP_a068_ReRWSSShortTo12V m1 : 11|1@1+ (1,0) [0|0] ""  X
 SG_ ESP_a069_ReRWSSLineInterruption m1 : 12|1@1+ (1,0) [0|0] ""  X
 SG_ ESP_a070_ReRWSSMaxSpeedExceeded m1 : 13|1@1+ (1,0) [0|0] ""  X
 SG_ ESP_a071_ReRWSSTooManyPulses m1 : 14|1@1+ (1,0) [0|0] ""  X
 SG_ ESP_a072_ReRWSSLostSignal m1 : 15|1@1+ (1,0) [0|0] ""  X
 SG_ ESP_a073_ReRWSSNoPulsesDetected m1 : 16|1@1+ (1,0) [0|0] ""  X
 SG_ ESP_a074_ReRWSSWrongSensorType m1 : 17|1@1+ (1,0) [0|0] ""  X
 SG_ ESP_a075_ReRWSSSignalNoise m1 : 18|1@1+ (1,0) [0|0] ""  X
 SG_ ESP_a076_ReRWSSVDiffFault m1 : 19|1@1+ (1,0) [0|0] ""  X
 SG_ ESP_a077_ReRWSSDirectionFault m1 : 20|1@1+ (1,0) [0|0] ""  X
 SG_ ESP_a078_ReRWSSLargeAirGap m1 : 21|1@1+ (1,0) [0|0] ""  X
 SG_ ESP_a079_ReRWSSSupplyShortToGnd m1 : 22|1@1+ (1,0) [0|0] ""  X
 SG_ ESP_a080_ReRWSSGeneralFault m1 : 23|1@1+ (1,0) [0|0] ""  X
 SG_ ESP_a081_PressureSensorShort m1 : 24|1@1+ (1,0) [0|0] ""  X
 SG_ ESP_a082_PMCSensorOffsVEHigh m1 : 25|1@1+ (1,0) [0|0] ""  X
 SG_ ESP_a083_PMCSensorFault m1 : 26|1@1+ (1,0) [0|0] ""  X
 SG_ ESP_a084_BrakeFluidReservoirLow m1 : 27|1@1+ (1,0) [0|0] ""  X
 SG_ ESP_a085_BrakeSwitchStuckHigh m1 : 28|1@1+ (1,0) [0|0] ""  X
 SG_ ESP_a086_BrakeSwitchImplausible1 m1 : 29|1@1+ (1,0) [0|0] ""  X
 SG_ ESP_a087_BrakeSwitchImplausible3 m1 : 30|1@1+ (1,0) [0|0] ""  X
 SG_ ESP_a088_absContinuousControl m1 : 31|1@1+ (1,0) [0|0] ""  X
 SG_ ESP_a089_absNoPressureIncrease m1 : 32|1@1+ (1,0) [0|0] ""  X
 SG_ ESP_a090_vdcContinuousControl m1 : 33|1@1+ (1,0) [0|0] ""  X
 SG_ ESP_a091_CANUndervoltage m1 : 34|1@1+ (1,0) [0|0] ""  X
 SG_ ESP_a092_CANOvervoltage m1 : 35|1@1+ (1,0) [0|0] ""  X
 SG_ ESP_a093_partyBusOff m1 : 36|1@1+ (1,0) [0|0] ""  X
 SG_ ESP_a094_partyBusPassive m1 : 37|1@1+ (1,0) [0|0] ""  X
 SG_ ESP_a095_CHOff m1 : 38|1@1+ (1,0) [0|0] ""  X
 SG_ ESP_a096_CHPassive m1 : 39|1@1+ (1,0) [0|0] ""  X
 SG_ ESP_a097_tcsRefSpeedNotInit m1 : 40|1@1+ (1,0) [0|0] ""  X
 SG_ ESP_a098_vdcRefSpeedNotInit m1 : 41|1@1+ (1,0) [0|0] ""  X
 SG_ ESP_a099_brakeTempModelOverheat m1 : 42|1@1+ (1,0) [0|0] ""  X
 SG_ ESP_a100_brakeTempModelDisabled m1 : 43|1@1+ (1,0) [0|0] ""  X
 SG_ ESP_a101_ebdFault m1 : 44|1@1+ (1,0) [0|0] ""  X
 SG_ ESP_a102_absFault m1 : 45|1@1+ (1,0) [0|0] ""  X
 SG_ ESP_a103_stabilityControlFault m1 : 46|1@1+ (1,0) [0|0] ""  X
 SG_ ESP_a104_hbcEnabled m1 : 47|1@1+ (1,0) [0|0] ""  X
 SG_ ESP_a105_ebrFault m1 : 48|1@1+ (1,0) [0|0] ""  X
 SG_ ESP_a106_vdcActuatorFault m1 : 49|1@1+ (1,0) [0|0] ""  X
 SG_ ESP_a107_reserved107 m1 : 50|1@1+ (1,0) [0|0] ""  X
 SG_ ESP_a108_reserved108 m1 : 51|1@1+ (1,0) [0|0] ""  X
 SG_ ESP_a109_reserved109 m1 : 52|1@1+ (1,0) [0|0] ""  X
 SG_ ESP_a110_rollerBenchActive m1 : 53|1@1+ (1,0) [0|0] ""  X
 SG_ ESP_a111_absActive m1 : 54|1@1+ (1,0) [0|0] ""  X
 SG_ ESP_a112_espActive m1 : 55|1@1+ (1,0) [0|0] ""  X
 SG_ ESP_a113_btcActive m1 : 56|1@1+ (1,0) [0|0] ""  X
 SG_ ESP_a114_tvdcActive m1 : 57|1@1+ (1,0) [0|0] ""  X
 SG_ ESP_a115_ebdActive m1 : 58|1@1+ (1,0) [0|0] ""  X
 SG_ ESP_a116_tsmActive m1 : 59|1@1+ (1,0) [0|0] ""  X
 SG_ ESP_a117_hbaActive m1 : 60|1@1+ (1,0) [0|0] ""  X
 SG_ ESP_a118_hfcActive m1 : 61|1@1+ (1,0) [0|0] ""  X
 SG_ ESP_a119_hbbActive m1 : 62|1@1+ (1,0) [0|0] ""  X
 SG_ ESP_a120_rmiActive m1 : 63|1@1+ (1,0) [0|0] ""  X
 SG_ ESP_a121_regenTcActive m2 : 4|1@1+ (1,0) [0|0] ""  X
 SG_ ESP_a122_bdwActive m2 : 5|1@1+ (1,0) [0|0] ""  X
 SG_ ESP_a123_ebrActive m2 : 6|1@1+ (1,0) [0|0] ""  X
 SG_ ESP_a124_ebrSkidActive m2 : 7|1@1+ (1,0) [0|0] ""  X
 SG_ ESP_a125_reserved125 m2 : 8|1@1+ (1,0) [0|0] ""  X
 SG_ ESP_a126_reserved126 m2 : 9|1@1+ (1,0) [0|0] ""  X
 SG_ ESP_a127_reserved127 m2 : 10|1@1+ (1,0) [0|0] ""  X
 SG_ ESP_a128_reserved128 m2 : 11|1@1+ (1,0) [0|0] ""  X
 SG_ ESP_a129_reserved129 m2 : 12|1@1+ (1,0) [0|0] ""  X
 SG_ ESP_a130_EPAS3PsysStatusTimeout m2 : 13|1@1+ (1,0) [0|0] ""  X
 SG_ ESP_a131_EPAS3PsysStatusDLC m2 : 14|1@1+ (1,0) [0|0] ""  X
 SG_ ESP_a132_EPAS3PsysStatusChecksum m2 : 15|1@1+ (1,0) [0|0] ""  X
 SG_ ESP_a133_EPAS3PsysStatusCounter m2 : 16|1@1+ (1,0) [0|0] ""  X
 SG_ ESP_a134_steeringAngleInvalid m2 : 17|1@1+ (1,0) [0|0] ""  X
 SG_ ESP_a135_steeringAngleNoCenter m2 : 18|1@1+ (1,0) [0|0] ""  X
 SG_ ESP_a136_steeringAngleFrozen m2 : 19|1@1+ (1,0) [0|0] ""  X
 SG_ ESP_a137_steeringOffsetTooLarge m2 : 20|1@1+ (1,0) [0|0] ""  X
 SG_ ESP_a138_steeringAngleImplaus m2 : 21|1@1+ (1,0) [0|0] ""  X
 SG_ ESP_a139_steeringAngleWrongSign m2 : 22|1@1+ (1,0) [0|0] ""  X
 SG_ ESP_a140_RCMInertial1Timeout m2 : 23|1@1+ (1,0) [0|0] ""  X
 SG_ ESP_a141_RCMInertial1DLC m2 : 24|1@1+ (1,0) [0|0] ""  X
 SG_ ESP_a142_RCMInertial1Checksum m2 : 25|1@1+ (1,0) [0|0] ""  X
 SG_ ESP_a143_RCMInertial1Counter m2 : 26|1@1+ (1,0) [0|0] ""  X
 SG_ ESP_a144_yawMaxLatency m2 : 27|1@1+ (1,0) [0|0] ""  X
 SG_ ESP_a145_yawInitFault m2 : 28|1@1+ (1,0) [0|0] ""  X
 SG_ ESP_a146_yawInvalidValue m2 : 29|1@1+ (1,0) [0|0] ""  X
 SG_ ESP_a147_yawSensorNotAvailable m2 : 30|1@1+ (1,0) [0|0] ""  X
 SG_ ESP_a148_yawSignalFault m2 : 31|1@1+ (1,0) [0|0] ""  X
 SG_ ESP_a149_yawInvalidSign m2 : 32|1@1+ (1,0) [0|0] ""  X
 SG_ ESP_a150_yawImplausible m2 : 33|1@1+ (1,0) [0|0] ""  X
 SG_ ESP_a151_RCMInertial2Timeout m2 : 34|1@1+ (1,0) [0|0] ""  X
 SG_ ESP_a152_RCMInertial2DLC m2 : 35|1@1+ (1,0) [0|0] ""  X
 SG_ ESP_a153_RCMInertial2Checksum m2 : 36|1@1+ (1,0) [0|0] ""  X
 SG_ ESP_a154_RCMInertial2Counter m2 : 37|1@1+ (1,0) [0|0] ""  X
 SG_ ESP_a155_ayMaxLatency m2 : 38|1@1+ (1,0) [0|0] ""  X
 SG_ ESP_a156_ayInitFault m2 : 39|1@1+ (1,0) [0|0] ""  X
 SG_ ESP_a157_ayInvalidValue m2 : 40|1@1+ (1,0) [0|0] ""  X
 SG_ ESP_a158_aySensorNotAvailable m2 : 41|1@1+ (1,0) [0|0] ""  X
 SG_ ESP_a159_aySignalFault m2 : 42|1@1+ (1,0) [0|0] ""  X
 SG_ ESP_a160_ayRangeExceeded m2 : 43|1@1+ (1,0) [0|0] ""  X
 SG_ ESP_a161_ayOffsetExceeded m2 : 44|1@1+ (1,0) [0|0] ""  X
 SG_ ESP_a162_ayImplausible m2 : 45|1@1+ (1,0) [0|0] ""  X
 SG_ ESP_a163_axMaxLatency m2 : 46|1@1+ (1,0) [0|0] ""  X
 SG_ ESP_a164_axInitFault m2 : 47|1@1+ (1,0) [0|0] ""  X
 SG_ ESP_a165_axInvalidValue m2 : 48|1@1+ (1,0) [0|0] ""  X
 SG_ ESP_a166_axSensorNotAvailable m2 : 49|1@1+ (1,0) [0|0] ""  X
 SG_ ESP_a167_axSignalFault m2 : 50|1@1+ (1,0) [0|0] ""  X
 SG_ ESP_a168_axRangeExceeded m2 : 51|1@1+ (1,0) [0|0] ""  X
 SG_ ESP_a169_axOffsetExceeded m2 : 52|1@1+ (1,0) [0|0] ""  X
 SG_ ESP_a170_axSignalFrozen m2 : 53|1@1+ (1,0) [0|0] ""  X
 SG_ ESP_a171_axImplausible m2 : 54|1@1+ (1,0) [0|0] ""  X
 SG_ ESP_a172_IBSTparty1Timeout m2 : 55|1@1+ (1,0) [0|0] ""  X
 SG_ ESP_a173_IBSTparty1DLC m2 : 56|1@1+ (1,0) [0|0] ""  X
 SG_ ESP_a174_IBSTparty1Checksum m2 : 57|1@1+ (1,0) [0|0] ""  X
 SG_ ESP_a175_IBSTparty1Counter m2 : 58|1@1+ (1,0) [0|0] ""  X
 SG_ ESP_a176_IBSTEBRNotAvailable m2 : 59|1@1+ (1,0) [0|0] ""  X
 SG_ ESP_a177_IBSTOutputRodDrvInvalid m2 : 60|1@1+ (1,0) [0|0] ""  X
 SG_ ESP_a178_IBSTOutputRodActInvalid m2 : 61|1@1+ (1,0) [0|0] ""  X
 SG_ ESP_a179_IBSTparty2Timeout m2 : 62|1@1+ (1,0) [0|0] ""  X
 SG_ ESP_a180_IBSTparty2Checksum m2 : 63|1@1+ (1,0) [0|0] ""  X
 SG_ ESP_a181_IBSTparty2DLC m3 : 4|1@1+ (1,0) [0|0] ""  X
 SG_ ESP_a182_IBSTparty2Counter m3 : 5|1@1+ (1,0) [0|0] ""  X
 SG_ ESP_a183_IBSTStatusOff m3 : 6|1@1+ (1,0) [0|0] ""  X
 SG_ ESP_a184_IBSTpRunoutInvalid m3 : 7|1@1+ (1,0) [0|0] ""  X
 SG_ ESP_a185_IBSTFeedforwardBackup m3 : 8|1@1+ (1,0) [0|0] ""  X
 SG_ ESP_a186_IBSTBrakeAppliedInvalid m3 : 9|1@1+ (1,0) [0|0] ""  X
 SG_ ESP_a187_DIbtcRequestTimeout m3 : 10|1@1+ (1,0) [0|0] ""  X
 SG_ ESP_a188_DIbtcRequestDLC m3 : 11|1@1+ (1,0) [0|0] ""  X
 SG_ ESP_a189_DIbtcRequestChecksum m3 : 12|1@1+ (1,0) [0|0] ""  X
 SG_ ESP_a190_DIbtcRequestCounter m3 : 13|1@1+ (1,0) [0|0] ""  X
 SG_ ESP_a191_DIchassiControlTimeout m3 : 14|1@1+ (1,0) [0|0] ""  X
 SG_ ESP_a192_DIchassiControlDLC m3 : 15|1@1+ (1,0) [0|0] ""  X
 SG_ ESP_a193_DIchassiControlChecksum m3 : 16|1@1+ (1,0) [0|0] ""  X
 SG_ ESP_a194_DIchassiControlCounter m3 : 17|1@1+ (1,0) [0|0] ""  X
 SG_ ESP_a195_ptcStateInvalid m3 : 18|1@1+ (1,0) [0|0] ""  X
 SG_ ESP_a196_DIsystemStatusTimeout m3 : 19|1@1+ (1,0) [0|0] ""  X
 SG_ ESP_a197_DIsystemStatusDLC m3 : 20|1@1+ (1,0) [0|0] ""  X
 SG_ ESP_a198_DIsystemStatusChecksum m3 : 21|1@1+ (1,0) [0|0] ""  X
 SG_ ESP_a199_DIsystemStatusCounter m3 : 22|1@1+ (1,0) [0|0] ""  X
 SG_ ESP_a200_reverseGearStuckHigh m3 : 23|1@1+ (1,0) [0|0] ""  X
 SG_ ESP_a201_reverseGearStuckLow m3 : 24|1@1+ (1,0) [0|0] ""  X
 SG_ ESP_a202_accelPedalInvalid m3 : 25|1@1+ (1,0) [0|0] ""  X
 SG_ ESP_a203_DItorqueTimeout m3 : 26|1@1+ (1,0) [0|0] ""  X
 SG_ ESP_a204_DItorqueDLC m3 : 27|1@1+ (1,0) [0|0] ""  X
 SG_ ESP_a205_DItorqueChecksum m3 : 28|1@1+ (1,0) [0|0] ""  X
 SG_ ESP_a206_DItorqueCounter m3 : 29|1@1+ (1,0) [0|0] ""  X
 SG_ ESP_a207_DITorqueCommandInvalid m3 : 30|1@1+ (1,0) [0|0] ""  X
 SG_ ESP_a208_DIRPMInvalid m3 : 31|1@1+ (1,0) [0|0] ""  X
 SG_ ESP_a209_DITorqueActualInvalid m3 : 32|1@1+ (1,0) [0|0] ""  X
 SG_ ESP_a210_DIStorqueTimeout m3 : 33|1@1+ (1,0) [0|0] ""  X
 SG_ ESP_a211_DIStorqueDLC m3 : 34|1@1+ (1,0) [0|0] ""  X
 SG_ ESP_a212_DIStorqueChecksum m3 : 35|1@1+ (1,0) [0|0] ""  X
 SG_ ESP_a213_DIStorqueCounter m3 : 36|1@1+ (1,0) [0|0] ""  X
 SG_ ESP_a214_DISTorqueCommandInvalid m3 : 37|1@1+ (1,0) [0|0] ""  X
 SG_ ESP_a215_DISRPMInvalid m3 : 38|1@1+ (1,0) [0|0] ""  X
 SG_ ESP_a216_DISTorqueActualInvalid m3 : 39|1@1+ (1,0) [0|0] ""  X
 SG_ ESP_a217_DIvdcLeftTimeout m3 : 40|1@1+ (1,0) [0|0] ""  X
 SG_ ESP_a218_DIvdcLeftDLC m3 : 41|1@1+ (1,0) [0|0] ""  X
 SG_ ESP_a219_DIvdcLeftChecksum m3 : 42|1@1+ (1,0) [0|0] ""  X
 SG_ ESP_a220_DIvdcLeftCounter m3 : 43|1@1+ (1,0) [0|0] ""  X
 SG_ ESP_a221_DIvdcRightTimeout m3 : 44|1@1+ (1,0) [0|0] ""  X
 SG_ ESP_a222_DIvdcRightDLC m3 : 45|1@1+ (1,0) [0|0] ""  X
 SG_ ESP_a223_DIvdcRightChecksum m3 : 46|1@1+ (1,0) [0|0] ""  X
 SG_ ESP_a224_DIvdcRightCounter m3 : 47|1@1+ (1,0) [0|0] ""  X
 SG_ ESP_a225_configMismatch m3 : 48|1@1+ (1,0) [0|0] ""  X
 SG_ ESP_a226_bdwRequestInvalid m3 : 49|1@1+ (1,0) [0|0] ""  X
 SG_ ESP_a227_bdwRequestActiveInvalid m3 : 50|1@1+ (1,0) [0|0] ""  X
 SG_ ESP_a228_GTWvinTimeout m3 : 51|1@1+ (1,0) [0|0] ""  X
 SG_ ESP_a229_GTWvinDLC m3 : 52|1@1+ (1,0) [0|0] ""  X
 SG_ ESP_a230_vinNotLearned m3 : 53|1@1+ (1,0) [0|0] ""  X
 SG_ ESP_a231_storedVINMismatch m3 : 54|1@1+ (1,0) [0|0] ""  X
 SG_ ESP_a232_PMstate2Timeout m3 : 55|1@1+ (1,0) [0|0] ""  X
 SG_ ESP_a233_PMstate2Checksum m3 : 56|1@1+ (1,0) [0|0] ""  X
 SG_ ESP_a234_PMstate2DLC m3 : 57|1@1+ (1,0) [0|0] ""  X
 SG_ ESP_a235_PMstate2Counter m3 : 58|1@1+ (1,0) [0|0] ""  X
 SG_ ESP_a236_ebrCommandStateInvalid m3 : 59|1@1+ (1,0) [0|0] ""  X
 SG_ ESP_a237_vdcCommandStateInvalid m3 : 60|1@1+ (1,0) [0|0] ""  X
 SG_ ESP_a238_UIodoTimeout m3 : 61|1@1+ (1,0) [0|0] ""  X
 SG_ ESP_a239_UIodoDLC m3 : 62|1@1+ (1,0) [0|0] ""  X
 SG_ ESP_a240_LVPowerStateTimeout m3 : 63|1@1+ (1,0) [0|0] ""  X
 SG_ ESP_a241_LVPowerStateChecksum m4 : 4|1@1+ (1,0) [0|0] ""  X
 SG_ ESP_a242_LVPowerStateDLC m4 : 5|1@1+ (1,0) [0|0] ""  X
 SG_ ESP_a243_LVPowerStateCounter m4 : 6|1@1+ (1,0) [0|0] ""  X
 SG_ ESP_a244_LVOffStateInvalid m4 : 7|1@1+ (1,0) [0|0] ""  X
 SG_ ESP_a245_LVGoingDownStateInvalid m4 : 8|1@1+ (1,0) [0|0] ""  X
 SG_ ESP_a246_VCFRONTsensorTimeout m4 : 9|1@1+ (1,0) [0|0] ""  X
 SG_ ESP_a247_VCFRONTsensorDLC m4 : 10|1@1+ (1,0) [0|0] ""  X
 SG_ ESP_a248_vdcBrkeTrqTarFrLInvalid m4 : 11|1@1+ (1,0) [0|0] ""  X
 SG_ ESP_a249_vdcBrkeTrqTarFrRInvalid m4 : 12|1@1+ (1,0) [0|0] ""  X
 SG_ ESP_a250_vdcBrkeTrqTarReLInvalid m4 : 13|1@1+ (1,0) [0|0] ""  X
 SG_ ESP_a251_vdcBrkeTrqTarReRInvalid m4 : 14|1@1+ (1,0) [0|0] ""  X
 SG_ ESP_a252_vdcWhlSlipLimFrLInvalid m4 : 15|1@1+ (1,0) [0|0] ""  X
 SG_ ESP_a253_vdcWhlSlipLimFrRInvalid m4 : 16|1@1+ (1,0) [0|0] ""  X
 SG_ ESP_a254_vdcWhlSlipLimReLInvalid m4 : 17|1@1+ (1,0) [0|0] ""  X
 SG_ ESP_a255_vdcWhlSlipLimReRInvalid m4 : 18|1@1+ (1,0) [0|0] ""  X
 SG_ ESP_a256_epbmStatusTimeout m4 : 19|1@1+ (1,0) [0|0] ""  X
 SG_ ESP_a257_epbmStatusChecksum m4 : 20|1@1+ (1,0) [0|0] ""  X
 SG_ ESP_a258_epbmStatusDLC m4 : 21|1@1+ (1,0) [0|0] ""  X
 SG_ ESP_a259_epbmStatusCounter m4 : 22|1@1+ (1,0) [0|0] ""  X
 SG_ ESP_a260_epblStatusTimeout m4 : 23|1@1+ (1,0) [0|0] ""  X
 SG_ ESP_a261_epblStatusChecksum m4 : 24|1@1+ (1,0) [0|0] ""  X
 SG_ ESP_a262_epblStatusDLC m4 : 25|1@1+ (1,0) [0|0] ""  X
 SG_ ESP_a263_epblStatusCounter m4 : 26|1@1+ (1,0) [0|0] ""  X

BO_ 808 ESP_info: 8 VEH
 SG_ ESP_infoIndex M : 0|8@1+ (1,0) [0|0] ""  X
 SG_ ESP_infoBuildType m10 : 8|8@1+ (1,0) [0|0] ""  X
 SG_ ESP_infoComponentID m10 : 48|16@1+ (1,0) [0|0] ""  X
 SG_ ESP_infoPcbaID m11 : 16|8@1+ (1,0) [0|0] ""  X
 SG_ ESP_infoAssemblyID m11 : 24|8@1+ (1,0) [0|0] ""  X
 SG_ ESP_infoUsageID m11 : 32|16@1+ (1,0) [0|0] ""  X
 SG_ ESP_infoApplicationCRC m13 : 30|32@0+ (1,0) [0|0] ""  X
 SG_ ESP_infoVehicleVariant m16 : 16|8@1+ (1,0) [0|0] ""  X
 SG_ ESP_infoBootUdsProtoVersion m20 : 8|8@1+ (1,0) [0|0] ""  X
 SG_ ESP_infoBootloaderCRC m20 : 32|32@1+ (1,0) [0|0] ""  X
 SG_ ESP_infoVariantCRC m22 : 30|32@0+ (1,0) [0|0] ""  X

BO_ 325 ESP_status: 8 CH
 SG_ ESP_absBrakeEvent2 : 22|2@1+ (1,0) [0|0] ""  X
 SG_ ESP_absFaultLamp : 17|1@1+ (1,0) [0|0] ""  X
 SG_ ESP_brakeApply : 31|1@1+ (1,0) [0|0] ""  X
 SG_ ESP_brakeDiscWipingActive : 28|1@1+ (1,0) [0|0] ""  X
 SG_ ESP_brakeLamp : 21|1@1+ (1,0) [0|0] ""  X
 SG_ ESP_brakeTorqueTarget : 51|13@1+ (2,0) [0|0] "Nm"  X
 SG_ ESP_btcTargetState : 38|2@1+ (1,0) [0|0] ""  X
 SG_ ESP_cdpStatus : 34|2@1+ (1,0) [0|0] ""  X
 SG_ ESP_driverBrakeApply : 29|2@1+ (1,0) [0|0] ""  X
 SG_ ESP_ebdFaultLamp : 16|1@1+ (1,0) [0|0] ""  X
 SG_ ESP_ebrStandstillSkid : 48|1@1+ (1,0) [0|0] ""  X
 SG_ ESP_ebrStatus : 49|2@1+ (1,0) [0|0] ""  X
 SG_ ESP_espFaultLamp : 18|1@1+ (1,0) [0|0] ""  X
 SG_ ESP_espLampFlash : 20|1@1+ (1,0) [0|0] ""  X
 SG_ ESP_espModeActive : 12|2@1+ (1,0) [0|0] ""  X
 SG_ ESP_hydraulicBoostEnabled : 19|1@1+ (1,0) [0|0] ""  X
 SG_ ESP_lateralAccelQF : 25|1@1+ (1,0) [0|0] ""  X
 SG_ ESP_longitudinalAccelQF : 24|1@1+ (1,0) [0|0] ""  X
 SG_ ESP_ptcTargetState : 36|2@1+ (1,0) [0|0] ""  X
 SG_ ESP_stabilityControlSts2 : 14|2@1+ (1,0) [0|0] ""  X
 SG_ ESP_statusChecksum : 0|8@1+ (1,0) [0|0] ""  X
 SG_ ESP_statusCounter : 8|4@1+ (1,0) [0|0] ""  X
 SG_ ESP_steeringAngleQF : 27|1@1+ (1,0) [0|0] ""  X
 SG_ ESP_yawRateQF : 26|1@1+ (1,0) [0|0] ""  X

BO_ 341 ESP_wheelRotation: 8 CH
 SG_ ESP_wheelAngleFL : 0|8@1+ (1.40625,0) [0|358.59375] "deg"  X
 SG_ ESP_wheelAngleFR : 8|8@1+ (1.40625,0) [0|358.59375] "deg"  X
 SG_ ESP_wheelAngleRL : 16|8@1+ (1.40625,0) [0|358.59375] "deg"  X
 SG_ ESP_wheelAngleRR : 24|8@1+ (1.40625,0) [0|358.59375] "deg"  X
 SG_ ESP_wheelRotationRR : 32|2@1+ (1,0) [0|3] ""  Receiver
 SG_ ESP_wheelRotationRL : 34|2@1+ (1,0) [0|3] ""  Receiver
 SG_ ESP_wheelRotationFR : 36|2@1+ (1,0) [0|3] ""  Receiver
 SG_ ESP_wheelRotationFL : 38|2@1+ (1,0) [0|3] ""  Receiver
 SG_ ESP_wheelRotationQF : 40|1@1+ (1,0) [0|1] ""  Receiver
 SG_ ESP_standstillStatus : 41|1@1+ (1,0) [0|1] ""  Receiver
 SG_ ESP_vehicleSpeed : 42|10@1+ (0.5,0) [0|511] "kph"  Receiver
 SG_ ESP_wheelRotationCounter : 52|4@1+ (1,0) [0|15] ""  Receiver
 SG_ ESP_wheelRotationChecksum : 56|8@1+ (1,0) [0|255] ""  Receiver

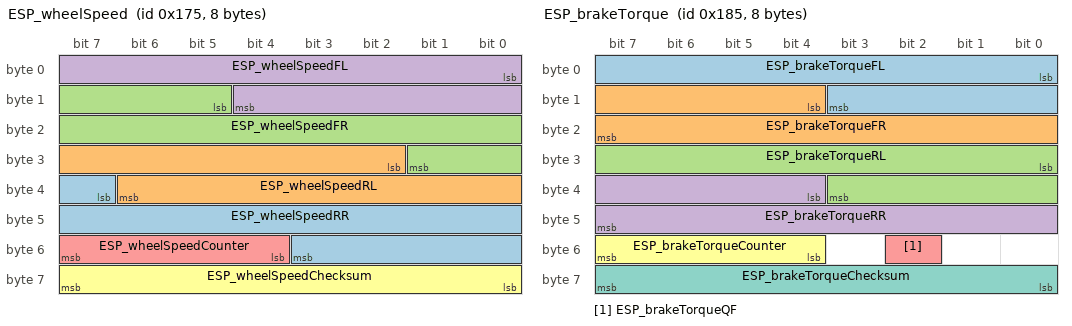
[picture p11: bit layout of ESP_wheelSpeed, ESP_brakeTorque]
BO_ 373 ESP_wheelSpeed: 8 CH
 SG_ ESP_wheelSpeedRR : 39|13@1+ (0.04,0) [0|327.64] "RPM"  X
 SG_ ESP_wheelSpeedRL : 26|13@1+ (0.04,0) [0|327.64] "RPM"  X
 SG_ ESP_wheelSpeedFR : 13|13@1+ (0.04,0) [0|327.64] "RPM"  X
 SG_ ESP_wheelSpeedFL : 0|13@1+ (0.04,0) [0|327.64] "RPM"  X
 SG_ ESP_wheelSpeedCounter : 52|4@1+ (1,0) [0|15] ""  Receiver
 SG_ ESP_wheelSpeedChecksum : 56|8@1+ (1,0) [0|255] ""  Receiver

BO_ 389 ESP_brakeTorque: 8 CH
 SG_ ESP_brakeTorqueFL : 0|12@1+ (2,0) [0|8190] "Nm"  Receiver
 SG_ ESP_brakeTorqueFR : 12|12@1+ (2,0) [0|8190] "Nm"  Receiver
 SG_ ESP_brakeTorqueRL : 24|12@1+ (2,0) [0|8190] "Nm"  Receiver
 SG_ ESP_brakeTorqueRR : 36|12@1+ (2,0) [0|8190] "Nm"  Receiver
 SG_ ESP_brakeTorqueQF : 50|1@1+ (1,0) [0|1] ""  Receiver
 SG_ ESP_brakeTorqueCounter : 52|4@1+ (1,0) [0|15] ""  Receiver
 SG_ ESP_brakeTorqueChecksum : 56|8@1+ (1,0) [0|255] ""  Receiver

BO_ 805 FC_alertMatrix1: 8 VEH
 SG_ FC_a001_scPostOutOfService : 0|1@1+ (1,0) [0|0] ""  X
 SG_ FC_a002_scPowerShared : 1|1@1+ (1,0) [0|0] ""  X

BO_ 831 FC_alertMatrix2: 8 VEH
 SG_ FC_a065_userData : 0|1@1+ (1,0) [0|0] ""  X

BO_ 895 FC_alertMatrix3: 8 VEH
 SG_ FC_a129_CA_flyback_HW_OC : 0|1@1+ (1,0) [0|0] ""  X
 SG_ FC_a130_CA_flyback_SW_OV : 1|1@1+ (1,0) [0|0] ""  X
 SG_ FC_a131_CA_flyback_HW_OV : 2|1@1+ (1,0) [0|0] ""  X
 SG_ FC_a132_CA_bmsMia : 3|1@1+ (1,0) [0|0] ""  X
 SG_ FC_a133_CA_evseMia : 4|1@1+ (1,0) [0|0] ""  X
 SG_ FC_a134_CA_vehTxBufOvf : 5|1@1+ (1,0) [0|0] ""  X
 SG_ FC_a135_CA_vehRxBufOvf : 6|1@1+ (1,0) [0|0] ""  X
 SG_ FC_a136_CA_evseTxBufOvf : 7|1@1+ (1,0) [0|0] ""  X
 SG_ FC_a137_CA_evseRxBufOvf : 8|1@1+ (1,0) [0|0] ""  X
 SG_ FC_a138_CA_hwProxTrip : 9|1@1+ (1,0) [0|0] ""  X
 SG_ FC_a139_CA_ss2NotLow : 10|1@1+ (1,0) [0|0] ""  X
 SG_ FC_a140_CA_bmsIncompatible : 11|1@1+ (1,0) [0|0] ""  X
 SG_ FC_a141_CA_vehConn_OT : 12|1@1+ (1,0) [0|0] ""  X
 SG_ FC_a142_CA_evseConn_OT : 13|1@1+ (1,0) [0|0] ""  X
 SG_ FC_a143_CA_pcb_OT : 14|1@1+ (1,0) [0|0] ""  X
 SG_ FC_a144_CA_flybackUnstable : 15|1@1+ (1,0) [0|0] ""  X
 SG_ FC_a145_CA_flybackDataStale : 16|1@1+ (1,0) [0|0] ""  X
 SG_ FC_a146_CA_flybackBusLoadHi : 17|1@1+ (1,0) [0|0] ""  X
 SG_ FC_a147_CA_vehConn_UT : 18|1@1+ (1,0) [0|0] ""  X
 SG_ FC_a148_CA_evseConn_UT : 19|1@1+ (1,0) [0|0] ""  X
 SG_ FC_a149_CA_pcb_UT : 20|1@1+ (1,0) [0|0] ""  X
 SG_ FC_a150_CA_vehToEvseDeltaHi : 21|1@1+ (1,0) [0|0] ""  X
 SG_ FC_a151_CA_vehToEvseDeltaLo : 22|1@1+ (1,0) [0|0] ""  X
 SG_ FC_a152_CA_vehToPcbDeltaHi : 23|1@1+ (1,0) [0|0] ""  X
 SG_ FC_a153_CA_evseToPcbDeltaHi : 24|1@1+ (1,0) [0|0] ""  X
 SG_ FC_a154_CA_vehToPcbDeltaLo : 25|1@1+ (1,0) [0|0] ""  X
 SG_ FC_a155_CA_evseToPcbDeltaLo : 26|1@1+ (1,0) [0|0] ""  X
 SG_ FC_a156_CA_flybackRunTimeout : 27|1@1+ (1,0) [0|0] ""  X
 SG_ FC_a157_CA_unused : 28|1@1+ (1,0) [0|0] ""  X
 SG_ FC_a158_CA_evseOverCurrent : 29|1@1+ (1,0) [0|0] ""  X
 SG_ FC_a159_CA_wdtExpired : 30|1@1+ (1,0) [0|0] ""  X
 SG_ FC_a160_CA_ss2Deasserted : 31|1@1+ (1,0) [0|0] ""  X
 SG_ FC_a161_CA_vehTempHiFoldBk : 32|1@1+ (1,0) [0|0] ""  X
 SG_ FC_a162_CA_evseTempHiFoldBk : 33|1@1+ (1,0) [0|0] ""  X
 SG_ FC_a163_CA_pcbTempHiFoldBk : 34|1@1+ (1,0) [0|0] ""  X
 SG_ FC_a164_CA_proxDisconnected : 35|1@1+ (1,0) [0|0] ""  X
 SG_ FC_a165_CA_evseConnUnlocked : 36|1@1+ (1,0) [0|0] ""  X
 SG_ FC_a166_CA_vehConnUnlocked : 37|1@1+ (1,0) [0|0] ""  X
 SG_ FC_a167_CA_isoVoltageLow : 38|1@1+ (1,0) [0|0] ""  X
 SG_ FC_a168_CA_proxTimeout : 39|1@1+ (1,0) [0|0] ""  X
 SG_ FC_a169_CA_pilotAcceptTimeout : 40|1@1+ (1,0) [0|0] ""  X
 SG_ FC_a170_CA_vehDataTimeout : 41|1@1+ (1,0) [0|0] ""  X
 SG_ FC_a171_CA_vehConLockTimeout : 42|1@1+ (1,0) [0|0] ""  X
 SG_ FC_a172_CA_ss2LowTimeout : 43|1@1+ (1,0) [0|0] ""  X
 SG_ FC_a173_CA_evseDataTimeout : 44|1@1+ (1,0) [0|0] ""  X
 SG_ FC_a174_CA_vehReadyTimeout : 45|1@1+ (1,0) [0|0] ""  X
 SG_ FC_a175_CA_evseIsoTestTimeout : 46|1@1+ (1,0) [0|0] ""  X
 SG_ FC_a176_CA_chargingBusTimeout : 47|1@1+ (1,0) [0|0] ""  X
 SG_ FC_a177_CA_bmsCtrCloseTimeout : 48|1@1+ (1,0) [0|0] ""  X
 SG_ FC_a178_CA_evseStartTimeout : 49|1@1+ (1,0) [0|0] ""  X
 SG_ FC_a179_CA_startupProblem : 50|1@1+ (1,0) [0|0] ""  X
 SG_ FC_a180_CA_chargingProblem : 51|1@1+ (1,0) [0|0] ""  X
 SG_ FC_a181_CA_vRegBrownout : 52|1@1+ (1,0) [0|0] ""  X
 SG_ FC_a182_CA_evseChrMalfunc : 53|1@1+ (1,0) [0|0] ""  X
 SG_ FC_a183_CA_evseBatIncompat : 54|1@1+ (1,0) [0|0] ""  X
 SG_ FC_a184_CA_evseBatMalfunc : 55|1@1+ (1,0) [0|0] ""  X
 SG_ FC_a185_CA_vehReadyDeasserted : 56|1@1+ (1,0) [0|0] ""  X
 SG_ FC_a186_CA_fcContOpenTimeout : 57|1@1+ (1,0) [0|0] ""  X
 SG_ FC_a187_CA_evseConLockTimeout : 58|1@1+ (1,0) [0|0] ""  X

BO_ 927 FC_alertMatrix4: 8 VEH
 SG_ FC_a193_FCAlertPlaceholder : 0|1@1+ (1,0) [0|0] ""  X

BO_ 958 FC_alertMatrix5: 8 VEH
 SG_ FC_a257_GB_bmsMia : 0|1@1+ (1,0) [0|0] ""  X
 SG_ FC_a258_GB_evseMia : 1|1@1+ (1,0) [0|0] ""  X
 SG_ FC_a259_GB_vehTxBufOvf : 2|1@1+ (1,0) [0|0] ""  X
 SG_ FC_a260_GB_vehRxBufOvf : 3|1@1+ (1,0) [0|0] ""  X
 SG_ FC_a261_GB_evseTxBufOvf : 4|1@1+ (1,0) [0|0] ""  X
 SG_ FC_a262_GB_evseRxBufOvf : 5|1@1+ (1,0) [0|0] ""  X
 SG_ FC_a263_GB_hwProxTrip : 6|1@1+ (1,0) [0|0] ""  X
 SG_ FC_a264_GB_ss2NotLow : 7|1@1+ (1,0) [0|0] ""  X
 SG_ FC_a265_GB_bmsIncompatible : 8|1@1+ (1,0) [0|0] ""  X
 SG_ FC_a266_GB_negPin_OT : 9|1@1+ (1,0) [0|0] ""  X
 SG_ FC_a267_GB_posPin_OT : 10|1@1+ (1,0) [0|0] ""  X
 SG_ FC_a268_GB_pcb_OT : 11|1@1+ (1,0) [0|0] ""  X
 SG_ FC_a269_GB_unused : 12|1@1+ (1,0) [0|0] ""  X
 SG_ FC_a270_GB_unused : 13|1@1+ (1,0) [0|0] ""  X
 SG_ FC_a271_GB_unused : 14|1@1+ (1,0) [0|0] ""  X
 SG_ FC_a272_GB_negToPosDeltaHi : 15|1@1+ (1,0) [0|0] ""  X
 SG_ FC_a273_GB_negToPosDeltaLo : 16|1@1+ (1,0) [0|0] ""  X
 SG_ FC_a274_GB_negToPcbDeltaHi : 17|1@1+ (1,0) [0|0] ""  X
 SG_ FC_a275_GB_posToPcbDeltaHi : 18|1@1+ (1,0) [0|0] ""  X
 SG_ FC_a276_GB_negToPcbDeltaLo : 19|1@1+ (1,0) [0|0] ""  X
 SG_ FC_a277_GB_posToPcbDeltaLo : 20|1@1+ (1,0) [0|0] ""  X
 SG_ FC_a278_GB_unused : 21|1@1+ (1,0) [0|0] ""  X
 SG_ FC_a279_GB_evseOverCurrent : 22|1@1+ (1,0) [0|0] ""  X
 SG_ FC_a280_GB_unused : 23|1@1+ (1,0) [0|0] ""  X
 SG_ FC_a281_GB_ss2Deasserted : 24|1@1+ (1,0) [0|0] ""  X
 SG_ FC_a282_GB_negTempHiFoldBk : 25|1@1+ (1,0) [0|0] ""  X
 SG_ FC_a283_GB_posTempHiFoldBk : 26|1@1+ (1,0) [0|0] ""  X
 SG_ FC_a284_GB_pcbTempHiFoldBk : 27|1@1+ (1,0) [0|0] ""  X
 SG_ FC_a285_GB_proxDisconnected : 28|1@1+ (1,0) [0|0] ""  X
 SG_ FC_a286_GB_evseConnUnlocked : 29|1@1+ (1,0) [0|0] ""  X
 SG_ FC_a287_GB_vehConnUnlocked : 30|1@1+ (1,0) [0|0] ""  X
 SG_ FC_a288_GB_isoVoltageLow : 31|1@1+ (1,0) [0|0] ""  X
 SG_ FC_a289_GB_proxTimeout : 32|1@1+ (1,0) [0|0] ""  X
 SG_ FC_a290_GB_pilotAcceptTimeout : 33|1@1+ (1,0) [0|0] ""  X
 SG_ FC_a291_GB_vehDataTimeout : 34|1@1+ (1,0) [0|0] ""  X
 SG_ FC_a292_GB_vehConLockTimeout : 35|1@1+ (1,0) [0|0] ""  X
 SG_ FC_a293_GB_ss2LowTimeout : 36|1@1+ (1,0) [0|0] ""  X
 SG_ FC_a294_GB_evseDataTimeout : 37|1@1+ (1,0) [0|0] ""  X
 SG_ FC_a295_GB_vehReadyTimeout : 38|1@1+ (1,0) [0|0] ""  X
 SG_ FC_a296_GB_evseIsoTestTimeout : 39|1@1+ (1,0) [0|0] ""  X
 SG_ FC_a297_GB_chargingBusTimeout : 40|1@1+ (1,0) [0|0] ""  X
 SG_ FC_a298_GB_bmsCtrCloseTimeout : 41|1@1+ (1,0) [0|0] ""  X
 SG_ FC_a299_GB_evseReadyTimeout : 42|1@1+ (1,0) [0|0] ""  X
 SG_ FC_a300_GB_startupProblem : 43|1@1+ (1,0) [0|0] ""  X
 SG_ FC_a301_GB_chargingProblem : 44|1@1+ (1,0) [0|0] ""  X
 SG_ FC_a302_GB_vRegBrownout : 45|1@1+ (1,0) [0|0] ""  X
 SG_ FC_a303_GB_negRecogTimeout : 46|1@1+ (1,0) [0|0] ""  X
 SG_ FC_a304_GB_evseIncompatible : 47|1@1+ (1,0) [0|0] ""  X
 SG_ FC_a305_GB_posRecogTimeout : 48|1@1+ (1,0) [0|0] ""  X
 SG_ FC_a306_GB_vehReadyDeasserted : 49|1@1+ (1,0) [0|0] ""  X
 SG_ FC_a307_GB_fcContOpenTimeout : 50|1@1+ (1,0) [0|0] ""  X
 SG_ FC_a308_GB_evseConLockTimeout : 51|1@1+ (1,0) [0|0] ""  X
 SG_ FC_a309_GB_unused : 52|1@1+ (1,0) [0|0] ""  X
 SG_ FC_a310_GB_vehicleIdTimeout : 53|1@1+ (1,0) [0|0] ""  X
 SG_ FC_a311_GB_battParamsTimeout : 54|1@1+ (1,0) [0|0] ""  X
 SG_ FC_a312_GB_evseLimitsTimeout : 55|1@1+ (1,0) [0|0] ""  X

BO_ 990 FC_alertMatrix6: 8 VEH
 SG_ FC_a321_FCAlertPlaceholder : 0|1@1+ (1,0) [0|0] ""  X

BO_ 1303 FC_identifier: 8 VEH
 SG_ FC_id : 0|32@1+ (1,0) [0|0] ""  X
 SG_ FC_sessionId : 32|32@1+ (1,0) [0|0] ""  X

BO_ 1310 FC_info: 8 VEH
 SG_ FC_infoIndex M : 0|8@1+ (1,0) [0|0] ""  X
 SG_ FC_infoBuildType m10 : 8|3@1+ (1,0) [0|0] ""  X
 SG_ FC_infoBuildConfigID m10 : 16|8@1+ (1,0) [0|0] ""  X
 SG_ FC_infoHardwareID m10 : 32|16@1+ (1,0) [0|0] ""  X
 SG_ FC_infoComponentID m10 : 48|16@1+ (1,0) [0|0] ""  X
 SG_ FC_infoPcbaID m11 : 16|8@1+ (1,0) [0|0] ""  X
 SG_ FC_infoAssemblyID m11 : 24|8@1+ (1,0) [0|0] ""  X
 SG_ FC_infoUsageID m11 : 32|16@1+ (1,0) [0|0] ""  X
 SG_ FC_infoSubUsageID m11 : 48|16@1+ (1,0) [0|0] ""  X
 SG_ FC_infoApplicationCRC m13 : 32|32@1+ (1,0) [0|0] ""  X
 SG_ FC_infoBootSvnRev m14 : 8|24@1+ (1,0) [0|0] ""  X
 SG_ FC_infoBootCRC m15 : 32|32@1+ (1,0) [0|0] ""  X
 SG_ FC_infoCPLDVersionMajor m16 : 16|8@1+ (1,0) [0|0] ""  X
 SG_ FC_infoCPLDVersionMinor m16 : 24|8@1+ (1,0) [0|0] ""  X
 SG_ FC_infoAppGitHashBytes m17 : 10|54@1+ (4,0) [0|0] ""  X
 SG_ FC_infoBootGitHashBytes m18 : 10|54@1+ (4,0) [0|0] ""  X
 SG_ FC_infoPlatformType m19 : 8|8@1+ (1,0) [0|0] ""  X
 SG_ FC_infoMajorVersion m19 : 16|8@1+ (1,0) [0|0] ""  X
 SG_ FC_infoBranchOrigin m19 : 24|8@1+ (1,0) [0|0] ""  X
 SG_ FC_infoMaturity m19 : 32|8@1+ (1,0) [0|0] ""  X
 SG_ FC_infoHardwareRevision m19 : 40|8@1+ (1,0) [0|0] ""  X
 SG_ FC_infoBootUdsProtoVersion m20 : 8|8@1+ (1,0) [0|0] ""  X
 SG_ FC_infoVariantCRC m22 : 32|32@1+ (1,0) [0|0] ""  X
 SG_ FC_partNumChar01 m25 : 8|1@1+ (1,0) [0|0] ""  X
 SG_ FC_partNumChar02 m25 : 16|1@1+ (1,0) [0|0] ""  X
 SG_ FC_partNumChar03 m25 : 24|1@1+ (1,0) [0|0] ""  X
 SG_ FC_partNumChar04 m25 : 32|1@1+ (1,0) [0|0] ""  X
 SG_ FC_partNumChar05 m25 : 40|1@1+ (1,0) [0|0] ""  X
 SG_ FC_partNumChar06 m25 : 48|1@1+ (1,0) [0|0] ""  X
 SG_ FC_partNumChar07 m25 : 56|1@1+ (1,0) [0|0] ""  X
 SG_ FC_partNumChar08 m26 : 8|1@1+ (1,0) [0|0] ""  X
 SG_ FC_partNumChar09 m26 : 16|1@1+ (1,0) [0|0] ""  X
 SG_ FC_partNumChar10 m26 : 24|1@1+ (1,0) [0|0] ""  X
 SG_ FC_partNumChar11 m26 : 32|1@1+ (1,0) [0|0] ""  X
 SG_ FC_partNumChar12 m26 : 40|1@1+ (1,0) [0|0] ""  X
 SG_ FC_partNumChar13 m26 : 48|1@1+ (1,0) [0|0] ""  X
 SG_ FC_partNumChar14 m26 : 56|1@1+ (1,0) [0|0] ""  X
 SG_ FC_partNumChar15 m27 : 8|1@1+ (1,0) [0|0] ""  X
 SG_ FC_partNumChar16 m27 : 16|1@1+ (1,0) [0|0] ""  X
 SG_ FC_partNumChar17 m27 : 24|1@1+ (1,0) [0|0] ""  X
 SG_ FC_partNumChar18 m27 : 32|1@1+ (1,0) [0|0] ""  X
 SG_ FC_partNumChar19 m27 : 40|1@1+ (1,0) [0|0] ""  X
 SG_ FC_partNumChar20 m27 : 48|1@1+ (1,0) [0|0] ""  X

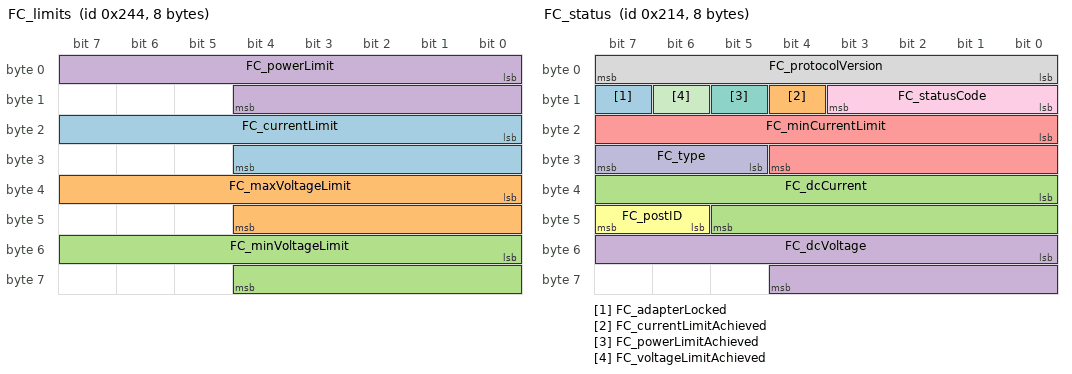
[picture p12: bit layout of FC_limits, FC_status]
BO_ 580 FC_limits: 8 VEH
 SG_ FC_currentLimit : 16|13@1+ (0.0732422,0) [0|0] "A"  X
 SG_ FC_maxVoltageLimit : 32|13@1+ (0.0732422,0) [0|0] "V"  X
 SG_ FC_minVoltageLimit : 48|13@1+ (0.0732422,0) [0|0] "V"  X
 SG_ FC_powerLimit : 0|13@1+ (0.0622559,0) [0|0] "kW"  X

BO_ 1345 FC_maxLimits: 8 VEH
 SG_ FC_maxCurrentLimit : 16|13@1+ (0.0732422,0) [0|0] "A"  X
 SG_ FC_maxPowerLimit : 0|13@1+ (0.0622559,0) [0|0] "kW"  X

BO_ 532 FC_status: 8 VEH
 SG_ FC_adapterLocked : 15|1@1+ (1,0) [0|0] ""  X
 SG_ FC_currentLimitAchieved : 12|1@1+ (1,0) [0|0] ""  X
 SG_ FC_dcCurrent : 32|14@1- (0.0732422,0) [0|0] "A"  X
 SG_ FC_dcVoltage : 48|13@1+ (0.0732422,0) [0|0] "V"  X
 SG_ FC_minCurrentLimit : 16|13@1+ (0.1,0) [0|0] "A"  X
 SG_ FC_postID : 46|2@1+ (2,0) [0|0] ""  X
 SG_ FC_powerLimitAchieved : 13|1@1+ (1,0) [0|0] ""  X
 SG_ FC_protocolVersion : 0|8@1+ (1,0) [0|0] ""  X
 SG_ FC_statusCode : 8|4@1+ (1,0) [0|0] ""  X
 SG_ FC_type : 29|3@1+ (1,0) [0|0] ""  X
 SG_ FC_voltageLimitAchieved : 14|1@1+ (1,0) [0|0] ""  X

BO_ 533 FC_status2: 1 VEH
 SG_ FC_externalIsolationResistance : 0|8@1+ (40,0) [0|0] "kOhm"  X

BO_ 535 FC_status3: 8 VEH
 SG_ FC_status3DataSelect M : 0|7@1+ (1,0) [0|0] ""  X
 SG_ FC_status3DummySig : 7|1@1+ (1,0) [0|0] ""  X
 SG_ FC_class m0 : 8|8@1+ (1,0) [0|0] ""  X
 SG_ FC_brand m0 : 16|4@1+ (1,0) [0|0] ""  X
 SG_ FC_coolingType m0 : 20|4@1+ (1,0) [0|0] ""  X
 SG_ FC_uiStopType m0 : 24|4@1+ (1,0) [0|0] ""  X

BO_ 888 GTW_ECall: 1 VEH
 SG_ GTW_GSM_ECALL_nLOCK : 0|1@1+ (1,0) [0|0] ""  X

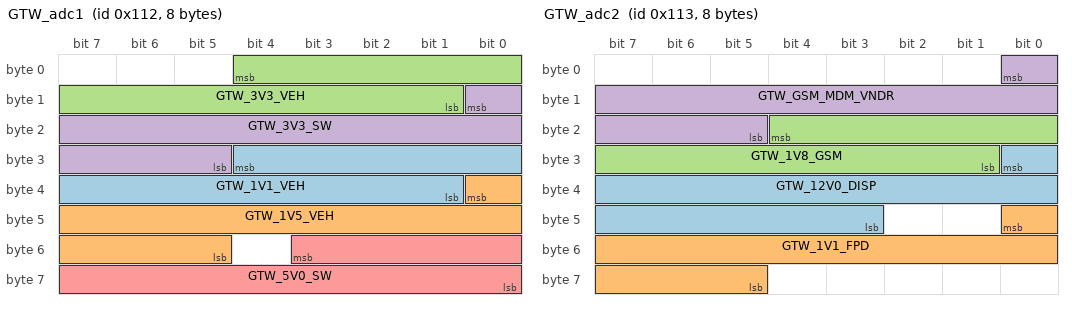
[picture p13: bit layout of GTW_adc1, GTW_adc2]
BO_ 274 GTW_adc1: 8 VEH
 SG_ GTW_1V1_VEH : 28|12@0+ (1,0) [0|0] "mV"  X
 SG_ GTW_1V5_VEH : 32|12@0+ (1,0) [0|0] "mV"  X
 SG_ GTW_3V3_VEH : 4|12@0+ (1.03,0) [0|0] "mV"  X
 SG_ GTW_3V3_SW : 8|12@0+ (1.5,0) [0|0] "mV"  X
 SG_ GTW_5V0_SW : 51|12@0+ (2,0) [0|0] "mV"  X

BO_ 275 GTW_adc2: 8 VEH
 SG_ GTW_12V0_DISP : 24|14@0+ (11,0) [0|0] "mV"  X
 SG_ GTW_1V1_FPD : 40|12@0+ (1,0) [0|0] "mV"  X
 SG_ GTW_1V8_GSM : 20|12@0+ (1,0) [0|0] "mV"  X
 SG_ GTW_GSM_MDM_VNDR : 0|12@0+ (1,0) [0|0] "mV"  X

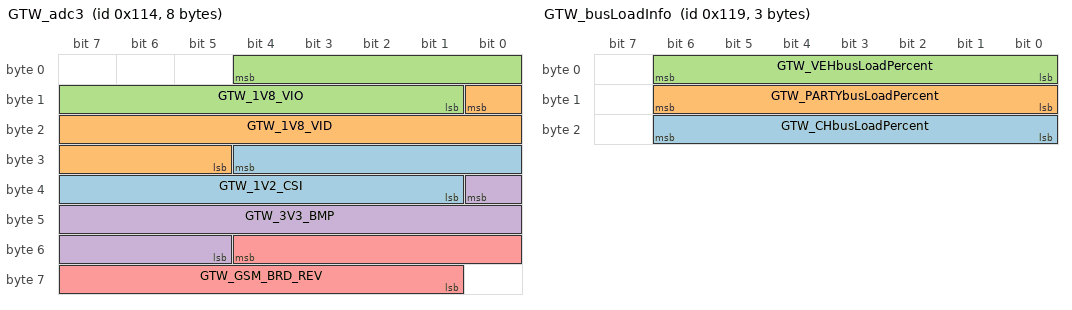
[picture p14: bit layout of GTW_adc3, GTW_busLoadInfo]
BO_ 276 GTW_adc3: 8 VEH
 SG_ GTW_1V2_CSI : 28|12@0+ (1,0) [0|0] "mV"  X
 SG_ GTW_1V8_VID : 8|12@0+ (1,0) [0|0] "mV"  X
 SG_ GTW_1V8_VIO : 4|12@0+ (2,0) [0|0] "mV"  X
 SG_ GTW_3V3_BMP : 32|12@0+ (2,0) [0|0] "mV"  X
 SG_ GTW_GSM_BRD_REV : 52|12@0+ (1,0) [0|0] "mV"  X

BO_ 62 GTW_alertMatrix: 8 VEH
 SG_ GTW_matrixIndex M : 0|4@1+ (1,0) [0|0] ""  X
 SG_ GTW_w000_GTW_ALERT_DO_NOT_USE m0 : 4|1@1+ (1,0) [0|0] ""  X
 SG_ GTW_w001_canVEHTxQueue m0 : 5|1@1+ (1,0) [0|0] ""  X
 SG_ GTW_w002_taskError m0 : 6|1@1+ (1,0) [0|0] ""  X
 SG_ GTW_w003_logWriteRecord m0 : 7|1@1+ (1,0) [0|0] ""  X
 SG_ GTW_w004_mallocHook m0 : 8|1@1+ (1,0) [0|0] ""  X
 SG_ GTW_w005_stackOverflowHook m0 : 9|1@1+ (1,0) [0|0] ""  X
 SG_ GTW_w006_ifTxOutputFull m0 : 10|1@1+ (1,0) [0|0] ""  X
 SG_ GTW_w007_ifRxBufError m0 : 11|1@1+ (1,0) [0|0] ""  X
 SG_ GTW_w008_ifPbufAllocError m0 : 12|1@1+ (1,0) [0|0] ""  X
 SG_ GTW_w009_lateTask m0 : 13|1@1+ (1,0) [0|0] ""  X
 SG_ GTW_w010_wdTaskCount m0 : 14|1@1+ (1,0) [0|0] ""  X
 SG_ GTW_w011_cancoreWatchdog m0 : 15|1@1+ (1,0) [0|0] ""  X
 SG_ GTW_w012_maincoreWatchdog m0 : 16|1@1+ (1,0) [0|0] ""  X
 SG_ GTW_w014_APSversionMismatch m0 : 17|1@1+ (1,0) [0|0] ""  X
 SG_ GTW_w015_DISversionMismatch m0 : 18|1@1+ (1,0) [0|0] ""  X
 SG_ GTW_w016_BLEEPversionMismatch m0 : 19|1@1+ (1,0) [0|0] ""  X
 SG_ GTW_w017_BMSversionMismatch m0 : 20|1@1+ (1,0) [0|0] ""  X
 SG_ GTW_w018_CMPversionMismatch m0 : 21|1@1+ (1,0) [0|0] ""  X
 SG_ GTW_w019_CPversionMismatch m0 : 22|1@1+ (1,0) [0|0] ""  X
 SG_ GTW_w020_DIversionMismatch m0 : 23|1@1+ (1,0) [0|0] ""  X
 SG_ GTW_w021_EPAS3PversionMismatch m0 : 24|1@1+ (1,0) [0|0] ""  X
 SG_ GTW_w022_EPBLversionMismatch m0 : 25|1@1+ (1,0) [0|0] ""  X
 SG_ GTW_w023_EPBRversionMismatch m0 : 26|1@1+ (1,0) [0|0] ""  X
 SG_ GTW_w024_ESPversionMismatch m0 : 27|1@1+ (1,0) [0|0] ""  X
 SG_ GTW_w025_ESPCALversionMismatch m0 : 28|1@1+ (1,0) [0|0] ""  X
 SG_ GTW_w026_GTWversionMismatch m0 : 29|1@1+ (1,0) [0|0] ""  X
 SG_ GTW_w027_HVPversionMismatch m0 : 30|1@1+ (1,0) [0|0] ""  X
 SG_ GTW_w028_IBSTversionMismatch m0 : 31|1@1+ (1,0) [0|0] ""  X
 SG_ GTW_w029_IBSTCALversionMismatch m0 : 32|1@1+ (1,0) [0|0] ""  X
 SG_ GTW_w030_OCS1PversionMismatch m0 : 33|1@1+ (1,0) [0|0] ""  X
 SG_ GTW_w031_PARKversionMismatch m0 : 34|1@1+ (1,0) [0|0] ""  X
 SG_ GTW_w032_PCSversionMismatch m0 : 35|1@1+ (1,0) [0|0] ""  X
 SG_ GTW_w033_PCSCPU2versionMismatch m0 : 36|1@1+ (1,0) [0|0] ""  X
 SG_ GTW_w034_PMversionMismatch m0 : 37|1@1+ (1,0) [0|0] ""  X
 SG_ GTW_w035_PMSversionMismatch m0 : 38|1@1+ (1,0) [0|0] ""  X
 SG_ GTW_w036_PTCversionMismatch m0 : 39|1@1+ (1,0) [0|0] ""  X
 SG_ GTW_w037_RADCversionMismatch m0 : 40|1@1+ (1,0) [0|0] ""  X
 SG_ GTW_w038_RCMversionMismatch m0 : 41|1@1+ (1,0) [0|0] ""  X
 SG_ GTW_w039_RCMCALversionMismatch m0 : 42|1@1+ (1,0) [0|0] ""  X
 SG_ GTW_w040_SCCMversionMismatch m0 : 43|1@1+ (1,0) [0|0] ""  X
 SG_ GTW_w041_VCSECversionMismatch m0 : 44|1@1+ (1,0) [0|0] ""  X
 SG_ GTW_w042_TASversionMismatch m0 : 45|1@1+ (1,0) [0|0] ""  X
 SG_ GTW_w043_THSversionMismatch m0 : 46|1@1+ (1,0) [0|0] ""  X
 SG_ GTW_w044_TPMSversionMismatch m0 : 47|1@1+ (1,0) [0|0] ""  X
 SG_ GTW_w045_VCFRONTversionMismatch m0 : 48|1@1+ (1,0) [0|0] ""  X
 SG_ GTW_w046_VCLEFTversionMismatch m0 : 49|1@1+ (1,0) [0|0] ""  X
 SG_ GTW_w047_VCRIGHTversionMismatch m0 : 50|1@1+ (1,0) [0|0] ""  X
 SG_ GTW_w048_EPAS3SversionMismatch m0 : 51|1@1+ (1,0) [0|0] ""  X
 SG_ GTW_w049_corruptedManifest m0 : 52|1@1+ (1,0) [0|0] ""  X
 SG_ GTW_w050_sdCardInitFailure m0 : 53|1@1+ (1,0) [0|0] ""  X
 SG_ GTW_w051_sdCardFileSystemFailure m0 : 54|1@1+ (1,0) [0|0] ""  X
 SG_ GTW_w052_ifTxSpans m0 : 55|1@1+ (1,0) [0|0] ""  X
 SG_ GTW_w053_busSleepFailure m0 : 56|1@1+ (1,0) [0|0] ""  X
 SG_ GTW_w054_OPCversionMismatch m0 : 57|1@1+ (1,0) [0|0] ""  X
 SG_ GTW_w055_OPCSversionMismatch m0 : 58|1@1+ (1,0) [0|0] ""  X
 SG_ GTW_w057_i2cFailure m0 : 59|1@1+ (1,0) [0|0] ""  X
 SG_ GTW_w058_rtcAlarmFailure m0 : 60|1@1+ (1,0) [0|0] ""  X
 SG_ GTW_w059_inFactoryMode m0 : 61|1@1+ (1,0) [0|0] ""  X
 SG_ GTW_w060_unFused m0 : 62|1@1+ (1,0) [0|0] ""  X
 SG_ GTW_w061_bmpSleepFailure m0 : 63|1@1+ (1,0) [0|0] ""  X
 SG_ GTW_w062_bmpWatchdog m1 : 4|1@1+ (1,0) [0|0] ""  X
 SG_ GTW_w063_VEH_canFault m1 : 5|1@1+ (1,0) [0|0] ""  X
 SG_ GTW_w064_CH_canFault m1 : 6|1@1+ (1,0) [0|0] ""  X
 SG_ GTW_w065_PARTY_canFault m1 : 7|1@1+ (1,0) [0|0] ""  X
 SG_ GTW_w066_exception m1 : 8|1@1+ (1,0) [0|0] ""  X
 SG_ GTW_w067_tcpDebug m1 : 9|1@1+ (1,0) [0|0] ""  X
 SG_ GTW_w068_prodKeyMissing m1 : 10|1@1+ (1,0) [0|0] ""  X
 SG_ GTW_w069_diskioErr m1 : 11|1@1+ (1,0) [0|0] ""  X
 SG_ GTW_w070_hrlDump m1 : 12|1@1+ (1,0) [0|0] ""  X
 SG_ GTW_w071_hrlTrigger m1 : 13|1@1+ (1,0) [0|0] ""  X
 SG_ GTW_w072_updateFailure m1 : 14|1@1+ (1,0) [0|0] ""  X
 SG_ GTW_w073_steeringWheelReset m1 : 15|1@1+ (1,0) [0|0] ""  X
 SG_ GTW_w074_epas3pMIA m1 : 16|1@1+ (1,0) [0|0] ""  X
 SG_ GTW_w075_epas3sMIA m1 : 17|1@1+ (1,0) [0|0] ""  X
 SG_ GTW_w076_VEHInterfaceReset m1 : 18|1@1+ (1,0) [0|0] ""  X
 SG_ GTW_w077_bmpPmicError m1 : 19|1@1+ (1,0) [0|0] ""  X
 SG_ GTW_w078_VEHbusOverloaded m1 : 20|1@1+ (1,0) [0|0] ""  X
 SG_ GTW_w079_PARTYbusOverloaded m1 : 21|1@1+ (1,0) [0|0] ""  X
 SG_ GTW_w080_CHbusOverloaded m1 : 22|1@1+ (1,0) [0|0] ""  X
 SG_ GTW_w081_udsMessageRejected m1 : 23|1@1+ (1,0) [0|0] ""  X
 SG_ GTW_w082_sdCardBSCorrupted m1 : 24|1@1+ (1,0) [0|0] ""  X
 SG_ GTW_w083_udsMsgDroppedByTcpStack m1 : 25|1@1+ (1,0) [0|0] ""  X
 SG_ GTW_w084_canFrameDropped m1 : 26|1@1+ (1,0) [0|0] ""  X
 SG_ GTW_w085_iBoosterStuck m1 : 27|1@1+ (1,0) [0|0] ""  X
 SG_ GTW_w086_ocu m1 : 28|1@1+ (1,0) [0|0] ""  X
 SG_ GTW_w087_ocuInProgress m1 : 29|1@1+ (1,0) [0|0] ""  X
 SG_ GTW_w088_sdCardInvReqParallel m1 : 30|1@1+ (1,0) [0|0] ""  X
 SG_ GTW_w089_sdCardWatchdog m1 : 31|1@1+ (1,0) [0|0] ""  X
 SG_ GTW_w090_ocuFailed m1 : 32|1@1+ (1,0) [0|0] ""  X
 SG_ GTW_w091_lowStack m1 : 33|1@1+ (1,0) [0|0] ""  X
 SG_ GTW_w092_sdCardInvReqZero m1 : 34|1@1+ (1,0) [0|0] ""  X
 SG_ GTW_w093_sdCardInvReqOverflowBas m1 : 35|1@1+ (1,0) [0|0] ""  X
 SG_ GTW_w094_sdCardInvReqOverflowCou m1 : 36|1@1+ (1,0) [0|0] ""  X
 SG_ GTW_w095_sdCardFull m1 : 37|1@1+ (1,0) [0|0] ""  X
 SG_ GTW_w096_sdCardFatCorrupted m1 : 38|1@1+ (1,0) [0|0] ""  X
 SG_ GTW_w097_HCMLversionMismatch m1 : 39|1@1+ (1,0) [0|0] ""  X
 SG_ GTW_w098_HCMRversionMismatch m1 : 40|1@1+ (1,0) [0|0] ""  X
 SG_ GTW_w099_SWCversionMismatch m1 : 41|1@1+ (1,0) [0|0] ""  X
 SG_ GTW_w100_CBCversionMismatch m1 : 42|1@1+ (1,0) [0|0] ""  X
 SG_ GTW_w101_switchWatchdog m1 : 43|1@1+ (1,0) [0|0] ""  X
 SG_ GTW_w103_sdCardFormatted m1 : 44|1@1+ (1,0) [0|0] ""  X
 SG_ GTW_w104_sdCardDriverArgCorrupte m1 : 45|1@1+ (1,0) [0|0] ""  X
 SG_ GTW_w105_eBuckConfigured m1 : 46|1@1+ (1,0) [0|0] ""  X
 SG_ GTW_w106_failedToStartUpdater m1 : 47|1@1+ (1,0) [0|0] ""  X

BO_ 281 GTW_busLoadInfo: 3 VEH
 SG_ GTW_CHbusLoadPercent : 16|7@1+ (1,0) [0|0] "percent"  X
 SG_ GTW_PARTYbusLoadPercent : 8|7@1+ (1,0) [0|0] "percent"  X
 SG_ GTW_VEHbusLoadPercent : 0|7@1+ (1,0) [0|0] "percent"  X

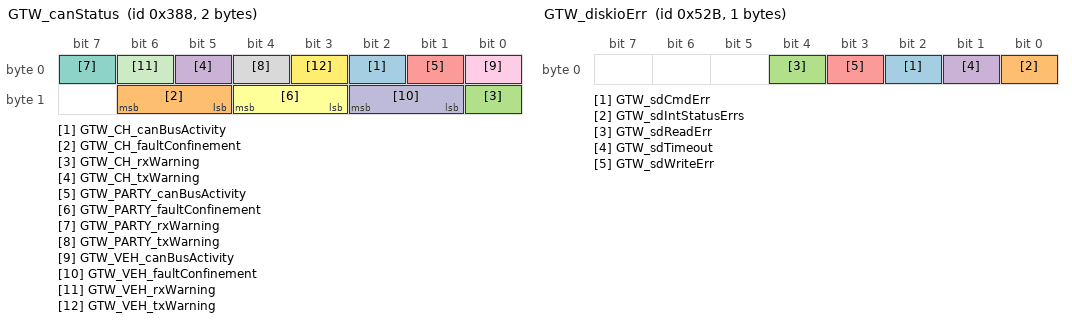
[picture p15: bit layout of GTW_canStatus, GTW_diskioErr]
BO_ 904 GTW_canStatus: 2 VEH
 SG_ GTW_CH_canBusActivity : 2|1@1+ (1,0) [0|0] ""  X
 SG_ GTW_CH_faultConfinement : 13|2@1+ (1,0) [0|0] ""  X
 SG_ GTW_CH_rxWarning : 8|1@1+ (1,0) [0|0] ""  X
 SG_ GTW_CH_txWarning : 5|1@1+ (1,0) [0|0] ""  X
 SG_ GTW_PARTY_canBusActivity : 1|1@1+ (1,0) [0|0] ""  X
 SG_ GTW_PARTY_faultConfinement : 11|2@1+ (1,0) [0|0] ""  X
 SG_ GTW_PARTY_rxWarning : 7|1@1+ (1,0) [0|0] ""  X
 SG_ GTW_PARTY_txWarning : 4|1@1+ (1,0) [0|0] ""  X
 SG_ GTW_VEH_canBusActivity : 0|1@1+ (1,0) [0|0] ""  X
 SG_ GTW_VEH_faultConfinement : 9|2@1+ (1,0) [0|0] ""  X
 SG_ GTW_VEH_rxWarning : 6|1@1+ (1,0) [0|0] ""  X
 SG_ GTW_VEH_txWarning : 3|1@1+ (1,0) [0|0] ""  X

BO_ 2047 GTW_carConfig: 8 VEH
 SG_ GTW_carConfigMultiplexer M : 0|8@1+ (1,0) [0|255] ""  Receiver
 SG_ GTW_CabinBlowerCtrlType m2 : 30|1@1+ (1,0) [0|1] ""  Receiver
 SG_ GTW_activeHighBeam m2 : 34|1@1+ (1,0) [0|1] ""  Receiver
 SG_ GTW_airSuspension m3 : 22|2@1+ (1,0) [0|2] ""  Receiver
 SG_ GTW_airbagCutoffSwitch m2 : 35|1@1+ (1,0) [0|1] ""  Receiver
 SG_ GTW_audioType m3 : 30|2@1+ (1,0) [0|2] ""  Receiver
 SG_ GTW_autopilot m2 : 42|3@1+ (1,0) [0|4] ""  Receiver
 SG_ GTW_autopilotCameraType m3 : 26|1@1+ (1,0) [0|0] ""  Receiver
 SG_ GTW_auxParkLamps m2 : 26|2@1+ (1,0) [0|3] ""  Receiver
 SG_ GTW_bPillarNFCParam m2 : 56|1@1+ (1,0) [0|1] ""  Receiver
 SG_ GTW_birthday m4 : 8|32@1+ (1,0) [0|4294970000] ""  Receiver
 SG_ GTW_brakeHWType m2 : 59|2@1+ (1,0) [0|3] ""  Receiver
 SG_ GTW_brakeLineSwitchType m3 : 39|1@1+ (1,0) [0|1] ""  Receiver
 SG_ GTW_cabinPTCHeaterType m2 : 31|1@1+ (1,0) [0|1] ""  Receiver
 SG_ GTW_chassisType m3 : 18|3@1+ (1,0) [0|4] ""  Receiver
 SG_ GTW_compressorType m2 : 47|1@1+ (1,0) [0|1] ""  Receiver
 SG_ GTW_connectivityPackage m3 : 27|1@1+ (1,0) [0|1] ""  Receiver
 SG_ GTW_coolantPumpType m3 : 17|1@1+ (1,0) [0|1] ""  Receiver
 SG_ GTW_country m1 : 16|16@1+ (1,0) [0|65535] ""  Receiver
 SG_ GTW_dasHw m1 : 40|3@1+ (1,0) [3|4] ""  Receiver
 SG_ GTW_deliveryStatus m1 : 8|1@1+ (1,0) [0|1] ""  Receiver
 SG_ GTW_drivetrainType m1 : 10|1@1+ (1,0) [0|1] ""  odin
 SG_ GTW_eBuckConfig m2 : 32|1@1+ (1,0) [0|1] ""  Receiver
 SG_ GTW_eCallEnabled m4 : 40|2@1+ (1,0) [0|2] ""  Receiver
 SG_ GTW_efficiencyPackage m3 : 58|2@1+ (1,0) [0|3] ""  Receiver
 SG_ GTW_epasType m1 : 9|1@1+ (1,0) [0|1] ""  Receiver
 SG_ GTW_espValveType m3 : 40|2@1+ (1,0) [0|2] ""  Receiver
 SG_ GTW_exteriorColor m2 : 48|3@1+ (1,0) [0|6] ""  Receiver
 SG_ GTW_frontFogLamps m2 : 20|1@1+ (1,0) [0|1] ""  Receiver
 SG_ GTW_frontSeatHeaters m2 : 9|1@1+ (1,0) [0|1] ""  Receiver
 SG_ GTW_frontSeatReclinerHardware m3 : 37|2@1+ (1,0) [0|3] ""  Receiver
 SG_ GTW_frontSeatType m3 : 60|3@1+ (1,0) [0|4] ""  Receiver
 SG_ GTW_headlamps m1 : 14|2@1+ (1,0) [0|2] ""  Receiver
 SG_ GTW_headlightLevelerType m3 : 47|1@1+ (1,0) [0|1] ""  Receiver
 SG_ GTW_heatedWipers m2 : 8|1@1+ (1,0) [0|1] ""  Receiver
 SG_ GTW_homelinkType m2 : 13|1@1+ (1,0) [0|1] ""  Receiver
 SG_ GTW_hvacPanelVaneType m2 : 29|1@1+ (1,0) [0|1] ""  Receiver
 SG_ GTW_hvacQuietSnorkelType m2 : 28|1@1+ (1,0) [0|1] ""  Receiver
 SG_ GTW_ibstWakeType m2 : 24|1@1+ (1,0) [0|1] ""  Receiver
 SG_ GTW_immersiveAudio m3 : 56|2@1+ (1,0) [0|2] ""  Receiver
 SG_ GTW_interiorLighting m2 : 57|2@1+ (1,0) [0|2] ""  Receiver
 SG_ GTW_intrusionSensorType m2 : 36|1@1+ (1,0) [0|1] ""  Receiver
 SG_ GTW_loggingVersion m2 : 22|1@1+ (1,0) [0|1] ""  Receiver
 SG_ GTW_lumbarECUType m2 : 23|1@1+ (1,0) [0|1] ""  Receiver
 SG_ GTW_m3FrontOverheadConsoleType m2 : 25|1@1+ (1,0) [0|1] ""  Receiver
 SG_ GTW_mapRegion m3 : 8|4@1+ (1,0) [0|10] ""  Receiver
 SG_ GTW_memoryMirrors m2 : 17|1@1+ (1,0) [0|1] ""  Receiver
 SG_ GTW_numberHVILNodes m2 : 51|3@1+ (1,0) [0|5] ""  Receiver
 SG_ GTW_packEnergy m3 : 32|5@1+ (1,0) [0|4] ""  Receiver
 SG_ GTW_packMassDeviation m4 : 42|1@1+ (1,0) [0|1] ""  Receiver
 SG_ GTW_passengerAirbagType m4 : 43|2@1+ (1,0) [0|2] ""  Receiver
 SG_ GTW_passengerOccupancySensorType m3 : 24|1@1+ (1,0) [0|1] ""  Receiver
 SG_ GTW_pedestrianWarningSound m2 : 54|1@1+ (1,0) [0|1] ""  Receiver
 SG_ GTW_performancePackage m3 : 12|3@1+ (1,0) [0|3] ""  Receiver
 SG_ GTW_plcSupportType m3 : 28|2@1+ (1,0) [0|2] ""  Receiver
 SG_ GTW_powerSteeringColumn m2 : 18|1@1+ (1,0) [0|1] ""  Receiver
 SG_ GTW_radarHeaterType m3 : 55|1@1+ (1,0) [0|1] ""  Receiver
 SG_ GTW_rearDriveUnitType m3 : 21|1@1+ (1,0) [0|1] ""  Receiver
 SG_ GTW_rearFogLamps m2 : 39|1@1+ (1,0) [0|1] ""  Receiver
 SG_ GTW_rearGlassType m2 : 38|1@1+ (1,0) [0|1] ""  Receiver
 SG_ GTW_rearLightType m1 : 12|2@1+ (1,0) [0|2] ""  Receiver
 SG_ GTW_rearSeatHeaters m2 : 10|1@1+ (1,0) [0|1] ""  Receiver
 SG_ GTW_refrigerantType m3 : 45|2@1+ (1,0) [0|2] ""  Receiver
 SG_ GTW_restraintsHardwareType m1 : 48|8@1+ (1,0) [21|163] ""  Receiver
 SG_ GTW_rightHandDrive m1 : 11|1@1+ (1,0) [0|1] ""  Receiver
 SG_ GTW_roofGlassType m2 : 61|1@1+ (1,0) [0|1] ""  Receiver
 SG_ GTW_roofType m2 : 40|2@1+ (1,0) [0|2] ""  Receiver
 SG_ GTW_softRange m3 : 42|3@1+ (1,0) [0|2] ""  Receiver
 SG_ GTW_spoilerType m2 : 37|1@1+ (1,0) [0|1] ""  Receiver
 SG_ GTW_steeringColumnUJointType m2 : 55|1@1+ (1,0) [0|1] ""  Receiver
 SG_ GTW_superchargingAccess m2 : 45|2@1+ (1,0) [0|2] ""  Receiver
 SG_ GTW_tireType m1 : 32|5@1+ (1,0) [0|21] ""  Receiver
 SG_ GTW_towPackage m3 : 15|1@1+ (1,0) [0|1] ""  Receiver
 SG_ GTW_tpmsType m2 : 11|1@1+ (1,0) [0|1] ""  Receiver
 SG_ GTW_trackModePackage m2 : 62|1@1+ (1,0) [0|1] ""  Receiver
 SG_ GTW_twelveVBatteryType m3 : 63|1@1+ (1,0) [0|1] ""  Receiver
 SG_ GTW_vdcType m2 : 14|1@1+ (1,0) [0|1] ""  Receiver
 SG_ GTW_wheelType m3 : 48|7@1+ (1,0) [0|20] ""  Receiver
 SG_ GTW_windshieldType m2 : 33|1@1+ (1,0) [0|1] ""  Receiver
 SG_ GTW_xcpESP m2 : 16|1@1+ (1,0) [0|1] ""  Receiver
 SG_ GTW_xcpIbst m2 : 15|1@1+ (1,0) [0|1] ""  Receiver

BO_ 1323 GTW_diskioErr: 1 VEH
 SG_ GTW_sdCmdErr : 2|1@1+ (1,0) [0|0] ""  X
 SG_ GTW_sdIntStatusErrs : 0|1@1+ (1,0) [0|0] ""  X
 SG_ GTW_sdReadErr : 4|1@1+ (1,0) [0|0] ""  X
 SG_ GTW_sdTimeout : 1|1@1+ (1,0) [0|0] ""  X
 SG_ GTW_sdWriteErr : 3|1@1+ (1,0) [0|0] ""  X

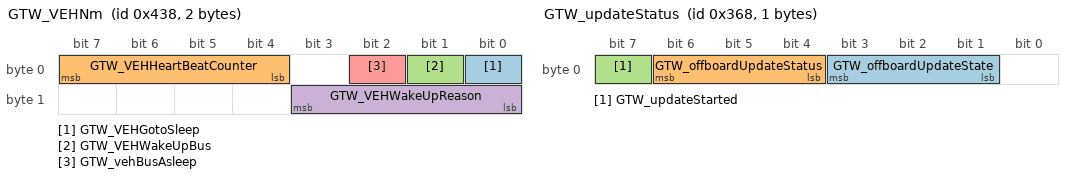
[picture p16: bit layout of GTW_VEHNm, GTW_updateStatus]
BO_ 1080 GTW_VEHNm: 2 VEH
 SG_ GTW_VEHGotoSleep : 0|1@1+ (1,0) [0|0] ""  X
 SG_ GTW_VEHHeartBeatCounter : 4|4@1+ (1,0) [0|0] ""  X
 SG_ GTW_VEHWakeUpBus : 1|1@1+ (1,0) [0|0] ""  X
 SG_ GTW_VEHWakeUpReason : 8|4@1+ (1,0) [0|0] ""  X
 SG_ GTW_vehBusAsleep : 2|1@1+ (1,0) [0|0] ""  X

BO_ 1376 GTW_factoryEcuPresent: 4 VEH
 SG_ GTW_BMSpresent : 0|1@1+ (1,0) [0|0] ""  X
 SG_ GTW_CMPpresent : 23|1@1+ (1,0) [0|0] ""  X
 SG_ GTW_CPpresent : 26|1@1+ (1,0) [0|0] ""  X
 SG_ GTW_DASpresent : 24|1@1+ (1,0) [0|0] ""  X
 SG_ GTW_DISpresent : 2|1@1+ (1,0) [0|0] ""  X
 SG_ GTW_DIpresent : 1|1@1+ (1,0) [0|0] ""  X
 SG_ GTW_EPAS3Ppresent : 3|1@1+ (1,0) [0|0] ""  X
 SG_ GTW_EPAS3Spresent : 22|1@1+ (1,0) [0|0] ""  X
 SG_ GTW_EPBLpresent : 4|1@1+ (1,0) [0|0] ""  X
 SG_ GTW_EPBRpresent : 5|1@1+ (1,0) [0|0] ""  X
 SG_ GTW_ESPpresent : 6|1@1+ (1,0) [0|0] ""  X
 SG_ GTW_HVPpresent : 7|1@1+ (1,0) [0|0] ""  X
 SG_ GTW_IBSTpresent : 8|1@1+ (1,0) [0|0] ""  X
 SG_ GTW_OCS1Ppresent : 9|1@1+ (1,0) [0|0] ""  X
 SG_ GTW_PARKpresent : 10|1@1+ (1,0) [0|0] ""  X
 SG_ GTW_PCSpresent : 11|1@1+ (1,0) [0|0] ""  X
 SG_ GTW_PMSpresent : 13|1@1+ (1,0) [0|0] ""  X
 SG_ GTW_PMpresent : 12|1@1+ (1,0) [0|0] ""  X
 SG_ GTW_PTCpresent : 25|1@1+ (1,0) [0|0] ""  X
 SG_ GTW_RADCpresent : 14|1@1+ (1,0) [0|0] ""  X
 SG_ GTW_RCMpresent : 15|1@1+ (1,0) [0|0] ""  X
 SG_ GTW_SCCMpresent : 16|1@1+ (1,0) [0|0] ""  X
 SG_ GTW_SWCpresent : 27|1@1+ (1,0) [0|0] ""  X
 SG_ GTW_TPMSpresent : 18|1@1+ (1,0) [0|0] ""  X
 SG_ GTW_VCFRONTpresent : 19|1@1+ (1,0) [0|0] ""  X
 SG_ GTW_VCLEFTpresent : 20|1@1+ (1,0) [0|0] ""  X
 SG_ GTW_VCRIGHTpresent : 21|1@1+ (1,0) [0|0] ""  X
 SG_ GTW_VCSECpresent : 17|1@1+ (1,0) [0|0] ""  X

BO_ 2033 GTW_hrl: 8 VEH
 SG_ GTW_hrlIndex M : 0|2@1+ (1,0) [0|0] ""  X
 SG_ GTW_hrlPagesCount m1 : 8|32@0+ (1,0) [0|0] ""  X
 SG_ GTW_hrlState m2 : 2|1@1+ (1,0) [0|0] ""  X
 SG_ GTW_hrlTriggerDuration m2 : 12|16@0+ (1,0) [0|0] "seconds"  X
 SG_ GTW_hrlTriggerType m2 : 24|4@1+ (1,0) [0|0] ""  X
 SG_ GTW_hrlTriggerId m2 : 33|16@0+ (1,0) [0|0] ""  X
 SG_ GTW_hrlTriggerBus m2 : 56|3@1+ (1,0) [0|0] ""  X

BO_ 60 GTW_info: 8 VEH
 SG_ GTW_infoIndex M : 0|8@1+ (1,0) [0|0] ""  X
 SG_ GTW_applicationGitHash m17 : 10|54@1+ (4,0) [0|0] ""  X
 SG_ GTW_buildType m10 : 8|3@1+ (1,0) [0|0] ""  X
 SG_ GTW_hardwareId m10 : 32|16@1+ (1,0) [0|0] ""  X
 SG_ GTW_bootGitHash m18 : 10|54@1+ (4,0) [0|0] ""  X
 SG_ GTW_bootCrc m20 : 32|32@1+ (1,0) [0|0] ""  X
 SG_ GTW_platformType m13 : 8|8@1+ (1,0) [0|0] ""  X
 SG_ GTW_appCrc m13 : 32|32@1+ (1,0) [0|0] ""  X

BO_ 840 GTW_status: 1 VEH
 SG_ GTW_autopilotTrial : 0|1@1+ (1,0) [0|0] ""  X
 SG_ GTW_vehicleVersionMatchStatus : 1|2@1+ (1,0) [0|0] ""  X

BO_ 872 GTW_updateStatus: 1 VEH
 SG_ GTW_offboardUpdateState : 1|3@1+ (1,0) [0|0] ""  X
 SG_ GTW_offboardUpdateStatus : 4|3@1+ (1,0) [0|0] ""  X
 SG_ GTW_updateStarted : 7|1@1+ (1,0) [0|0] ""  X

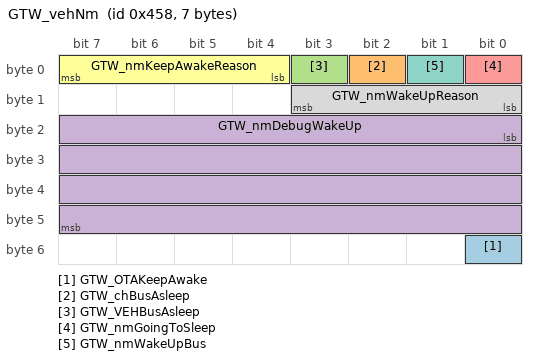
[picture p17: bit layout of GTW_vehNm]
BO_ 1112 GTW_vehNm: 7 VEH
 SG_ GTW_OTAKeepAwake : 48|1@1+ (1,0) [0|0] ""  X
 SG_ GTW_chBusAsleep : 2|1@1+ (1,0) [0|0] ""  X
 SG_ GTW_VEHBusAsleep : 3|1@1+ (1,0) [0|0] ""  X
 SG_ GTW_nmDebugWakeUp : 16|32@1+ (1,0) [0|0] ""  X
 SG_ GTW_nmGoingToSleep : 0|1@1+ (1,0) [0|0] ""  X
 SG_ GTW_nmKeepAwakeReason : 4|4@1+ (1,0) [0|0] ""  X
 SG_ GTW_nmWakeUpBus : 1|1@1+ (1,0) [0|0] ""  X
 SG_ GTW_nmWakeUpReason : 8|4@1+ (1,0) [0|0] ""  X

BO_ 938 HVP_alertMatrix1: 8 VEH
 SG_ HVP_w001_WatchdogReset : 0|1@1+ (1,0) [0|0] ""  X
 SG_ HVP_w002_UnusedAlert2 : 1|1@1+ (1,0) [0|0] ""  X
 SG_ HVP_w003_SwAssertion : 2|1@1+ (1,0) [0|0] ""  X
 SG_ HVP_w004_CrashEvent : 3|1@1+ (1,0) [0|0] ""  X
 SG_ HVP_w005_OverDchgCurrentFault : 4|1@1+ (1,0) [0|0] ""  X
 SG_ HVP_w006_OverChargeCurrentFault : 5|1@1+ (1,0) [0|0] ""  X
 SG_ HVP_w007_OverCurrentFault : 6|1@1+ (1,0) [0|0] ""  X
 SG_ HVP_w008_OverTemperatureFault : 7|1@1+ (1,0) [0|0] ""  X
 SG_ HVP_w009_OverVoltageFault : 8|1@1+ (1,0) [0|0] ""  X
 SG_ HVP_w010_UnderVoltageFault : 9|1@1+ (1,0) [0|0] ""  X
 SG_ HVP_w011_PrimaryBmbMiaFault : 10|1@1+ (1,0) [0|0] ""  X
 SG_ HVP_w012_SecondaryBmbMiaFault : 11|1@1+ (1,0) [0|0] ""  X
 SG_ HVP_w013_BmbMismatchFault : 12|1@1+ (1,0) [0|0] ""  X
 SG_ HVP_w014_BmsHviMiaFault : 13|1@1+ (1,0) [0|0] ""  X
 SG_ HVP_w015_CpMiaFault : 14|1@1+ (1,0) [0|0] ""  X
 SG_ HVP_w016_PcsMiaFault : 15|1@1+ (1,0) [0|0] ""  X
 SG_ HVP_w017_BmsFault : 16|1@1+ (1,0) [0|0] ""  X
 SG_ HVP_w018_PcsFault : 17|1@1+ (1,0) [0|0] ""  X
 SG_ HVP_w019_CpFault : 18|1@1+ (1,0) [0|0] ""  X
 SG_ HVP_w020_ShuntHwMiaFault : 19|1@1+ (1,0) [0|0] ""  X
 SG_ HVP_w021_PyroMiaFault : 20|1@1+ (1,0) [0|0] ""  X
 SG_ HVP_w022_hvsMiaFault : 21|1@1+ (1,0) [0|0] ""  X
 SG_ HVP_w024_Supply12vFault : 23|1@1+ (1,0) [0|0] ""  X
 SG_ HVP_w025_VerSupplyFault : 24|1@1+ (1,0) [0|0] ""  X
 SG_ HVP_w026_HvilFault : 25|1@1+ (1,0) [0|0] ""  X
 SG_ HVP_w027_BmsHvsMiaFault : 26|1@1+ (1,0) [0|0] ""  X
 SG_ HVP_w028_PackVoltMismatchFault : 27|1@1+ (1,0) [0|0] ""  X
 SG_ HVP_w029_EnsMiaFault : 28|1@1+ (1,0) [0|0] ""  X
 SG_ HVP_w030_PackPosCtrArcFault : 29|1@1+ (1,0) [0|0] ""  X
 SG_ HVP_w031_packNegCtrArcFault : 30|1@1+ (1,0) [0|0] ""  X
 SG_ HVP_w032_ShuntHwAndBmsMiaFault : 31|1@1+ (1,0) [0|0] ""  X
 SG_ HVP_w033_fcContHwFault : 32|1@1+ (1,0) [0|0] ""  X
 SG_ HVP_w034_robinOverVoltageFault : 33|1@1+ (1,0) [0|0] ""  X
 SG_ HVP_w035_packContHwFault : 34|1@1+ (1,0) [0|0] ""  X
 SG_ HVP_w036_pyroFuseBlown : 35|1@1+ (1,0) [0|0] ""  X
 SG_ HVP_w037_pyroFuseFailedToBlow : 36|1@1+ (1,0) [0|0] ""  X
 SG_ HVP_w038_CpilFault : 37|1@1+ (1,0) [0|0] ""  X
 SG_ HVP_w039_PackContactorFellOpen : 38|1@1+ (1,0) [0|0] ""  X
 SG_ HVP_w040_FcContactorFellOpen : 39|1@1+ (1,0) [0|0] ""  X
 SG_ HVP_w041_packCtrCloseBlocked : 40|1@1+ (1,0) [0|0] ""  X
 SG_ HVP_w042_fcCtrCloseBlocked : 41|1@1+ (1,0) [0|0] ""  X
 SG_ HVP_w043_packContactorForceOpen : 42|1@1+ (1,0) [0|0] ""  X
 SG_ HVP_w044_fcContactorForceOpen : 43|1@1+ (1,0) [0|0] ""  X
 SG_ HVP_w045_dcLinkOverVoltage : 44|1@1+ (1,0) [0|0] ""  X
 SG_ HVP_w046_shuntOverTemperature : 45|1@1+ (1,0) [0|0] ""  X
 SG_ HVP_w047_passivePyroDeploy : 46|1@1+ (1,0) [0|0] ""  X
 SG_ HVP_w048_logUploadRequest : 47|1@1+ (1,0) [0|0] ""  X
 SG_ HVP_w049_packCtrCloseFailed : 48|1@1+ (1,0) [0|0] ""  X
 SG_ HVP_w050_fcCtrCloseFailed : 49|1@1+ (1,0) [0|0] ""  X
 SG_ HVP_w051_shuntThermistorMia : 50|1@1+ (1,0) [0|0] ""  X

BO_ 522 HVP_contactorState: 6 VEH
 SG_ HVP_dcLinkAllowedToEnergize : 38|1@1+ (1,0) [0|0] ""  X
 SG_ HVP_fcContNegativeState : 12|3@1+ (1,0) [0|0] ""  X
 SG_ HVP_fcContPositiveState : 16|3@1+ (1,0) [0|0] ""  X
 SG_ HVP_fcContactorSetState : 19|4@1+ (1,0) [0|0] ""  X
 SG_ HVP_fcCtrsClosingAllowed : 29|1@1+ (1,0) [0|0] ""  X
 SG_ HVP_fcCtrsOpenNowRequested : 27|1@1+ (1,0) [0|0] ""  X
 SG_ HVP_fcCtrsOpenRequested : 28|1@1+ (1,0) [0|0] ""  X
 SG_ HVP_fcCtrsRequestStatus : 24|2@1+ (1,0) [0|0] ""  X
 SG_ HVP_fcCtrsResetRequestRequired : 26|1@1+ (1,0) [0|0] ""  X
 SG_ HVP_fcLinkAllowedToEnergizeAc : 30|1@1+ (1,0) [0|0] ""  X
 SG_ HVP_fcLinkAllowedToEnergizeDc : 31|1@1+ (1,0) [0|0] ""  X
 SG_ HVP_hvilStatus : 40|4@1+ (1,0) [0|0] ""  X
 SG_ HVP_packContNegativeState : 0|3@1+ (1,0) [0|0] ""  X
 SG_ HVP_packContPositiveState : 3|3@1+ (1,0) [0|0] ""  X
 SG_ HVP_packContactorSetState : 8|4@1+ (1,0) [0|0] ""  X
 SG_ HVP_packCtrsClosingAllowed : 37|1@1+ (1,0) [0|0] ""  X
 SG_ HVP_packCtrsOpenNowRequested : 35|1@1+ (1,0) [0|0] ""  X
 SG_ HVP_packCtrsOpenRequested : 36|1@1+ (1,0) [0|0] ""  X
 SG_ HVP_packCtrsRequestStatus : 32|2@1+ (1,0) [0|0] ""  X
 SG_ HVP_packCtrsResetRequestRequired : 34|1@1+ (1,0) [0|0] ""  X
 SG_ HVP_pyroTestInProgress : 39|1@1+ (1,0) [0|0] ""  X

BO_ 1962 HVP_debugMessage: 8 VEH
 SG_ HVP_debugMessageMultiplexer M : 0|4@1+ (1,0) [0|6] ""  Receiver
 SG_ HVP_auxCurrentMia m0 : 57|1@1+ (1,0) [0|1] ""  Receiver
 SG_ HVP_battery12V m5 : 36|12@1+ (0.1,0) [0|30] "V"  Receiver
 SG_ HVP_currentSenseMia m0 : 58|1@1+ (1,0) [0|1] ""  Receiver
 SG_ HVP_dcLinkNegativeV m3 : 8|16@1- (0.1,0) [-550|550] "V"  Receiver
 SG_ HVP_dcLinkPositiveV m3 : 24|16@1- (0.1,0) [-550|550] "V"  Receiver
 SG_ HVP_dcLinkVoltage m1 : 8|16@1- (0.1,0) [-3276.8|3276.7] "V"  Receiver
 SG_ HVP_fcContCoilCurrent m4 : 4|12@1+ (0.1,0) [0|7.5] "A"  Receiver
 SG_ HVP_fcContVoltage m4 : 16|12@1+ (0.1,0) [0|30] "V"  Receiver
 SG_ HVP_fcLinkNegativeV m3 : 40|16@1- (0.1,0) [-550|550] "V"  Receiver
 SG_ HVP_fcLinkPositiveV m5 : 8|16@1- (0.1,0) [-550|550] "V"  Receiver
 SG_ HVP_fcLinkVoltage m1 : 40|16@1- (0.1,0) [-3276.8|3276.7] "V"  Receiver
 SG_ HVP_gpioBmsEout m0 : 15|1@1+ (1,0) [0|1] ""  Receiver
 SG_ HVP_gpioCpFaultIn m0 : 6|1@1+ (1,0) [0|1] ""  Receiver
 SG_ HVP_gpioCpFaultOut m0 : 16|1@1+ (1,0) [0|1] ""  Receiver
 SG_ HVP_gpioCpLatchEnable m0 : 21|1@1+ (1,0) [0|1] ""  Receiver
 SG_ HVP_gpioCrashSignal m0 : 11|1@1+ (1,0) [0|1] ""  Receiver
 SG_ HVP_gpioFcContNegAux m0 : 14|1@1+ (1,0) [0|1] ""  Receiver
 SG_ HVP_gpioFcContPosAux m0 : 13|1@1+ (1,0) [0|1] ""  Receiver
 SG_ HVP_gpioFcContPowerEnable m0 : 25|1@1+ (1,0) [0|1] ""  Receiver
 SG_ HVP_gpioHvCablesOk m0 : 8|1@1+ (1,0) [0|1] ""  Receiver
 SG_ HVP_gpioHvilEnable m0 : 26|1@1+ (1,0) [0|1] ""  Receiver
 SG_ HVP_gpioHvpSelfEnable m0 : 9|1@1+ (1,0) [0|1] ""  Receiver
 SG_ HVP_gpioHvpVerEn m0 : 19|1@1+ (1,0) [0|1] ""  Receiver
 SG_ HVP_gpioLed m0 : 10|1@1+ (1,0) [0|1] ""  Receiver
 SG_ HVP_gpioPackContPowerEn m0 : 7|1@1+ (1,0) [0|1] ""  Receiver
 SG_ HVP_gpioPackCoontPosFlywheel m0 : 20|1@1+ (1,0) [0|1] ""  Receiver
 SG_ HVP_gpioPassivePyroDepl m0 : 4|1@1+ (1,0) [0|1] ""  Receiver
 SG_ HVP_gpioPcsChargePwmEnable m0 : 24|1@1+ (1,0) [0|1] ""  Receiver
 SG_ HVP_gpioPcsDcdcPwmEnable m0 : 23|1@1+ (1,0) [0|1] ""  Receiver
 SG_ HVP_gpioPcsEnable m0 : 22|1@1+ (1,0) [0|1] ""  Receiver
 SG_ HVP_gpioPyroIsoEn m0 : 5|1@1+ (1,0) [0|1] ""  Receiver
 SG_ HVP_gpioPyroPor m0 : 17|1@1+ (1,0) [0|1] ""  Receiver
 SG_ HVP_gpioSecDrdy m0 : 27|1@1+ (1,0) [0|1] ""  Receiver
 SG_ HVP_gpioShuntDataReady m0 : 12|1@1+ (1,0) [0|1] ""  Receiver
 SG_ HVP_gpioShuntEn m0 : 18|1@1+ (1,0) [0|1] ""  Receiver
 SG_ HVP_hvilInVoltage m4 : 28|12@1+ (0.1,0) [0|30] "V"  Receiver
 SG_ HVP_hvilOutVoltage m4 : 40|12@1+ (0.1,0) [0|30] "V"  Receiver
 SG_ HVP_hvp1v5Ref m0 : 28|12@1+ (0.1,0) [0|3] "V"  Receiver
 SG_ HVP_packContCoilCurrent m5 : 24|12@1+ (0.1,0) [0|7.5] "A"  Receiver
 SG_ HVP_packContVoltage m2 : 4|12@1+ (0.1,0) [0|30] "V"  Receiver
 SG_ HVP_packCurrentMia m0 : 56|1@1+ (1,0) [0|1] ""  Receiver
 SG_ HVP_packNegativeV m2 : 16|16@1- (0.1,0) [-550|550] "V"  Receiver
 SG_ HVP_packPositiveV m2 : 32|16@1- (0.1,0) [-550|550] "V"  Receiver
 SG_ HVP_packVoltage m1 : 24|16@1- (0.1,0) [-3276.8|3276.7] "V"  Receiver
 SG_ HVP_pyroAnalog m2 : 48|12@1+ (0.1,0) [0|3] "V"  Receiver
 SG_ HVP_shuntAsicTempDbg m6 : 40|16@1- (0.01,0) [-327.67|327.67] "C"  Receiver
 SG_ HVP_shuntAsicTempStatus m6 : 60|2@1+ (1,0) [0|3] ""  Receiver
 SG_ HVP_shuntAuxCurrentDbg m6 : 8|16@1- (0.1,0) [-3276.8|3276.7] "A"  Receiver
 SG_ HVP_shuntAuxCurrentStatus m6 : 56|2@1+ (1,0) [0|3] ""  Receiver
 SG_ HVP_shuntBarTempDbg m6 : 24|16@1- (0.01,0) [-327.67|327.67] "C"  Receiver
 SG_ HVP_shuntBarTempStatus m6 : 58|2@1+ (1,0) [0|3] ""  Receiver
 SG_ HVP_shuntCurrentDebug m0 : 40|16@1- (0.1,0) [-3276.8|3276.7] "A"  Receiver
 SG_ HVP_shuntHwMia m0 : 61|1@1+ (1,0) [0|1] ""  Receiver
 SG_ HVP_shuntRefVoltageDbg m5 : 48|16@1- (0.001,0) [-32.768|32.767] "V"  Receiver
 SG_ HVP_shuntRefVoltageMismatch m0 : 59|1@1+ (1,0) [0|1] ""  Receiver
 SG_ HVP_shuntThermistorMia m0 : 60|1@1+ (1,0) [0|1] ""  Receiver

BO_ 784 HVP_info: 8 VEH
 SG_ HVP_infoIndex M : 0|8@1+ (1,0) [0|0] ""  X
 SG_ HVP_buildType m10 : 8|3@1+ (1,0) [0|0] ""  X
 SG_ HVP_buildConfigId m10 : 16|16@1+ (1,0) [0|0] ""  X
 SG_ HVP_hardwareId m10 : 32|16@1+ (1,0) [0|0] ""  X
 SG_ HVP_componentId m10 : 48|16@1+ (1,0) [0|0] ""  X
 SG_ HVP_pcbaId m11 : 16|8@1+ (1,0) [0|0] ""  X
 SG_ HVP_assemblyId m11 : 24|8@1+ (1,0) [0|0] ""  X
 SG_ HVP_usageId m11 : 32|16@1+ (1,0) [0|0] ""  X
 SG_ HVP_subUsageId m11 : 48|16@1+ (1,0) [0|0] ""  X
 SG_ HVP_platformType m13 : 8|8@1+ (1,0) [0|0] ""  X
 SG_ HVP_appCrc m13 : 32|32@1+ (1,0) [0|0] ""  X
 SG_ HVP_appGitHash m17 : 10|54@1+ (4,0) [0|0] ""  X
 SG_ HVP_bootGitHash m18 : 10|54@1+ (4,0) [0|0] ""  X
 SG_ HVP_bootUdsProtoVersion m20 : 8|8@1+ (1,0) [0|0] ""  X
 SG_ HVP_bootCrc m20 : 32|32@1+ (1,0) [0|0] ""  X

BO_ 1898 HVP_vehicleDbg: 8 VEH
 SG_ HVP_ecuLogUploadRequest : 5|2@1+ (1,0) [0|0] ""  X
 SG_ HVP_vehicleDebugMultiplexer M : 0|5@1+ (1,0) [0|0] ""  X
 SG_ HVP_packNegativeContPwmDuty m0 : 8|14@1+ (0.01,0) [0|0] "%"  X
 SG_ HVP_packPositiveContPwmDuty m0 : 22|14@1+ (0.01,0) [0|0] "%"  X
 SG_ HVP_FcPositiveContPwmDuty m0 : 36|14@1+ (0.01,0) [0|0] "%"  X
 SG_ HVP_FcNegativeContPwmDuty m0 : 50|14@1+ (0.01,0) [0|0] "%"  X
 SG_ HVP_maxRobinBrickV m1 : 8|16@1- (0.001,0) [0|0] "V"  X
 SG_ HVP_maxRobinBrickId m1 : 24|7@1+ (1,1) [0|0] ""  X
 SG_ HVP_minRobinBrickV m1 : 32|16@1- (0.001,0) [0|0] "V"  X
 SG_ HVP_minRobinBrickId m1 : 48|7@1+ (1,1) [0|0] ""  X
 SG_ HVP_avgRobinBrickV m2 : 8|16@1- (0.001,0) [0|0] "V"  X

BA_DEF_ BO_  "GenMsgSendType" ENUM  "Cyclic";
BA_DEF_ BO_  "GenMsgCycleTime" INT 0 10000;
BA_DEF_ SG_  "SystemSignalLongSymbol" STRING ;
BA_DEF_DEF_  "GenMsgSendType" "";
BA_DEF_DEF_  "GenMsgCycleTime" 0;
BA_DEF_DEF_  "SystemSignalLongSymbol" "";
BA_ "GenMsgSendType" BO_ 965 0;
BA_ "GenMsgCycleTime" BO_ 965 1000;
BA_ "GenMsgSendType" BO_ 997 0;
BA_ "GenMsgCycleTime" BO_ 997 1000;
BA_ "GenMsgSendType" BO_ 392 0;
BA_ "GenMsgCycleTime" BO_ 392 10;
BA_ "GenMsgSendType" BO_ 821 0;
BA_ "GenMsgCycleTime" BO_ 821 1000;
BA_ "GenMsgSendType" BO_ 741 0;
BA_ "GenMsgCycleTime" BO_ 741 10;
BA_ "GenMsgSendType" BO_ 390 0;
BA_ "GenMsgCycleTime" BO_ 390 10;
BA_ "GenMsgSendType" BO_ 854 0;
BA_ "GenMsgCycleTime" BO_ 854 1000;
BA_ "GenMsgSendType" BO_ 855 0;
BA_ "GenMsgCycleTime" BO_ 855 1000;
BA_ "GenMsgSendType" BO_ 858 0;
BA_ "GenMsgCycleTime" BO_ 858 1000;
BA_ "GenMsgSendType" BO_ 859 0;
BA_ "GenMsgCycleTime" BO_ 859 1000;
BA_ "GenMsgSendType" BO_ 694 0;
BA_ "GenMsgCycleTime" BO_ 694 100;
BA_ "GenMsgSendType" BO_ 1879 0;
BA_ "GenMsgCycleTime" BO_ 1879 100;
BA_ "GenMsgSendType" BO_ 1880 0;
BA_ "GenMsgCycleTime" BO_ 1880 10;
BA_ "GenMsgSendType" BO_ 1022 0;
BA_ "GenMsgCycleTime" BO_ 1022 1000;
BA_ "GenMsgSendType" BO_ 1622 0;
BA_ "GenMsgCycleTime" BO_ 1622 1000;
BA_ "GenMsgSendType" BO_ 646 0;
BA_ "GenMsgCycleTime" BO_ 646 100;
BA_ "GenMsgSendType" BO_ 822 0;
BA_ "GenMsgCycleTime" BO_ 822 1000;
BA_ "GenMsgSendType" BO_ 950 0;
BA_ "GenMsgCycleTime" BO_ 950 1000;
BA_ "GenMsgSendType" BO_ 917 0;
BA_ "GenMsgCycleTime" BO_ 917 100;
BA_ "GenMsgSendType" BO_ 918 0;
BA_ "GenMsgCycleTime" BO_ 918 100;
BA_ "GenMsgSendType" BO_ 614 0;
BA_ "GenMsgCycleTime" BO_ 614 10;
BA_ "GenMsgSendType" BO_ 599 0;
BA_ "GenMsgCycleTime" BO_ 599 20;
BA_ "GenMsgSendType" BO_ 616 0;
BA_ "GenMsgCycleTime" BO_ 616 100;
BA_ "GenMsgSendType" BO_ 280 0;
BA_ "GenMsgCycleTime" BO_ 280 10;
BA_ "GenMsgSendType" BO_ 789 0;
BA_ "GenMsgCycleTime" BO_ 789 1000;
BA_ "GenMsgSendType" BO_ 886 0;
BA_ "GenMsgCycleTime" BO_ 886 1000;
BA_ "GenMsgSendType" BO_ 1367 0;
BA_ "GenMsgCycleTime" BO_ 1367 1000;
BA_ "GenMsgSendType" BO_ 264 0;
BA_ "GenMsgCycleTime" BO_ 264 10;
BA_ "GenMsgSendType" BO_ 914 0;
BA_ "GenMsgCycleTime" BO_ 914 1000;
BA_ "GenMsgSendType" BO_ 817 0;
BA_ "GenMsgCycleTime" BO_ 817 1000;
BA_ "GenMsgSendType" BO_ 883 0;
BA_ "GenMsgCycleTime" BO_ 883 10;
BA_ "GenMsgSendType" BO_ 913 0;
BA_ "GenMsgCycleTime" BO_ 913 1000;
BA_ "GenMsgSendType" BO_ 785 0;
BA_ "GenMsgCycleTime" BO_ 785 1000;
BA_ "GenMsgSendType" BO_ 882 0;
BA_ "GenMsgCycleTime" BO_ 882 10;
BA_ "GenMsgSendType" BO_ 968 0;
BA_ "GenMsgCycleTime" BO_ 968 100;
BA_ "GenMsgSendType" BO_ 1992 0;
BA_ "GenMsgCycleTime" BO_ 1992 1000;
BA_ "GenMsgSendType" BO_ 648 0;
BA_ "GenMsgCycleTime" BO_ 648 100;
BA_ "GenMsgSendType" BO_ 681 0;
BA_ "GenMsgCycleTime" BO_ 681 100;
BA_ "GenMsgSendType" BO_ 1000 0;
BA_ "GenMsgCycleTime" BO_ 1000 100;
BA_ "GenMsgSendType" BO_ 2024 0;
BA_ "GenMsgCycleTime" BO_ 2024 1000;
BA_ "GenMsgSendType" BO_ 552 0;
BA_ "GenMsgCycleTime" BO_ 552 100;
BA_ "GenMsgSendType" BO_ 744 0;
BA_ "GenMsgCycleTime" BO_ 744 100;
BA_ "GenMsgSendType" BO_ 981 0;
BA_ "GenMsgCycleTime" BO_ 981 1000;
BA_ "GenMsgSendType" BO_ 808 0;
BA_ "GenMsgCycleTime" BO_ 808 10000;
BA_ "GenMsgSendType" BO_ 325 0;
BA_ "GenMsgCycleTime" BO_ 325 20;
BA_ "GenMsgSendType" BO_ 805 0;
BA_ "GenMsgCycleTime" BO_ 805 1000;
BA_ "GenMsgSendType" BO_ 831 0;
BA_ "GenMsgCycleTime" BO_ 831 1000;
BA_ "GenMsgSendType" BO_ 895 0;
BA_ "GenMsgCycleTime" BO_ 895 1000;
BA_ "GenMsgSendType" BO_ 927 0;
BA_ "GenMsgCycleTime" BO_ 927 1000;
BA_ "GenMsgSendType" BO_ 958 0;
BA_ "GenMsgCycleTime" BO_ 958 1000;
BA_ "GenMsgSendType" BO_ 990 0;
BA_ "GenMsgCycleTime" BO_ 990 1000;
BA_ "GenMsgSendType" BO_ 1303 0;
BA_ "GenMsgCycleTime" BO_ 1303 1000;
BA_ "GenMsgSendType" BO_ 1310 0;
BA_ "GenMsgCycleTime" BO_ 1310 1000;
BA_ "GenMsgSendType" BO_ 580 0;
BA_ "GenMsgCycleTime" BO_ 580 100;
BA_ "GenMsgSendType" BO_ 1345 0;
BA_ "GenMsgCycleTime" BO_ 1345 100;
BA_ "GenMsgSendType" BO_ 532 0;
BA_ "GenMsgCycleTime" BO_ 532 100;
BA_ "GenMsgSendType" BO_ 533 0;
BA_ "GenMsgCycleTime" BO_ 533 1000;
BA_ "GenMsgSendType" BO_ 535 0;
BA_ "GenMsgCycleTime" BO_ 535 1000;
BA_ "GenMsgSendType" BO_ 888 0;
BA_ "GenMsgCycleTime" BO_ 888 1000;
BA_ "GenMsgSendType" BO_ 274 0;
BA_ "GenMsgCycleTime" BO_ 274 1000;
BA_ "GenMsgSendType" BO_ 275 0;
BA_ "GenMsgCycleTime" BO_ 275 1000;
BA_ "GenMsgSendType" BO_ 276 0;
BA_ "GenMsgCycleTime" BO_ 276 1000;
BA_ "GenMsgSendType" BO_ 62 0;
BA_ "GenMsgCycleTime" BO_ 62 1000;
BA_ "GenMsgSendType" BO_ 281 0;
BA_ "GenMsgCycleTime" BO_ 281 2000;
BA_ "GenMsgSendType" BO_ 904 0;
BA_ "GenMsgCycleTime" BO_ 904 1000;
BA_ "GenMsgSendType" BO_ 2047 0;
BA_ "GenMsgCycleTime" BO_ 2047 100;
BA_ "GenMsgSendType" BO_ 1080 0;
BA_ "GenMsgCycleTime" BO_ 1080 100;
BA_ "GenMsgSendType" BO_ 1376 0;
BA_ "GenMsgCycleTime" BO_ 1376 1000;
BA_ "GenMsgSendType" BO_ 2033 0;
BA_ "GenMsgCycleTime" BO_ 2033 2000;
BA_ "GenMsgSendType" BO_ 60 0;
BA_ "GenMsgCycleTime" BO_ 60 2000;
BA_ "GenMsgSendType" BO_ 840 0;
BA_ "GenMsgCycleTime" BO_ 840 1000;
BA_ "GenMsgSendType" BO_ 872 0;
BA_ "GenMsgCycleTime" BO_ 872 1000;
BA_ "GenMsgSendType" BO_ 1112 0;
BA_ "GenMsgCycleTime" BO_ 1112 100;
BA_ "GenMsgSendType" BO_ 938 0;
BA_ "GenMsgCycleTime" BO_ 938 1000;
BA_ "GenMsgSendType" BO_ 522 0;
BA_ "GenMsgCycleTime" BO_ 522 10;
BA_ "GenMsgSendType" BO_ 1962 0;
BA_ "GenMsgCycleTime" BO_ 1962 1000;
BA_ "GenMsgSendType" BO_ 784 0;
BA_ "GenMsgCycleTime" BO_ 784 10000;
BA_ "GenMsgSendType" BO_ 1898 0;
BA_ "GenMsgCycleTime" BO_ 1898 300;
BA_ "SystemSignalLongSymbol" SG_ 859 DI_a200_vdcModelBasedPlausibilit "DI_a200_vdcModelBasedPlausibility";
BA_ "SystemSignalLongSymbol" SG_ 859 DI_a232_velocityEstimatorDegrade "DI_a232_velocityEstimatorDegraded";
BA_ "SystemSignalLongSymbol" SG_ 918 DI_frontOilPumpCurrentSensorOffs "DI_frontOilPumpCurrentSensorOffset";
BA_ "SystemSignalLongSymbol" SG_ 62 GTW_w093_sdCardInvReqOverflowBas "GTW_w093_sdCardInvReqOverflowBase";
BA_ "SystemSignalLongSymbol" SG_ 62 GTW_w094_sdCardInvReqOverflowCou "GTW_w094_sdCardInvReqOverflowCount";
BA_ "SystemSignalLongSymbol" SG_ 62 GTW_w104_sdCardDriverArgCorrupte "GTW_w104_sdCardDriverArgCorrupted";
VAL_ 821 DIS_infoIndex 0 "DEPRECATED_0" 1 "DEPRECATED_1" 2 "DEPRECATED_2" 3 "DEPRECATED_3" 4 "DEPRECATED_4" 5 "DEPRECATED_5" 6 "DEPRECATED_6" 7 "DEPRECATED_7" 8 "DEPRECATED_8" 9 "DEPRECATED_9" 10 "BUILD_HWID_COMPONENTID" 11 "PCBAID_ASSYID_USAGEID" 13 "APP_CRC" 14 "BOOTLOADER_SVN" 15 "BOOTLOADER_CRC" 16 "SUBCOMPONENT" 17 "APP_GITHASH" 18 "BOOTLOADER_GITHASH" 19 "VERSION_DEPRECATED" 20 "UDS_PROTOCOL_BOOTCRC" 22 "VARIANTCRC" 25 "PACKAGE_PN_1_7" 26 "PACKAGE_PN_8_14" 27 "PACKAGE_PN_15_20" 29 "PACKAGE_SN_1_7" 30 "PACKAGE_SN_8_14" 31 "SUBCOMPONENT_GITHASH" 255 "END" ;
VAL_ 821 DIS_buildType 0 "UNKNOWN_BUILD" 1 "PLATFORM_BUILD" 2 "LOCAL_BUILD" 3 "TRACEABLE_CI_BUILD" 4 "MFG_BUILD" ;
VAL_ 821 DIS_hardwareId 252 "CONFIGURABLE_HWID_PLACEHOLDER" ;
VAL_ 821 DIS_oilPumpBuildType 0 "UNKNOWN_BUILD" 1 "PLATFORM_BUILD" 2 "LOCAL_BUILD" 3 "TRACEABLE_CI_BUILD" 4 "MFG_BUILD" ;
VAL_ 741 DIS_drivePowerMax 511 "SNA" ;
VAL_ 741 DIS_elecPower -1024 "DIS_elecPower_SNA" ;
VAL_ 390 DIS_frontTorqueCommand -4096 "SNA" ;
VAL_ 390 DIS_frontTorqueActual -4096 "SNA" ;
VAL_ 390 DIS_frontAxleSpeed -32768 "SNA" ;
VAL_ 472 DIS_torqueCommand -4096 "SNA" ;
VAL_ 472 DIS_torqueActual -4096 "SNA" ;
VAL_ 472 DIS_axleSpeed -32768 "SNA" ;
VAL_ 694 DI_btcStateUI 0 "OFF" 1 "ON" ;
VAL_ 694 DI_ptcStateUI 0 "FAULTED" 1 "BACKUP" 2 "ON" 3 "SNA" ;
VAL_ 694 DI_tcTelltaleFlash 0 "OFF" 1 "ON" ;
VAL_ 694 DI_tcTelltaleOn 0 "OFF" 1 "ON" ;
VAL_ 694 DI_tractionControlModeUI 0 "NORMAL" 1 "SLIP_START" 2 "DEV_MODE_1" 3 "DEV_MODE_2" 4 "ROLLS_MODE" 5 "DYNO_MODE" ;
VAL_ 694 DI_vdcTelltaleFlash 0 "OFF" 1 "ON" ;
VAL_ 694 DI_vdcTelltaleOn 0 "OFF" 1 "ON" ;
VAL_ 2005 DI_motorType 0 "SNA" 1 "ROADSTER_BASE" 2 "ROADSTER_SPORT" 3 "M7M3" 4 "M7M4" 5 "M7M5" 6 "M8A" 7 "M7M6" 8 "F1A" 9 "SSR1A" 10 "F1AC" 11 "F2AB" 12 "F2AC" 13 "F2AD" 14 "F2AE" 15 "F2APMSRM" 16 "PM216A" 17 "IM100A" 18 "PM216B" 19 "IM100B" 20 "IM216A" 21 "PM216C" 22 "IM130C" 23 "PM216D" 24 "IM130D" 25 "IM130D_AL" ;
VAL_ 2005 DI_ssmState 0 "START" 1 "UNAVAILABLE" 2 "IDLE" 3 "STANDBY" 4 "ENABLE" 5 "ABORT" 6 "WAIT_FOR_RETRY" 7 "RETRY" 8 "FAULT" ;
VAL_ 2005 DI_usmState 0 "START" 1 "STANDBY" 2 "RETRY" 3 "ABORT" 4 "ENABLE" 5 "FAULT" 6 "UNAVAILABLE" 7 "WAIT_FOR_RETRY" ;
VAL_ 2005 DI_tcMaxRequest 255 "SNA" ;
VAL_ 2005 DI_tcMinRequest 255 "SNA" ;
VAL_ 2005 DI_fluxState 0 "START" 1 "TEST" 2 "STANDBY" 3 "FLUX_UP" 4 "FLUX_DOWN" 5 "ENABLED" 6 "ICONTROL" 7 "VCONTROL" 9 "FAULT" ;
VAL_ 2005 DI_aebFaultReason 0 "NONE" 1 "EPB_MIA" 2 "PM_MIA" 3 "EBR_FAULT" 4 "SPEED_DELTA" 5 "DAS_CONTROL_MIA" 6 "DAS_SNA" 7 "VEL_EST_ABNORMAL" 8 "PM_REQUEST" 9 "ACCEL_OUT_OF_BOUNDS" 10 "EPB_NOT_PARKED" 11 "ESP_FAULT" 12 "ESP_MIA" 13 "MIN_TIME_BTWN_EVENTS" 14 "ACCEL_REQ_INVALID" 15 "DAS_REQ_DI_UNAVAIL" ;
VAL_ 2005 DI_aebUnavailableReason 0 "NONE" 1 "CLOSURE" 2 "GEAR" 3 "SKID" 4 "NEGATIVE_SPEED" 5 "DI_STATE" 6 "EBR_UNAVAILABLE" 7 "EPB" 8 "HYSTERESIS" ;
VAL_ 2005 DI_oilPumpPhaseCurrent 255 "SNA" ;
VAL_ 2005 DI_oilPumpPhaseVoltage 255 "SNA" ;
VAL_ 2005 DI_oilPumpPhaseAdvance 255 "SNA" ;
VAL_ 2005 DI_oilPumpPressureEstimate 255 "SNA" ;
VAL_ 2005 DI_magnetTempEst 0 "SNA" ;
VAL_ 2005 DI_magnetTempEst_SFO 0 "SNA" ;
VAL_ 2005 DI_gateDriveSupplyState 0 "DOWN" 1 "RISING" 2 "UP" 3 "FALLING" ;
VAL_ 2005 DI_gateDriveState 0 "INIT" 1 "SELFTEST" 2 "CONFIGURING" 3 "CONFIGURED" 4 "NOT_CONFIGURED" ;
VAL_ 2005 DI_powerStageSafeState 0 "NONE" 1 "ALL_OFF" 2 "3PS_HIGH" 3 "3PS_LOW" ;
VAL_ 2005 DI_brkStState 0 "UNAVAILABLE" 1 "IDLE" 2 "RUNNING_UNPRESSED" 3 "RUNNING_PRESSING" 4 "RUNNING_PRESSED" 5 "INTERRUPTED" 6 "FINISHED" ;
VAL_ 2005 DI_immobilizerCondition 0 "VIRGIN_SNA" 1 "LEARNED" ;
VAL_ 2005 DI_velocityEstimatorState 0 "NOT_INITIALIZED" 1 "WHEELS_NORMAL" 2 "BACKUP_WHEELS_A" 3 "BACKUP_WHEELS_B" 4 "BACKUP_MOTOR" ;
VAL_ 1879 DIF_fluxState 5 "DI_FLUXSTATE_ENABLED" 9 "DI_FLUXSTATE_FAULT" 4 "DI_FLUXSTATE_FLUX_DOWN" 3 "DI_FLUXSTATE_FLUX_UP" 6 "DI_FLUXSTATE_ICONTROL" 2 "DI_FLUXSTATE_STANDBY" 0 "DI_FLUXSTATE_START" 10 "DI_FLUXSTATE_STATIONARY_WASTE" 1 "DI_FLUXSTATE_TEST" 7 "DI_FLUXSTATE_VCONTROL" ;
VAL_ 1879 DIF_gateDriveState 3 "PSTG_GD_STATE_CONFIGURED" 2 "PSTG_GD_STATE_CONFIGURING" 0 "PSTG_GD_STATE_INIT" 4 "PSTG_GD_STATE_NOT_CONFIGURED" 1 "PSTG_GD_STATE_SELFTEST" ;
VAL_ 1879 DIF_gateDriveSupplyState 0 "PSTG_GD_SUPPLY_DOWN" 3 "PSTG_GD_SUPPLY_FALLING" 1 "PSTG_GD_SUPPLY_RISING" 2 "PSTG_GD_SUPPLY_UP" ;
VAL_ 1879 DIF_magnetTempEst 0 "SNA" ;
VAL_ 1879 DIF_motorType 8 "DI_MOTOR_F1A" 10 "DI_MOTOR_F1AC" 11 "DI_MOTOR_F2AB" 12 "DI_MOTOR_F2AC" 13 "DI_MOTOR_F2AD" 14 "DI_MOTOR_F2AE" 26 "DI_MOTOR_F2AE_AL" 15 "DI_MOTOR_F2APMSRM" 17 "DI_MOTOR_IM100A" 19 "DI_MOTOR_IM100B" 22 "DI_MOTOR_IM130C" 24 "DI_MOTOR_IM130D" 25 "DI_MOTOR_IM130D_AL" 27 "DI_MOTOR_IM130D_AL_POSCO" 20 "DI_MOTOR_IM216A" 3 "DI_MOTOR_M7M3" 4 "DI_MOTOR_M7M4" 5 "DI_MOTOR_M7M5" 7 "DI_MOTOR_M7M6" 6 "DI_MOTOR_M8A" 16 "DI_MOTOR_PM216A" 18 "DI_MOTOR_PM216B" 21 "DI_MOTOR_PM216C" 30 "DI_MOTOR_PM216CSR" 31 "DI_MOTOR_PM216CSR_N42" 23 "DI_MOTOR_PM216D" 32 "DI_MOTOR_PM228B" 28 "DI_MOTOR_PM275B" 29 "DI_MOTOR_PM350B" 1 "DI_MOTOR_ROADSTER_BASE" 2 "DI_MOTOR_ROADSTER_SPORT" 0 "DI_MOTOR_SNA" 9 "DI_MOTOR_SSR1A" ;
VAL_ 1879 DIF_oilPumpPhaseVoltage 255 "SNA" ;
VAL_ 1879 DIF_oilPumpPressureEstimateMax 255 "SNA" ;
VAL_ 1879 DIF_oilPumpPressureExpectedMin 255 "SNA" ;
VAL_ 1879 DIF_powerStageSafeState 2 "PSTG_SAFESTATE_3PS_HIGH" 3 "PSTG_SAFESTATE_3PS_LOW" 1 "PSTG_SAFESTATE_ALL_OFF" 0 "PSTG_SAFESTATE_NONE" ;
VAL_ 1879 DIF_pwmState 1 "PWMSTATE_DPWM2" 2 "PWMSTATE_OPWM1" 3 "PWMSTATE_OPWM2" 0 "PWMSTATE_SVPWM" ;
VAL_ 1879 DIF_rotorOffsetLearningState 9 "ROL_NUM_STATES" 2 "ROL_STATE_ACCELERATE" 5 "ROL_STATE_CORRECT" 8 "ROL_STATE_DONE" 0 "ROL_STATE_INIT" 4 "ROL_STATE_MEASURE" 3 "ROL_STATE_SHIFT" 6 "ROL_STATE_VERIFY" 1 "ROL_STATE_WAIT" 7 "ROL_STATE_WRITE" ;
VAL_ 1879 DIF_ssmState 5 "SSM_STATE_ABORT" 4 "SSM_STATE_ENABLE" 8 "SSM_STATE_FAULT" 2 "SSM_STATE_IDLE" 7 "SSM_STATE_RETRY" 3 "SSM_STATE_STANDBY" 0 "SSM_STATE_START" 1 "SSM_STATE_UNAVAILABLE" 6 "SSM_STATE_WAIT_FOR_RETRY" ;
VAL_ 1879 DIF_tcMaxRequest 255 "SNA" ;
VAL_ 1879 DIF_tcMinRequest 255 "SNA" ;
VAL_ 1879 DIF_usmState 3 "USM_STATE_ABORT" 4 "USM_STATE_ENABLE" 5 "USM_STATE_FAULT" 2 "USM_STATE_RETRY" 1 "USM_STATE_STANDBY" 0 "USM_STATE_START" 6 "USM_STATE_UNAVAILABLE" 7 "USM_STATE_WAIT_FOR_RETRY" ;
VAL_ 1880 DI_dynoSelector 0 "Mux0" 1 "Mux1" 2 "Mux2" 32 "Mux32" 33 "Mux33" 64 "Mux64" ;
VAL_ 1880 DI_state 0 "UNAVAILABLE" 1 "STANDBY" 2 "FAULT" 3 "ABORT" 4 "ENABLE" ;
VAL_ 1022 DI_brakeFLTemp 1023 "SNA" ;
VAL_ 1022 DI_brakeFRTemp 1023 "SNA" ;
VAL_ 1022 DI_brakeRLTemp 1023 "SNA" ;
VAL_ 1022 DI_brakeRRTemp 1023 "SNA" ;
VAL_ 1622 DI_infoIndex 0 "DEPRECATED_0" 1 "DEPRECATED_1" 2 "DEPRECATED_2" 3 "DEPRECATED_3" 4 "DEPRECATED_4" 5 "DEPRECATED_5" 6 "DEPRECATED_6" 7 "DEPRECATED_7" 8 "DEPRECATED_8" 9 "DEPRECATED_9" 10 "BUILD_HWID_COMPONENTID" 11 "PCBAID_ASSYID_USAGEID" 13 "APP_CRC" 14 "BOOTLOADER_SVN" 15 "BOOTLOADER_CRC" 16 "SUBCOMPONENT" 17 "APP_GITHASH" 18 "BOOTLOADER_GITHASH" 19 "VERSION_DEPRECATED" 20 "UDS_PROTOCOL_BOOTCRC" 22 "VARIANTCRC" 25 "PACKAGE_PN_1_7" 26 "PACKAGE_PN_8_14" 27 "PACKAGE_PN_15_20" 29 "PACKAGE_SN_1_7" 30 "PACKAGE_SN_8_14" 31 "SUBCOMPONENT_GITHASH" 255 "END" ;
VAL_ 1622 DI_buildType 0 "UNKNOWN_BUILD" 1 "PLATFORM_BUILD" 2 "LOCAL_BUILD" 3 "TRACEABLE_CI_BUILD" 4 "MFG_BUILD" ;
VAL_ 1622 DI_hardwareId 252 "CONFIGURABLE_HWID_PLACEHOLDER" ;
VAL_ 1622 DI_oilPumpBuildType 0 "UNKNOWN_BUILD" 1 "PLATFORM_BUILD" 2 "LOCAL_BUILD" 3 "TRACEABLE_CI_BUILD" 4 "MFG_BUILD" ;
VAL_ 646 DI_aebState 0 "UNAVAILABLE" 1 "STANDBY" 2 "ENABLED" 3 "STANDSTILL" 4 "FAULT" 7 "SNA" ;
VAL_ 646 DI_autoparkState 0 "UNAVAILABLE" 1 "STANDBY" 2 "STARTED" 3 "ACTIVE" 4 "COMPLETE" 5 "PAUSED" 6 "ABORTED" 7 "RESUMED" 8 "UNPARK_COMPLETE" 9 "SELFPARK_STARTED" 15 "SNA" ;
VAL_ 646 DI_autopilotRequest 0 "IDLE" 1 "ACTIVATE" ;
VAL_ 646 DI_cruiseSetSpeedUnits 0 "MPH" 1 "KPH" ;
VAL_ 646 DI_cruiseState 0 "UNAVAILABLE" 1 "STANDBY" 2 "ENABLED" 3 "STANDSTILL" 4 "OVERRIDE" 5 "FAULT" 6 "PRE_FAULT" 7 "PRE_CANCEL" ;
VAL_ 646 DI_parkBrakeState 0 "UNAVAILABLE" 1 "RELEASED" 2 "REQUESTED" 3 "APPLIED" 4 "FAULTED" 5 "PANIC_EPB" 6 "PANIC_SKID" 7 "RELEASING" 15 "SNA" ;
VAL_ 646 DI_pmmStatus 0 "INACTIVE" 1 "ACTIVE" 2 "LOGGING_ACTIVE" 3 "SNA" ;
VAL_ 646 DI_rollPreventionState 0 "UNAVAILABLE" 1 "STANDBY" 2 "READY" 3 "BUILD" 4 "HOLD" 5 "PARK" 6 "FAULT" 7 "INIT" ;
VAL_ 646 DI_vehicleHoldState 0 "UNAVAILABLE" 1 "STANDBY" 2 "BLEND_IN" 3 "STANDSTILL" 4 "BLEND_OUT" 5 "PARK" 6 "FAULT" 7 "INIT" ;
VAL_ 822 DI_sysDrivePowerRated 511 "SNA" ;
VAL_ 822 DI_sysRegenPowerRated 255 "SNA" ;
VAL_ 950 DI_odometer -2147483648 "SNA" ;
VAL_ 917 DI_oilPumpState 0 "STANDBY" 1 "ENABLE" 2 "COLD_STARTUP" 6 "FAULTED" 7 "SNA" ;
VAL_ 917 DI_oilPumpFlowTarget 255 "SNA" ;
VAL_ 917 DI_oilPumpFlowActual 255 "SNA" ;
VAL_ 917 DI_oilPumpPcbT 255 "SNA" ;
VAL_ 917 DI_oilPumpFluidT 255 "SNA" ;
VAL_ 917 DI_oilPumpVoltage 255 "SNA" ;
VAL_ 917 DI_oilPumpCurrent 255 "SNA" ;
VAL_ 917 DI_oilPumpCurrentSensorOffset 255 "SNA" ;
VAL_ 918 DI_frontOilPumpCurrent 255 "SNA" ;
VAL_ 918 DI_frontOilPumpCurrentSensorOffs 255 "SNA" ;
VAL_ 918 DI_frontOilPumpFlowActual 255 "SNA" ;
VAL_ 918 DI_frontOilPumpFlowTarget 255 "SNA" ;
VAL_ 918 DI_frontOilPumpFluidT 255 "SNA" ;
VAL_ 918 DI_frontOilPumpPcbT 255 "SNA" ;
VAL_ 918 DI_frontOilPumpState 0 "STANDBY" 1 "ENABLE" 2 "COLD_STARTUP" 6 "FAULTED" 7 "SNA" ;
VAL_ 918 DI_frontOilPumpVoltage 255 "SNA" ;
VAL_ 614 DI_elecPower -1024 "SNA" ;
VAL_ 599 DI_uiSpeed 255 "SNA" ;
VAL_ 599 DI_uiSpeedUnits 0 "MPH" 1 "KPH" ;
VAL_ 599 DI_vehicleSpeed 4095 "SNA" ;
VAL_ 616 DI_sysDrivePowerMax 511 "SNA" ;
VAL_ 616 DI_sysRegenPowerMax 155 "SNA" ;
VAL_ 280 DI_accelPedalPos 255 "SNA" ;
VAL_ 280 DI_brakePedalState 0 "OFF" 1 "ON" 2 "INVALID" ;
VAL_ 280 DI_epbRequest 0 "NO_REQUEST" 1 "PARK" 2 "UNPARK" ;
VAL_ 280 DI_gear 0 "INVALID" 1 "P" 2 "R" 3 "N" 4 "D" 7 "SNA" ;
VAL_ 280 DI_immobilizerState 0 "INIT_SNA" 1 "REQUEST" 2 "AUTHENTICATING" 3 "DISARMED" 4 "IDLE" 5 "RESET" 6 "FAULT" ;
VAL_ 280 DI_keepAliveRequest 0 "NO_REQUEST" 1 "KEEP_ALIVE" ;
VAL_ 280 DI_systemState 0 "UNAVAILABLE" 1 "IDLE" 2 "STANDBY" 3 "FAULT" 4 "ABORT" 5 "ENABLE" ;
VAL_ 280 DI_trackModeState 0 "UNAVAILABLE" 1 "AVAILABLE" 2 "ON" ;
VAL_ 280 DI_tractionControlMode 0 "NORMAL" 1 "SLIP_START" 2 "DEV_MODE_1" 3 "DEV_MODE_2" 4 "ROLLS_MODE" 5 "DYNO_MODE" ;
VAL_ 789 DI_inverterTQF 0 "INIT" 1 "IRRATIONAL" 2 "RATIONAL" 3 "UNKNOWN" ;
VAL_ 886 DI_frontInverterTQF 0 "INIT" 1 "IRRATIONAL" 2 "RATIONAL" 3 "UNKNOWN" ;
VAL_ 264 DI_axleSpeed -32768 "SNA" ;
VAL_ 264 DI_torqueActual -4096 "SNA" ;
VAL_ 264 DI_torqueCommand -4096 "SNA" ;
VAL_ 264 DI_slavePedalPos 255 "SNA" ;
VAL_ 914 EPAS3P_matrixIndex 0 "AlertMatrix0" 1 "AlertMatrix1" 2 "AlertMatrix2" ;
VAL_ 817 EPAS3P_infoIndex 0 "DEPRECATED_0" 1 "DEPRECATED_1" 2 "DEPRECATED_2" 3 "DEPRECATED_3" 4 "DEPRECATED_4" 5 "DEPRECATED_5" 6 "DEPRECATED_6" 7 "DEPRECATED_7" 8 "DEPRECATED_8" 9 "DEPRECATED_9" 10 "BUILD_HWID_COMPONENTID" 11 "PCBAID_ASSYID_USAGEID" 13 "APP_CRC" 14 "BOOTLOADER_SVN" 15 "BOOTLOADER_CRC" 16 "SUBCOMPONENT" 17 "APP_GITHASH" 18 "BOOTLOADER_GITHASH" 19 "VERSION_DEPRECATED" 20 "UDS_PROTOCOL_BOOTCRC" 22 "VARIANTCRC" 25 "PACKAGE_PN_1_7" 26 "PACKAGE_PN_8_14" 27 "PACKAGE_PN_15_20" 29 "PACKAGE_SN_1_7" 30 "PACKAGE_SN_8_14" 31 "SUBCOMPONENT_GITHASH" 255 "END" ;
VAL_ 817 EPAS3P_infoBuildType 0 "UNKNOWN_BUILD" 1 "PLATFORM_BUILD" 2 "LOCAL_BUILD" 3 "TRACEABLE_CI_BUILD" 4 "MFG_BUILD" ;
VAL_ 883 EPAS3P_currentTuneMode 0 "DM_COMFORT" 1 "DM_STANDARD" 2 "DM_SPORT" 3 "RWD_COMFORT" 4 "RWD_STANDARD" 5 "RWD_SPORT" ;
VAL_ 883 EPAS3P_eacErrorCode 0 "EAC_ERROR_IDLE" 1 "EAC_ERROR_MIN_SPEED" 2 "EAC_ERROR_MAX_SPEED" 3 "EAC_ERROR_HANDS_ON" 4 "EAC_ERROR_TMP_FAULT" 5 "EAR_ERROR_MAX_STEER_DELTA" 6 "EAC_ERROR_HIGH_ANGLE_REQ" 7 "EAC_ERROR_HIGH_ANGLE_RATE_REQ" 8 "EAC_ERROR_HIGH_ANGLE_SAFETY" 9 "EAC_ERROR_HIGH_ANGLE_RATE_SAFETY" 10 "EAC_ERROR_HIGH_MMOT_SAFETY" 11 "EAC_ERROR_HIGH_TORSION_SAFETY" 12 "EAC_ERROR_LOW_ASSIST" 13 "EAC_ERROR_PINION_VEL_DIFF" 14 "EAC_EXTERNAL_MONITOR_INHIBIT" 15 "SNA" ;
VAL_ 883 EPAS3P_eacStatus 0 "EAC_INHIBITED" 1 "EAC_AVAILABLE" 2 "EAC_ACTIVE" 3 "EAC_FAULT" 4 "LANE_KEEP_ASSIST" 5 "EMERGENCY_LANE_KEEP" 7 "SNA" ;
VAL_ 883 EPAS3P_handsOnLevel 0 "0" 1 "1" 2 "2" 3 "3" ;
VAL_ 883 EPAS3P_internalSASQF 0 "UNDEFINABLE_ACCURACY" 1 "IN_SPEC" ;
VAL_ 883 EPAS3P_steeringFault 0 "NO_FAULT" 1 "FAULT" ;
VAL_ 883 EPAS3P_steeringRackForce 1022 "NOT_IN_SPEC" 1023 "SNA" ;
VAL_ 883 EPAS3P_steeringReduced 0 "NORMAL_ASSIST" 1 "REDUCED_ASSIST" ;
VAL_ 883 EPAS3P_torsionBarTorque 4094 "UNDEFINABLE_DATA" 4095 "SNA" ;
VAL_ 913 EPAS3S_matrixIndex 0 "AlertMatrix0" 1 "AlertMatrix1" 2 "AlertMatrix2" ;
VAL_ 785 EPAS3S_infoIndex 0 "DEPRECATED_0" 1 "DEPRECATED_1" 2 "DEPRECATED_2" 3 "DEPRECATED_3" 4 "DEPRECATED_4" 5 "DEPRECATED_5" 6 "DEPRECATED_6" 7 "DEPRECATED_7" 8 "DEPRECATED_8" 9 "DEPRECATED_9" 10 "BUILD_HWID_COMPONENTID" 11 "PCBAID_ASSYID_USAGEID" 13 "APP_CRC" 14 "BOOTLOADER_SVN" 15 "BOOTLOADER_CRC" 16 "SUBCOMPONENT" 17 "APP_GITHASH" 18 "BOOTLOADER_GITHASH" 19 "VERSION_DEPRECATED" 20 "UDS_PROTOCOL_BOOTCRC" 22 "VARIANTCRC" 25 "PACKAGE_PN_1_7" 26 "PACKAGE_PN_8_14" 27 "PACKAGE_PN_15_20" 29 "PACKAGE_SN_1_7" 30 "PACKAGE_SN_8_14" 31 "SUBCOMPONENT_GITHASH" 255 "END" ;
VAL_ 785 EPAS3S_infoBuildType 0 "UNKNOWN_BUILD" 1 "PLATFORM_BUILD" 2 "LOCAL_BUILD" 3 "TRACEABLE_CI_BUILD" 4 "MFG_BUILD" ;
VAL_ 882 EPAS3S_currentTuneMode 0 "DM_COMFORT" 1 "DM_STANDARD" 2 "DM_SPORT" 3 "RWD_COMFORT" 4 "RWD_STANDARD" 5 "RWD_SPORT" ;
VAL_ 882 EPAS3S_eacErrorCode 0 "EAC_ERROR_IDLE" 1 "EAC_ERROR_MIN_SPEED" 2 "EAC_ERROR_MAX_SPEED" 3 "EAC_ERROR_HANDS_ON" 4 "EAC_ERROR_TMP_FAULT" 5 "EAR_ERROR_MAX_STEER_DELTA" 6 "EAC_ERROR_HIGH_ANGLE_REQ" 7 "EAC_ERROR_HIGH_ANGLE_RATE_REQ" 8 "EAC_ERROR_HIGH_ANGLE_SAFETY" 9 "EAC_ERROR_HIGH_ANGLE_RATE_SAFETY" 10 "EAC_ERROR_HIGH_MMOT_SAFETY" 11 "EAC_ERROR_HIGH_TORSION_SAFETY" 12 "EAC_ERROR_LOW_ASSIST" 13 "EAC_ERROR_PINION_VEL_DIFF" 14 "EAC_EXTERNAL_MONITOR_INHIBIT" 15 "SNA" ;
VAL_ 882 EPAS3S_handsOnLevel 0 "0" 1 "1" 2 "2" 3 "3" ;
VAL_ 882 EPAS3S_internalSASQF 0 "UNDEFINABLE_ACCURACY" 1 "IN_SPEC" ;
VAL_ 882 EPAS3S_steeringFault 0 "NO_FAULT" 1 "FAULT" ;
VAL_ 882 EPAS3S_steeringRackForce 1022 "NOT_IN_SPEC" 1023 "SNA" ;
VAL_ 882 EPAS3S_steeringReduced 0 "NORMAL_ASSIST" 1 "REDUCED_ASSIST" ;
VAL_ 882 EPAS3S_torsionBarTorque 4094 "UNDEFINABLE_DATA" 4095 "SNA" ;
VAL_ 968 EPBL_matrixIndex 0 "AlertMatrix0" 1 "AlertMatrix1" 2 "AlertMatrix2" 3 "AlertMatrix3" 4 "AlertMatrix4" ;
VAL_ 1992 EPBL_infoIndex 0 "DEPRECATED_0" 1 "DEPRECATED_1" 2 "DEPRECATED_2" 3 "DEPRECATED_3" 4 "DEPRECATED_4" 5 "DEPRECATED_5" 6 "DEPRECATED_6" 7 "DEPRECATED_7" 8 "DEPRECATED_8" 9 "DEPRECATED_9" 10 "BUILD_HWID_COMPONENTID" 11 "PCBAID_ASSYID_USAGEID" 13 "APP_CRC" 14 "BOOTLOADER_SVN" 15 "BOOTLOADER_CRC" 16 "SUBCOMPONENT1" 17 "APP_GITHASH" 18 "BOOTLOADER_GITHASH" 19 "VERSION_DEPRECATED" 20 "UDS_PROTOCOL_BOOTCRC" 23 "SUBCOMPONENT2" 24 "SUBCOMPONENT3" 31 "SUBCOMPONENT4" 255 "END" ;
VAL_ 1992 EPBL_infoBuildType 0 "UNKNOWN_BUILD" 1 "PLATFORM_BUILD" 2 "LOCAL_BUILD" 3 "TRACEABLE_CI_BUILD" 4 "MFG_BUILD" ;
VAL_ 1992 EPBL_infoAssemblyId 1 "ASSEMBLY1" 255 "ASSEMBLY_SNA" ;
VAL_ 648 EPBL_csmFaultReason 0 "NONE" 1 "EPBM_DISABLED" 2 "EPBM_FAULTED" 3 "STATE_MISMATCH" 4 "TIMEOUT_CALIBRATE" 5 "APPLY_BLOCKED" 6 "RELEASE_BLOCKED" 7 "TIMEOUT_APPLY_COMPLETE" 8 "TIMEOUT_APPLY_INRUSH" 9 "TIMEOUT_WAIT_FOR_CLAMP" 10 "TIMEOUT_RELEASE_INRUSH" 11 "TIMEOUT_RELEASE_WAIT_FOR_ENDSTOP" 12 "TIMEOUT_RELEASE_COMPLETE" 13 "TIMEOUT_EPBM_CUTOFF" 14 "TIMEOUT_NO_RAMP" 15 "TIMEOUT_EPBM_START" 16 "MOTOR_IDLE_FAULT" 17 "MOTOR_ACTIVE_FAULT" 18 "MOTOR_NOT_READY" 19 "EPBM_MIA" 20 "NVM_MISMATCH" 21 "REMOTE_MIA" ;
VAL_ 648 EPBL_epbmCDPQualified 0 "IDLE" 1 "VALID" 2 "INVALID" ;
VAL_ 648 EPBL_esmCaliperRequest 0 "INVALID" 1 "NONE" 2 "APPLY" 3 "RELEASE" 4 "ENDSTOP" ;
VAL_ 648 EPBL_esmOperationTrigger 0 "PBUTTON_PRESSED_STOPPED" 1 "PBUTTON_PRESSED_OKTOPARK" 2 "PBUTTON_PRESSED_FAST" 3 "PBUTTON_PRESSED_UNKNOWN" 4 "PBUTTON_RELEASED" 5 "ACTIVE_PARK_REQUEST" 6 "DI_UNPARK" 7 "TOUCHSCREEN" 8 "WINCHMODE_EXIT" 9 "WINCHMODE_ENTER" 10 "WINCHMODE_UNAVAILABLE" 11 "SERVICE" 12 "DIAG_CLOSE" 13 "DIAG_OPEN" 14 "DIAG_EXIT" 15 "USER_CONFIRMED" 16 "USER_CANCEL" 17 "SPEED_STOPPED" 18 "SPEED_OKAYTOPARK" 19 "SPEED_FAST" 20 "TIMEOUT" 21 "SAVESTATE_ON_BOOT" 22 "REAPPLY" 23 "SUMMON_COMPLETE" 24 "FAULT" 25 "SUMMON_FAULT" 26 "DISQUALIFIED" 27 "EPBM_DISQUALIFIED" 28 "ACCELERATION" 29 "SYSTEM_APPLY" 30 "DRIVER_IS_LEAVING" ;
VAL_ 648 EPBL_internalCDPRequest 0 "NOT_REQUESTED" 1 "REQUESTED" ;
VAL_ 648 EPBL_summonFaultReason 0 "NONE" 1 "DI_MIA" 2 "DAS_MIA" 3 "ESP_MIA" 4 "EPBM_MIA" 5 "DI_FAULT" 6 "DI_APC_FAULT" 7 "DAS_FAULT" 8 "ESP_FAULT" 9 "VEH_CAN_FAULT" 10 "EAC_NOT_ALLOWED" 11 "EPBM_REQUEST" 12 "SPEED" 13 "EXTERNAL" 14 "PARK_MIA" 15 "PM_MIA" 16 "PM_REQUEST" 17 "OOC" 18 "MISMATCH" 19 "EPB_FAULT" 20 "DI_STATE_INVALID" 21 "PASSIVE_REQUEST" 22 "EPBREMOTE_MIA" 23 "REMOTE_SUMMON_FAULTED" 24 "LOCAL_UNIT_FAULTED" 25 "REMOTE_UNIT_FAULTED" 26 "START_IN_UNAVAILABLE" 27 "INVALID_REMOTE_STATE" 28 "REMOTE_DID_NOT_START" ;
VAL_ 648 EPBL_summonState 0 "INIT" 1 "IDLE" 2 "ARMED" 3 "ACTIVE" 4 "COMPLETE" 5 "FAULT" 6 "UNAVAILABLE" ;
VAL_ 648 EPBL_unitFaultStatus 0 "NOMINAL" 1 "RETRY" 2 "FAULT" 3 "FAULT_IDLE" ;
VAL_ 648 EPBL_unitStatus 0 "UNKNOWN" 1 "OPEN" 2 "DYNAMIC" 3 "PARK" 4 "START" 5 "SERVICE" 6 "WINCHMODE" 7 "WINCHMODE_RELEASING" 8 "PARKING" 9 "DYNAMIC_APPLYING" 10 "RELEASING" 11 "SERVICE_RELEASING" 12 "PARK_PENDING" 13 "WINCHMODE_PENDING" 14 "SUMMON" 15 "SUMMON_RELEASING" 16 "SUMMON_PARKING" 17 "EXTERNAL_DYNAMIC" 18 "RELEASING_FOR_EXTERNAL_PARK" 19 "EXTERNAL_PARKING" 20 "DYNAMIC_PARKING" 21 "COUNT" ;
VAL_ 681 EPBL_brakeDiscWipeRequest 0 "NONE" 1 "LIGHT" 2 "STRONG" 3 "SNA" ;
VAL_ 681 EPBL_cdpRequest 0 "NOT_REQUESTED" 1 "REQUESTED" ;
VAL_ 681 EPBL_systemStatus 0 "UNKNOWN" 1 "RELEASED" 2 "PARKED" 3 "DYNAMIC" 4 "PARKING" 5 "RELEASING" 6 "FAULT" 7 "FAULT_SECURE" 8 "MISMATCH" ;
VAL_ 1000 EPBR_matrixIndex 0 "AlertMatrix0" 1 "AlertMatrix1" 2 "AlertMatrix2" 3 "AlertMatrix3" 4 "AlertMatrix4" ;
VAL_ 2024 EPBR_infoIndex 0 "DEPRECATED_0" 1 "DEPRECATED_1" 2 "DEPRECATED_2" 3 "DEPRECATED_3" 4 "DEPRECATED_4" 5 "DEPRECATED_5" 6 "DEPRECATED_6" 7 "DEPRECATED_7" 8 "DEPRECATED_8" 9 "DEPRECATED_9" 10 "BUILD_HWID_COMPONENTID" 11 "PCBAID_ASSYID_USAGEID" 13 "APP_CRC" 14 "BOOTLOADER_SVN" 15 "BOOTLOADER_CRC" 16 "SUBCOMPONENT1" 17 "APP_GITHASH" 18 "BOOTLOADER_GITHASH" 19 "VERSION_DEPRECATED" 20 "UDS_PROTOCOL_BOOTCRC" 23 "SUBCOMPONENT2" 24 "SUBCOMPONENT3" 31 "SUBCOMPONENT4" 255 "END" ;
VAL_ 2024 EPBR_infoBuildType 0 "UNKNOWN_BUILD" 1 "PLATFORM_BUILD" 2 "LOCAL_BUILD" 3 "TRACEABLE_CI_BUILD" 4 "MFG_BUILD" ;
VAL_ 2024 EPBR_infoAssemblyId 1 "ASSEMBLY1" 255 "ASSEMBLY_SNA" ;
VAL_ 552 EPBR_csmFaultReason 0 "NONE" 1 "EPBM_DISABLED" 2 "EPBM_FAULTED" 3 "STATE_MISMATCH" 4 "TIMEOUT_CALIBRATE" 5 "APPLY_BLOCKED" 6 "RELEASE_BLOCKED" 7 "TIMEOUT_APPLY_COMPLETE" 8 "TIMEOUT_APPLY_INRUSH" 9 "TIMEOUT_WAIT_FOR_CLAMP" 10 "TIMEOUT_RELEASE_INRUSH" 11 "TIMEOUT_RELEASE_WAIT_FOR_ENDSTOP" 12 "TIMEOUT_RELEASE_COMPLETE" 13 "TIMEOUT_EPBM_CUTOFF" 14 "TIMEOUT_NO_RAMP" 15 "TIMEOUT_EPBM_START" 16 "MOTOR_IDLE_FAULT" 17 "MOTOR_ACTIVE_FAULT" 18 "MOTOR_NOT_READY" 19 "EPBM_MIA" 20 "NVM_MISMATCH" 21 "REMOTE_MIA" ;
VAL_ 552 EPBR_epbmCDPQualified 0 "IDLE" 1 "VALID" 2 "INVALID" ;
VAL_ 552 EPBR_esmCaliperRequest 0 "INVALID" 1 "NONE" 2 "APPLY" 3 "RELEASE" 4 "ENDSTOP" ;
VAL_ 552 EPBR_esmOperationTrigger 0 "PBUTTON_PRESSED_STOPPED" 1 "PBUTTON_PRESSED_OKTOPARK" 2 "PBUTTON_PRESSED_FAST" 3 "PBUTTON_PRESSED_UNKNOWN" 4 "PBUTTON_RELEASED" 5 "ACTIVE_PARK_REQUEST" 6 "DI_UNPARK" 7 "TOUCHSCREEN" 8 "WINCHMODE_EXIT" 9 "WINCHMODE_ENTER" 10 "WINCHMODE_UNAVAILABLE" 11 "SERVICE" 12 "DIAG_CLOSE" 13 "DIAG_OPEN" 14 "DIAG_EXIT" 15 "USER_CONFIRMED" 16 "USER_CANCEL" 17 "SPEED_STOPPED" 18 "SPEED_OKAYTOPARK" 19 "SPEED_FAST" 20 "TIMEOUT" 21 "SAVESTATE_ON_BOOT" 22 "REAPPLY" 23 "SUMMON_COMPLETE" 24 "FAULT" 25 "SUMMON_FAULT" 26 "DISQUALIFIED" 27 "EPBM_DISQUALIFIED" 28 "ACCELERATION" 29 "SYSTEM_APPLY" 30 "DRIVER_IS_LEAVING" ;
VAL_ 552 EPBR_internalCDPRequest 0 "NOT_REQUESTED" 1 "REQUESTED" ;
VAL_ 552 EPBR_summonFaultReason 0 "NONE" 1 "DI_MIA" 2 "DAS_MIA" 3 "ESP_MIA" 4 "EPBM_MIA" 5 "DI_FAULT" 6 "DI_APC_FAULT" 7 "DAS_FAULT" 8 "ESP_FAULT" 9 "VEH_CAN_FAULT" 10 "EAC_NOT_ALLOWED" 11 "EPBM_REQUEST" 12 "SPEED" 13 "EXTERNAL" 14 "PARK_MIA" 15 "PM_MIA" 16 "PM_REQUEST" 17 "OOC" 18 "MISMATCH" 19 "EPB_FAULT" 20 "DI_STATE_INVALID" 21 "PASSIVE_REQUEST" 22 "EPBREMOTE_MIA" 23 "REMOTE_SUMMON_FAULTED" 24 "LOCAL_UNIT_FAULTED" 25 "REMOTE_UNIT_FAULTED" 26 "START_IN_UNAVAILABLE" 27 "INVALID_REMOTE_STATE" 28 "REMOTE_DID_NOT_START" ;
VAL_ 552 EPBR_summonState 0 "INIT" 1 "IDLE" 2 "ARMED" 3 "ACTIVE" 4 "COMPLETE" 5 "FAULT" 6 "UNAVAILABLE" ;
VAL_ 552 EPBR_unitFaultStatus 0 "NOMINAL" 1 "RETRY" 2 "FAULT" 3 "FAULT_IDLE" ;
VAL_ 552 EPBR_unitStatus 0 "UNKNOWN" 1 "OPEN" 2 "DYNAMIC" 3 "PARK" 4 "START" 5 "SERVICE" 6 "WINCHMODE" 7 "WINCHMODE_RELEASING" 8 "PARKING" 9 "DYNAMIC_APPLYING" 10 "RELEASING" 11 "SERVICE_RELEASING" 12 "PARK_PENDING" 13 "WINCHMODE_PENDING" 14 "SUMMON" 15 "SUMMON_RELEASING" 16 "SUMMON_PARKING" 17 "EXTERNAL_DYNAMIC" 18 "RELEASING_FOR_EXTERNAL_PARK" 19 "EXTERNAL_PARKING" 20 "DYNAMIC_PARKING" 21 "COUNT" ;
VAL_ 744 EPBR_brakeDiscWipeRequest 0 "NONE" 1 "LIGHT" 2 "STRONG" 3 "SNA" ;
VAL_ 744 EPBR_cdpRequest 0 "NOT_REQUESTED" 1 "REQUESTED" ;
VAL_ 744 EPBR_systemStatus 0 "UNKNOWN" 1 "RELEASED" 2 "PARKED" 3 "DYNAMIC" 4 "PARKING" 5 "RELEASING" 6 "FAULT" 7 "FAULT_SECURE" 8 "MISMATCH" ;
VAL_ 981 ESP_matrixIndex 0 "AlertMatrix0" 1 "AlertMatrix1" 2 "AlertMatrix2" 3 "AlertMatrix3" 4 "AlertMatrix4" ;
VAL_ 808 ESP_infoIndex 0 "DEPRECATED_0" 1 "DEPRECATED_1" 2 "DEPRECATED_2" 3 "DEPRECATED_3" 4 "DEPRECATED_4" 5 "DEPRECATED_5" 6 "DEPRECATED_6" 7 "DEPRECATED_7" 8 "DEPRECATED_8" 9 "DEPRECATED_9" 10 "BUILD_HWID_COMPONENTID" 11 "PCBAID_ASSYID_USAGEID" 13 "APP_CRC" 14 "BOOTLOADER_SVN" 15 "BOOTLOADER_CRC" 16 "SUBCOMPONENT" 17 "APP_GITHASH" 18 "BOOTLOADER_GITHASH" 19 "VERSION_DEPRECATED" 20 "UDS_PROTOCOL_BOOTCRC" 22 "VARIANTCRC" 25 "PACKAGE_PN_1_7" 26 "PACKAGE_PN_8_14" 27 "PACKAGE_PN_15_20" 29 "PACKAGE_SN_1_7" 30 "PACKAGE_SN_8_14" 31 "SUBCOMPONENT_GITHASH" 255 "END" ;
VAL_ 808 ESP_infoBuildType 0 "UNKNOWN_BUILD" 1 "PLATFORM_BUILD" 2 "LOCAL_BUILD" 3 "TRACEABLE_CI_BUILD" 4 "MFG_BUILD" ;
VAL_ 808 ESP_infoVehicleVariant 1 "01" 2 "02" 3 "03" 4 "04" 5 "05" 6 "06" 7 "07" 8 "08" 9 "09" ;
VAL_ 325 ESP_absBrakeEvent2 0 "NOT_ACTIVE" 1 "ACTIVE_FRONT_REAR" 2 "ACTIVE_FRONT" 3 "ACTIVE_REAR" ;
VAL_ 325 ESP_absFaultLamp 0 "OFF" 1 "ON" ;
VAL_ 325 ESP_brakeApply 0 "INACTIVE" 1 "ACTIVE" ;
VAL_ 325 ESP_brakeDiscWipingActive 0 "INACTIVE" 1 "ACTIVE" ;
VAL_ 325 ESP_brakeLamp 0 "OFF" 1 "ON" ;
VAL_ 325 ESP_brakeTorqueTarget 8191 "SNA" ;
VAL_ 325 ESP_btcTargetState 0 "OFF" 1 "BACKUP" 2 "ON" 3 "SNA" ;
VAL_ 325 ESP_cdpStatus 0 "CDP_IS_NOT_AVAILABLE" 1 "CDP_IS_AVAILABLE" 2 "ACTUATING_EPB_CDP" 3 "CDP_COMMAND_INVALID" ;
VAL_ 325 ESP_driverBrakeApply 0 "NotInit_orOff" 1 "Not_Applied" 2 "Driver_applying_brakes" 3 "Faulty_SNA" ;
VAL_ 325 ESP_ebdFaultLamp 0 "OFF" 1 "ON" ;
VAL_ 325 ESP_ebrStandstillSkid 0 "NO_STANDSTILL_SKID" 1 "STANDSTILL_SKID_DETECTED" ;
VAL_ 325 ESP_ebrStatus 0 "EBR_IS_NOT_AVAILABLE" 1 "EBR_IS_AVAILABLE" 2 "ACTUATING_DI_EBR" 3 "EBR_COMMAND_INVALID" ;
VAL_ 325 ESP_espFaultLamp 0 "OFF" 1 "ON" ;
VAL_ 325 ESP_espLampFlash 0 "OFF" 1 "FLASH" ;
VAL_ 325 ESP_espModeActive 0 "00_NORMAL" 1 "01" 2 "02" 3 "03" ;
VAL_ 325 ESP_lateralAccelQF 0 "UNDEFINABLE_ACCURACY" 1 "IN_SPEC" ;
VAL_ 325 ESP_longitudinalAccelQF 0 "UNDEFINABLE_ACCURACY" 1 "IN_SPEC" ;
VAL_ 325 ESP_ptcTargetState 0 "FAULT" 1 "BACKUP" 2 "ON" 3 "SNA" ;
VAL_ 325 ESP_stabilityControlSts2 0 "INIT" 1 "ON" 2 "ENGAGED" 3 "FAULTED" ;
VAL_ 325 ESP_steeringAngleQF 0 "UNDEFINABLE_ACCURACY" 1 "IN_SPEC" ;
VAL_ 325 ESP_yawRateQF 0 "UNDEFINABLE_ACCURACY" 1 "IN_SPEC" ;
VAL_ 341 ESP_wheelRotationRR 3 "UNKNOWN" 2 "STANDSTILL" 1 "BACKWARD" 0 "FORWARD" ;
VAL_ 341 ESP_wheelRotationRL 3 "UNKNOWN" 2 "STANDSTILL" 1 "BACKWARD" 0 "FORWARD" ;
VAL_ 341 ESP_wheelRotationFR 3 "UNKNOWN" 2 "STANDSTILL" 1 "BACKWARD" 0 "FORWARD" ;
VAL_ 341 ESP_wheelRotationFL 3 "UNKNOWN" 2 "STANDSTILL" 1 "BACKWARD" 0 "FORWARD" ;
VAL_ 341 ESP_wheelRotationQF 1 "VALID" 0 "INVALID" ;
VAL_ 341 ESP_standstillStatus 1 "STANDSTILL" 0 "ROLLING" ;
VAL_ 341 ESP_vehicleSpeed 1023 "SNA" ;
VAL_ 373 ESP_wheelSpeedRR 8191 "SNA" ;
VAL_ 373 ESP_wheelSpeedRL 8191 "SNA" ;
VAL_ 373 ESP_wheelSpeedFR 8191 "SNA" ;
VAL_ 373 ESP_wheelSpeedFL 8191 "SNA" ;
VAL_ 389 ESP_brakeTorqueFL 4095 "SNA" ;
VAL_ 389 ESP_brakeTorqueFR 4095 "SNA" ;
VAL_ 389 ESP_brakeTorqueRL 4095 "SNA" ;
VAL_ 389 ESP_brakeTorqueRR 4095 "SNA" ;
VAL_ 389 ESP_brakeTorqueQF 1 "IN_SPEC" 0 "UNDEFINABLE_ACCURACY" ;
VAL_ 1310 FC_infoIndex 0 "DEPRECATED_0_FC" 1 "DEPRECATED_1_FC" 2 "DEPRECATED_2_FC" 3 "DEPRECATED_3_FC" 4 "DEPRECATED_4_FC" 5 "DEPRECATED_5_FC" 6 "DEPRECATED_6_FC" 7 "DEPRECATED_7_FC" 8 "DEPRECATED_8_FC" 9 "DEPRECATED_9_FC" 10 "BUILD_HWID_COMPONENTID_FC" 11 "PCBAID_ASSYID_USAGEID_FC" 13 "APP_CRC_FC" 14 "BOOTLOADER_SVN_FC" 15 "BOOTLOADER_CRC_FC" 16 "SUBCOMPONENT_FC" 17 "APP_GITHASH_FC" 18 "BOOTLOADER_GITHASH_FC" 19 "VERSION_DEPRECATED_FC" 20 "UDS_PROTOCOL_BOOTCRC_FC" 22 "VARIANT_CRC_FC" 25 "PART_NUM_1" 26 "PART_NUM_2" 27 "PART_NUM_3" 255 "END_FC" ;
VAL_ 1310 FC_infoBuildType 0 "UNKNOWN_BUILD_FC" 1 "PLATFORM_BUILD_FC" 2 "LOCAL_BUILD_FC" 3 "TRACEABLE_CI_BUILD_FC" 4 "MFG_BUILD_FC" ;
VAL_ 532 FC_postID 0 "MASTER" 1 "SLAVE" 2 "ID_2" 3 "ID_SNA" ;
VAL_ 532 FC_statusCode 0 "NOTREADY_SNA" 1 "READY" 2 "UPDATE_IN_PROGRESS" 3 "UNUSED_3" 4 "WAIT_POST_READY_TO_CHARGE" 5 "INT_ISOACTIVE" 6 "EXT_ISOACTIVE" 7 "POST_OUT_OF_SERVICE" 13 "NOTCOMPATIBLE" 14 "MALFUNCTION" 15 "NODATA" ;
VAL_ 532 FC_type 0 "SUPERCHARGER" 1 "CHADEMO" 2 "GB" 3 "CC_EVSE" 4 "COMBO" 5 "MC_EVSE" 6 "OTHER" 7 "SNA" ;
VAL_ 533 FC_externalIsolationResistance 255 "SNA" ;
VAL_ 535 FC_status3DataSelect 0 "Mux0" ;
VAL_ 535 FC_class 0 "SNA" 1 "SUPERCHARGER" 2 "URBANCHARGER" ;
VAL_ 535 FC_brand 0 "SNA" 1 "TESLA" ;
VAL_ 535 FC_coolingType 0 "SNA" 1 "CONVECTION" 2 "LIQUID" ;
VAL_ 535 FC_uiStopType 0 "SNA" 1 "TOGGLE" 2 "MOMENTARY" ;
VAL_ 274 GTW_1V1_VEH 4095 "SNA" ;
VAL_ 274 GTW_1V5_VEH 4095 "SNA" ;
VAL_ 274 GTW_3V3_VEH 4095 "SNA" ;
VAL_ 274 GTW_3V3_SW 4095 "SNA" ;
VAL_ 274 GTW_5V0_SW 4095 "SNA" ;
VAL_ 275 GTW_12V0_DISP 16383 "SNA" ;
VAL_ 275 GTW_1V1_FPD 4095 "SNA" ;
VAL_ 275 GTW_1V8_GSM 4095 "SNA" ;
VAL_ 275 GTW_GSM_MDM_VNDR 4095 "SNA" ;
VAL_ 276 GTW_1V2_CSI 4095 "SNA" ;
VAL_ 276 GTW_1V8_VID 4095 "SNA" ;
VAL_ 276 GTW_1V8_VIO 4095 "SNA" ;
VAL_ 276 GTW_3V3_BMP 4095 "SNA" ;
VAL_ 276 GTW_GSM_BRD_REV 4095 "SNA" ;
VAL_ 62 GTW_matrixIndex 0 "AlertMatrix0" 1 "AlertMatrix1" ;
VAL_ 904 GTW_CH_faultConfinement 0 "ERROR_ACTIVE" 1 "ERROR_PASSIVE" 2 "BUS_OFF" ;
VAL_ 904 GTW_PARTY_faultConfinement 0 "ERROR_ACTIVE" 1 "ERROR_PASSIVE" 2 "BUS_OFF" ;
VAL_ 904 GTW_VEH_faultConfinement 0 "ERROR_ACTIVE" 1 "ERROR_PASSIVE" 2 "BUS_OFF" ;
VAL_ 2047 GTW_CabinBlowerCtrlType 0 "LV8907" 1 "TMS320F28027F" ;
VAL_ 2047 GTW_activeHighBeam 0 "NOT_ACTIVE" 1 "ACTIVE" ;
VAL_ 2047 GTW_airSuspension 0 "NONE" 1 "TESLA_STANDARD" ;
VAL_ 2047 GTW_airbagCutoffSwitch 0 "DISABLED" 1 "ENABLED" ;
VAL_ 2047 GTW_audioType 0 "BASE" 1 "PREMIUM" ;
VAL_ 2047 GTW_autopilot 0 "NONE" 1 "HIGHWAY" 2 "ENHANCED" 3 "SELF_DRIVING" ;
VAL_ 2047 GTW_auxParkLamps 0 "NOT_INSTALLED" 1 "INSTALLED" ;
VAL_ 2047 GTW_brakeHWType 0 "MANDO_43MOC" 1 "BREMBO_44MOC" ;
VAL_ 2047 GTW_brakeLineSwitchType 0 "DI_VC_SHARED" 1 "VC_ONLY" ;
VAL_ 2047 GTW_drivetrainType 0 "RWD" 1 "AWD" ;
VAL_ 2047 GTW_eBuckConfig 0 "NONE" 1 "DEV_BUCK" ;
VAL_ 2047 GTW_eCallEnabled 0 "DISABLED" 1 "ENABLED_OHC_SOS" 2 "ENABLED_UI_SOS" ;
VAL_ 2047 GTW_epasType 0 "MANDO_VGR69_GEN3" ;
VAL_ 2047 GTW_exteriorColor 0 "RED_MULTICOAT" 1 "SOLID_BLACK" 2 "SILVER_METALLIC" 3 "MIDNIGHT_SILVER" 5 "DEEP_BLUE" 6 "PEARL_WHITE" ;
VAL_ 2047 GTW_frontFogLamps 0 "NOT_INSTALLED" 1 "INSTALLED" ;
VAL_ 2047 GTW_frontSeatHeaters 0 "NONE" 1 "KONGSBERG_LOW_POWER" ;
VAL_ 2047 GTW_frontSeatType 0 "BASE" 1 "PREMIUM" ;
VAL_ 2047 GTW_headlamps 0 "BASE" 1 "PREMIUM" ;
VAL_ 2047 GTW_heatedWipers 0 "FALSE" 1 "TRUE" ;
VAL_ 2047 GTW_homelinkType 0 "NONE" 1 "HOMELINK_V_OPT_2" ;
VAL_ 2047 GTW_hvacPanelVaneType 0 "PARALLEL_V1" 1 "CONVERGENT_V1" ;
VAL_ 2047 GTW_hvacQuietSnorkelType 0 "DEFAULT" 1 "QUIET_V1" ;
VAL_ 2047 GTW_ibstWakeType 0 "NONE" 1 "WAKE_PIN_20" ;
VAL_ 2047 GTW_interiorLighting 0 "BASE" 1 "PREMIUM" ;
VAL_ 2047 GTW_intrusionSensorType 0 "NOT_INSTALLED" 1 "VODAFONE" ;
VAL_ 2047 GTW_lumbarECUType 0 "NONE" 1 "ALFMEIER" ;
VAL_ 2047 GTW_m3FrontOverheadConsoleType 1 "BITRON" 0 "VALEO" ;
VAL_ 2047 GTW_memoryMirrors 0 "NOT_INSTALLED" 1 "SMR" ;
VAL_ 2047 GTW_numberHVILNodes 0 "0" 1 "1" 2 "2" 3 "3" 4 "4" 5 "5" ;
VAL_ 2047 GTW_packEnergy 0 "50_KWH" 1 "74_KWH" ;
VAL_ 2047 GTW_packMassDeviation 0 "NO_DEVIATION" 1 "PACK_DEVIATION_1" ;
VAL_ 2047 GTW_passengerAirbagType 2 "EUROW" 0 "FULL_SUPPRESSION" 1 "SAFETY_VENT" ;
VAL_ 2047 GTW_pedestrianWarningSound 0 "NONE" 1 "SPEAKER" ;
VAL_ 2047 GTW_performancePackage 0 "BASE" 1 "PERFORMANCE" ;
VAL_ 2047 GTW_powerSteeringColumn 0 "NOT_INSTALLED" 1 "TK" ;
VAL_ 2047 GTW_rearFogLamps 0 "NOT_INSTALLED" 1 "INSTALLED" ;
VAL_ 2047 GTW_rearGlassType 0 "NX" 1 "TSA5_NOPET" ;
VAL_ 2047 GTW_rearSeatHeaters 0 "NONE" 1 "KONGSBERG_LOW_POWER" ;
VAL_ 2047 GTW_restraintsHardwareType 21 "NA" 22 "EUROW_ECALL" 23 "EUROW_NO_ECALL" ;
VAL_ 2047 GTW_rightHandDrive 0 "LEFT" 1 "RIGHT" ;
VAL_ 2047 GTW_roofType 0 "METAL" 1 "FIXED_GLASS" 2 "PANORAMIC" ;
VAL_ 2047 GTW_spoilerType 0 "NOT_INSTALLED" 1 "PASSIVE" ;
VAL_ 2047 GTW_superchargingAccess 0 "NOT_ALLOWED" 1 "ALLOWED" 2 "PAY_AS_YOU_GO" ;
VAL_ 2047 GTW_vdcType 0 "BOSCH_VDC" 1 "TESLA_VDC" ;
VAL_ 2047 GTW_wheelType 0 "PINWHEEL_18" 1 "STILETTO_19" 2 "STILETTO_20" ;
VAL_ 2047 GTW_windshieldType 0 "SEKISUI_ACOUSTIC" 1 "EASTMAN_ACOUSTIC" ;
VAL_ 2047 GTW_xcpESP 0 "FALSE" 1 "TRUE" ;
VAL_ 2047 GTW_xcpIbst 0 "FALSE" 1 "TRUE" ;
VAL_ 1080 GTW_VEHWakeUpReason 0 "NONE" 1 "RESET" 2 "GSM_RI" 3 "CH_CAN" 4 "VEH_CAN" 5 "VEH_CAN" 6 "VCFRONT" 7 "RTC_ALARM" 8 "UI_SCHEDULED" ;
VAL_ 2033 GTW_hrlIndex 1 "Mux1" 2 "Mux2" ;
VAL_ 2033 GTW_hrlState 0 "DISABLED" 1 "ENABLED" ;
VAL_ 2033 GTW_hrlTriggerType 0 "UDPAPI" 1 "EVENT" 15 "NONE" ;
VAL_ 2033 GTW_hrlTriggerBus 0 "VEH" 1 "PARTY" 2 "CH" 3 "VEH" 4 "VIRT" ;
VAL_ 60 GTW_infoIndex 0 "DEPRECATED_0" 1 "DEPRECATED_1" 2 "DEPRECATED_2" 3 "DEPRECATED_3" 4 "DEPRECATED_4" 5 "DEPRECATED_5" 6 "DEPRECATED_6" 7 "DEPRECATED_7" 8 "DEPRECATED_8" 9 "DEPRECATED_9" 10 "BUILD_HWID_COMPONENTID" 11 "PCBAID_ASSYID_USAGEID" 13 "APP_CRC" 14 "BOOTLOADER_SVN" 15 "BOOTLOADER_CRC" 16 "SUBCOMPONENT" 17 "APP_GITHASH" 18 "BOOTLOADER_GITHASH" 19 "VERSION_DEPRECATED" 20 "UDS_PROTOCOL_BOOTCRC" 22 "VARIANTCRC" 25 "PACKAGE_PN_1_7" 26 "PACKAGE_PN_8_14" 27 "PACKAGE_PN_15_20" 29 "PACKAGE_SN_1_7" 30 "PACKAGE_SN_8_14" 31 "SUBCOMPONENT_GITHASH" 255 "END" ;
VAL_ 60 GTW_buildType 0 "UNKNOWN_BUILD" 1 "PLATFORM_BUILD" 2 "LOCAL_BUILD" 3 "TRACEABLE_CI_BUILD" 4 "MFG_BUILD" ;
VAL_ 60 GTW_platformType 0 "UNKNOWN" 3 "MODEL3" 255 "END" ;
VAL_ 840 GTW_vehicleVersionMatchStatus 0 "NOT_CALCULATED_YET" 1 "MISMATCHED" 2 "MATCHED" ;
VAL_ 872 GTW_offboardUpdateState 0 "WAITING_FOR_CONNECTION" 1 "WAIT_UPDATE_TRIGGER" 2 "PREPARING" 3 "RUNNING" 4 "CONFIRM_UPDATE" 5 "LATCH_RESULT" ;
VAL_ 872 GTW_offboardUpdateStatus 0 "OK" 1 "FILE_OPEN_ERROR" 2 "UNPLUGGED" 3 "UDS_FAILED" 4 "SUCCESS" 5 "LOST_DIGITAL_COMMS" 6 "NOT_NEEDED" 7 "APPTRIPLE_MISMATCH" ;
VAL_ 1112 GTW_nmKeepAwakeReason 0 "NONE_SNA" 15 "TBD" ;
VAL_ 1112 GTW_nmWakeUpReason 0 "NONE" 1 "RESET" 2 "GSM_RI" 3 "CH_CAN" 4 "VEH_CAN" 5 "VEH_CAN" 6 "VCFRONT" 7 "RTC_ALARM" 8 "UI_SCHEDULED" ;
VAL_ 522 HVP_fcContNegativeState 0 "SNA" 1 "OPEN" 2 "PRECHARGE" 3 "BLOCKED" 4 "PULLED_IN" 5 "OPENING" 6 "ECONOMIZED" 7 "WELDED" ;
VAL_ 522 HVP_fcContPositiveState 0 "SNA" 1 "OPEN" 2 "PRECHARGE" 3 "BLOCKED" 4 "PULLED_IN" 5 "OPENING" 6 "ECONOMIZED" 7 "WELDED" ;
VAL_ 522 HVP_fcContactorSetState 0 "SNA" 1 "OPEN" 2 "CLOSING" 3 "BLOCKED" 4 "OPENING" 5 "CLOSED" 6 "PARTIAL_WELD" 7 "WELDED" 8 "POSITIVE_CLOSED" 9 "NEGATIVE_CLOSED" ;
VAL_ 522 HVP_fcCtrsRequestStatus 0 "NOT_ACTIVE" 1 "ACTIVE" 2 "COMPLETED" ;
VAL_ 522 HVP_hvilStatus 0 "UNKNOWN" 1 "STATUS_OK" 2 "CURRENT_SOURCE_FAULT" 3 "INTERNAL_OPEN_FAULT" 4 "VEHICLE_OPEN_FAULT" 5 "PENTHOUSE_LID_OPEN_FAULT" 6 "UNKNOWN_LOCATION_OPEN_FAULT" 7 "VEHICLE_NODE_FAULT" 8 "NO_12V_SUPPLY" ;
VAL_ 522 HVP_packContNegativeState 0 "SNA" 1 "OPEN" 2 "PRECHARGE" 3 "BLOCKED" 4 "PULLED_IN" 5 "OPENING" 6 "ECONOMIZED" 7 "WELDED" ;
VAL_ 522 HVP_packContPositiveState 0 "SNA" 1 "OPEN" 2 "PRECHARGE" 3 "BLOCKED" 4 "PULLED_IN" 5 "OPENING" 6 "ECONOMIZED" 7 "WELDED" ;
VAL_ 522 HVP_packContactorSetState 0 "SNA" 1 "OPEN" 2 "CLOSING" 3 "BLOCKED" 4 "OPENING" 5 "CLOSED" 6 "PARTIAL_WELD" 7 "WELDED" 8 "POSITIVE_CLOSED" 9 "NEGATIVE_CLOSED" ;
VAL_ 522 HVP_packCtrsRequestStatus 0 "NOT_ACTIVE" 1 "ACTIVE" 2 "COMPLETED" ;
VAL_ 1962 HVP_debugMessageMultiplexer 0 "Mux0" 1 "Mux1" 2 "Mux2" 3 "Mux3" 4 "Mux4" 5 "Mux5" 6 "Mux6" ;
VAL_ 1962 HVP_shuntAsicTempDbg -32768 "SNA" ;
VAL_ 1962 HVP_shuntAsicTempStatus 1 "INVALID" 0 "NOT_AVAILABLE" 3 "STALE" 2 "VALID" ;
VAL_ 1962 HVP_shuntAuxCurrentStatus 1 "INVALID" 0 "NOT_AVAILABLE" 3 "STALE" 2 "VALID" ;
VAL_ 1962 HVP_shuntBarTempDbg -32768 "SNA" ;
VAL_ 1962 HVP_shuntBarTempStatus 1 "INVALID" 0 "NOT_AVAILABLE" 3 "STALE" 2 "VALID" ;
VAL_ 784 HVP_infoIndex 0 "DEPRECATED_0" 1 "DEPRECATED_1" 2 "DEPRECATED_2" 3 "DEPRECATED_3" 4 "DEPRECATED_4" 5 "DEPRECATED_5" 6 "DEPRECATED_6" 7 "DEPRECATED_7" 8 "DEPRECATED_8" 9 "DEPRECATED_9" 10 "BUILD_HWID_COMPONENTID" 11 "PCBAID_ASSYID_USAGEID" 13 "APP_CRC" 14 "BOOTLOADER_SVN" 15 "BOOTLOADER_CRC" 16 "SUBCOMPONENT" 17 "APP_GITHASH" 18 "BOOTLOADER_GITHASH" 19 "VERSION_DEPRECATED" 20 "UDS_PROTOCOL_BOOTCRC" 22 "VARIANTCRC" 25 "PACKAGE_PN_1_7" 26 "PACKAGE_PN_8_14" 27 "PACKAGE_PN_15_20" 29 "PACKAGE_SN_1_7" 30 "PACKAGE_SN_8_14" 31 "SUBCOMPONENT_GITHASH" 255 "END" ;
VAL_ 784 HVP_buildType 0 "UNKNOWN_BUILD" 1 "PLATFORM_BUILD" 2 "LOCAL_BUILD" 3 "TRACEABLE_CI_BUILD" 4 "MFG_BUILD" ;
VAL_ 1898 HVP_ecuLogUploadRequest 0 "NONE" 1 "1" 2 "2" 3 "3" ;
VAL_ 1898 HVP_vehicleDebugMultiplexer 0 "Mux0" 1 "Mux1" 2 "Mux2" ;
